VERSION "dbc-export 1 2026.26.6.5"

NS_ :

BS_:

BU_: BB GTW IDB TCU TCU2 UI UIS VCSEAT2L VCSEAT2R

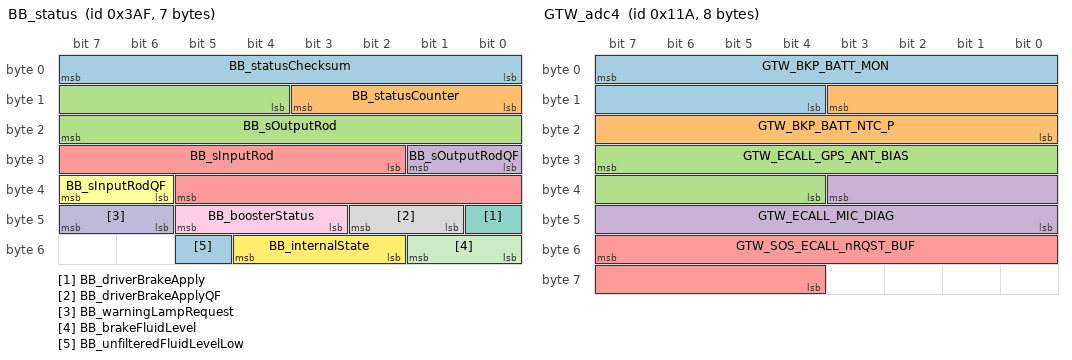
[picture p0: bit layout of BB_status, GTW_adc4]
BO_ 943 BB_status: 7 BB
 SG_ BB_statusChecksum : 0|8@1+ (1,0) [0|255] "" Vector__XXX
 SG_ BB_statusCounter : 8|4@1+ (1,0) [0|15] "" Vector__XXX
 SG_ BB_sOutputRod : 12|12@1+ (0.015625,-5) [-5|47] "mm" Vector__XXX
 SG_ BB_sOutputRodQF : 24|2@1+ (1,0) [0|3] "" Vector__XXX
 SG_ BB_sInputRod : 26|12@1+ (0.015625,-5) [-5|47] "mm" Vector__XXX
 SG_ BB_sInputRodQF : 38|2@1+ (1,0) [0|3] "" Vector__XXX
 SG_ BB_driverBrakeApply : 40|1@1+ (1,0) [0|1] "" Vector__XXX
 SG_ BB_driverBrakeApplyQF : 41|2@1+ (1,0) [0|3] "" Vector__XXX
 SG_ BB_boosterStatus : 43|3@1+ (1,0) [0|7] "" Vector__XXX
 SG_ BB_warningLampRequest : 46|2@1+ (1,0) [0|3] "" Vector__XXX
 SG_ BB_brakeFluidLevel : 48|2@1+ (1,0) [0|3] "" Vector__XXX
 SG_ BB_internalState : 50|3@1+ (1,0) [0|7] "" Vector__XXX
 SG_ BB_unfilteredFluidLevelLow : 53|1@1+ (1,0) [0|1] "" Vector__XXX

BO_ 888 GTW_ECall: 1 GTW
 SG_ GTW_GTW_SOS_ECALL_RQST : 0|1@1+ (1,0) [0|1] "" Vector__XXX
 SG_ GTW_LTE_ECALL_LOCK : 1|1@1+ (1,0) [0|1] "" Vector__XXX

BO_ 282 GTW_adc4: 8 GTW
 SG_ GTW_BKP_BATT_MON : 7|12@0+ (1,0) [0|4094] "mV" Vector__XXX
 SG_ GTW_BKP_BATT_NTC_P : 11|12@0+ (1,0) [0|4094] "mV" Vector__XXX
 SG_ GTW_ECALL_GPS_ANT_BIAS : 31|12@0+ (1,0) [0|4094] "mV" Vector__XXX
 SG_ GTW_ECALL_MIC_DIAG : 35|12@0+ (1,0) [0|4094] "mV" Vector__XXX
 SG_ GTW_SOS_ECALL_nRQST_BUF : 55|12@0+ (1,0) [0|4094] "mV" Vector__XXX

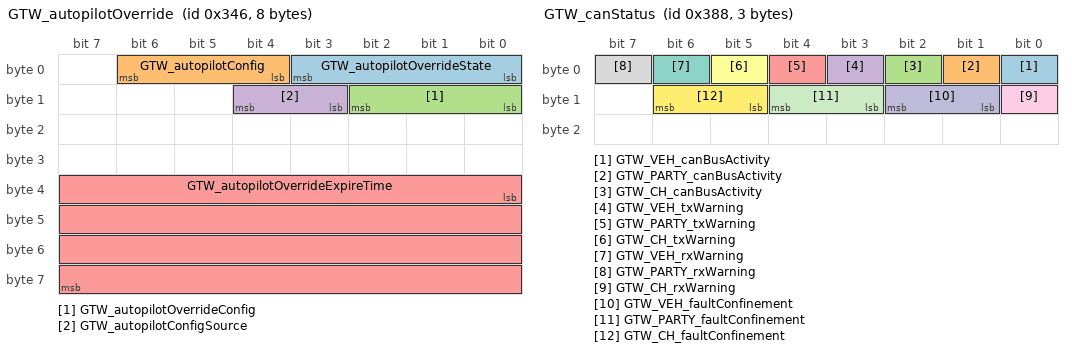
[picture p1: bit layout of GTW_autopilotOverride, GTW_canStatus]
BO_ 838 GTW_autopilotOverride: 8 GTW
 SG_ GTW_autopilotOverrideState : 0|4@1+ (1,0) [0|15] "" Vector__XXX
 SG_ GTW_autopilotConfig : 4|3@1+ (1,0) [0|7] "" Vector__XXX
 SG_ GTW_autopilotOverrideConfig : 8|3@1+ (1,0) [0|7] "" Vector__XXX
 SG_ GTW_autopilotConfigSource : 11|2@1+ (1,0) [0|3] "" Vector__XXX
 SG_ GTW_autopilotOverrideExpireTime : 32|32@1+ (1,0) [0|4294967295] "" Vector__XXX

BO_ 904 GTW_canStatus: 3 GTW
 SG_ GTW_VEH_canBusActivity : 0|1@1+ (1,0) [0|1] "" Vector__XXX
 SG_ GTW_PARTY_canBusActivity : 1|1@1+ (1,0) [0|1] "" Vector__XXX
 SG_ GTW_CH_canBusActivity : 2|1@1+ (1,0) [0|1] "" Vector__XXX
 SG_ GTW_VEH_txWarning : 3|1@1+ (1,0) [0|1] "" Vector__XXX
 SG_ GTW_PARTY_txWarning : 4|1@1+ (1,0) [0|1] "" Vector__XXX
 SG_ GTW_CH_txWarning : 5|1@1+ (1,0) [0|1] "" Vector__XXX
 SG_ GTW_VEH_rxWarning : 6|1@1+ (1,0) [0|1] "" Vector__XXX
 SG_ GTW_PARTY_rxWarning : 7|1@1+ (1,0) [0|1] "" Vector__XXX
 SG_ GTW_CH_rxWarning : 8|1@1+ (1,0) [0|1] "" Vector__XXX
 SG_ GTW_VEH_faultConfinement : 9|2@1+ (1,0) [0|3] "" Vector__XXX
 SG_ GTW_PARTY_faultConfinement : 11|2@1+ (1,0) [0|3] "" Vector__XXX
 SG_ GTW_CH_faultConfinement : 13|2@1+ (1,0) [0|3] "" Vector__XXX

BO_ 2047 GTW_carConfig: 8 GTW
 SG_ GTW_carConfigMultiplexer M : 0|8@1+ (1,0) [0|255] "" Vector__XXX
 SG_ GTW_deliveryStatus m1 : 8|1@1+ (1,0) [0|1] "" Vector__XXX
 SG_ GTW_cabinPTCHeaterType m1 : 10|1@1+ (1,0) [0|1] "" Vector__XXX
 SG_ GTW_rightHandDrive m1 : 11|1@1+ (1,0) [0|1] "" Vector__XXX
 SG_ GTW_rearLightType m1 : 12|2@1+ (1,0) [0|3] "" Vector__XXX
 SG_ GTW_headlamps m1 : 14|2@1+ (1,0) [0|3] "" Vector__XXX
 SG_ GTW_country m1 : 16|16@1+ (1,0) [0|65535] "" Vector__XXX
 SG_ GTW_tireType m1 : 32|6@1+ (1,0) [0|63] "" Vector__XXX
 SG_ GTW_dasHw m1 : 40|3@1+ (1,0) [3|5] "" Vector__XXX
 SG_ GTW_brakeHWType m1 : 43|5@1+ (1,0) [0|31] "" Vector__XXX
 SG_ GTW_restraintsHardwareType m1 : 48|8@1+ (1,0) [0|255] "" Vector__XXX
 SG_ GTW_drivetrainType m1 : 56|4@1+ (1,0) [0|4] "" Vector__XXX
 SG_ GTW_radarHeaterType m1 : 60|3@1+ (1,0) [0|5] "" Vector__XXX
 SG_ GTW_exteriorTrimType m2 : 8|1@1+ (1,0) [0|1] "" Vector__XXX
 SG_ GTW_frontSeatHeaters m2 : 9|1@1+ (1,0) [0|1] "" Vector__XXX
 SG_ GTW_rearSeatHeaters m2 : 10|1@1+ (1,0) [0|1] "" Vector__XXX
 SG_ GTW_eCallAntennaHW m2 : 12|1@1+ (1,0) [0|1] "" Vector__XXX
 SG_ GTW_homelinkType m2 : 13|1@1+ (1,0) [0|1] "" Vector__XXX
 SG_ GTW_vdcType m2 : 14|1@1+ (1,0) [0|1] "" Vector__XXX
 SG_ GTW_memoryMirrors m2 : 17|1@1+ (1,0) [0|1] "" Vector__XXX
 SG_ GTW_powerLiftgateType m2 : 18|2@1+ (1,0) [0|2] "" Vector__XXX
 SG_ GTW_lumbarECUType m2 : 20|4@1+ (1,0) [0|15] "" Vector__XXX
 SG_ GTW_rearSeatHeaterType m2 : 24|2@1+ (1,0) [0|3] "" Vector__XXX
 SG_ GTW_auxParkLamps m2 : 26|2@1+ (1,0) [0|3] "" Vector__XXX
 SG_ GTW_interiorCabinRadarType m2 : 28|1@1+ (1,0) [0|1] "" Vector__XXX
 SG_ GTW_hvacPanelVaneType m2 : 29|1@1+ (1,0) [0|1] "" Vector__XXX
 SG_ GTW_intakeAirFilterType m2 : 30|2@1+ (1,0) [0|2] "" Vector__XXX
 SG_ GTW_eBuckConfig m2 : 32|1@1+ (1,0) [0|1] "" Vector__XXX
 SG_ GTW_steeringHeaterEnabled m2 : 33|1@1+ (1,0) [0|1] "" Vector__XXX
 SG_ GTW_activeHighBeam m2 : 34|1@1+ (1,0) [0|1] "" Vector__XXX
 SG_ GTW_airbagCutoffSwitch m2 : 35|1@1+ (1,0) [0|1] "" Vector__XXX
 SG_ GTW_intrusionSensorType m2 : 36|1@1+ (1,0) [0|1] "" Vector__XXX
 SG_ GTW_spoilerType m2 : 37|1@1+ (1,0) [0|1] "" Vector__XXX
 SG_ GTW_backupCameraType m2 : 38|1@1+ (1,0) [0|1] "" Vector__XXX
 SG_ GTW_rearFogLamps m2 : 39|1@1+ (1,0) [0|1] "" Vector__XXX
 SG_ GTW_roofType m2 : 40|1@1+ (1,0) [0|1] "" Vector__XXX
 SG_ GTW_thirdRowSeatType m2 : 41|1@1+ (1,0) [0|1] "" Vector__XXX
 SG_ GTW_autopilot m2 : 42|3@1+ (1,0) [0|7] "" Vector__XXX
 SG_ GTW_superchargingAccess m2 : 45|2@1+ (1,0) [0|3] "" Vector__XXX
 SG_ GTW_exteriorColor m2 : 48|5@1+ (1,0) [0|31] "" Vector__XXX
 SG_ GTW_pedestrianWarningSound m2 : 53|2@1+ (1,0) [0|3] "" Vector__XXX
 SG_ GTW_steeringColumnUJointType m2 : 55|1@1+ (1,0) [0|1] "" Vector__XXX
 SG_ GTW_bPillarNFCParam m2 : 56|1@1+ (1,0) [0|1] "" Vector__XXX
 SG_ GTW_interiorLighting m2 : 57|3@1+ (1,0) [0|7] "" Vector__XXX
 SG_ GTW_headlightLevelerType m2 : 60|2@1+ (1,0) [0|3] "" Vector__XXX
 SG_ GTW_numberHVILNodes m2 : 62|2@1+ (1,0) [0|3] "" Vector__XXX
 SG_ GTW_mapRegion m3 : 8|4@1+ (1,0) [0|15] "" Vector__XXX
 SG_ GTW_performancePackage m3 : 12|3@1+ (1,0) [0|7] "" Vector__XXX
 SG_ GTW_chassisType m3 : 18|4@1+ (1,0) [0|15] "" Vector__XXX
 SG_ GTW_airSuspension m3 : 22|2@1+ (1,0) [0|3] "" Vector__XXX
 SG_ GTW_centerConsoleControllerType m3 : 24|2@1+ (1,0) [0|3] "" Vector__XXX
 SG_ GTW_autopilotCameraType m3 : 26|1@1+ (1,0) [0|1] "" Vector__XXX
 SG_ GTW_connectivityPackage m3 : 27|1@1+ (1,0) [0|1] "" Vector__XXX
 SG_ GTW_plcSupportType m3 : 28|2@1+ (1,0) [0|3] "" Vector__XXX
 SG_ GTW_badgingVersion m3 : 30|2@1+ (1,0) [0|3] "" Vector__XXX
 SG_ GTW_packEnergy m3 : 32|5@1+ (1,0) [0|31] "" Vector__XXX
 SG_ GTW_frontSeatReclinerHardware m3 : 37|2@1+ (1,0) [0|3] "" Vector__XXX
 SG_ GTW_brakeLineSwitchType m3 : 39|1@1+ (1,0) [0|1] "" Vector__XXX
 SG_ GTW_softRange m3 : 42|3@1+ (1,0) [0|7] "" Vector__XXX
 SG_ GTW_refrigerantType m3 : 45|2@1+ (1,0) [0|3] "" Vector__XXX
 SG_ GTW_wheelType m3 : 48|7@1+ (1,0) [0|127] "" Vector__XXX
 SG_ GTW_brakeActuationType m3 : 57|3@1+ (1,0) [0|4] "" Vector__XXX
 SG_ GTW_secondRowSeatType m3 : 60|3@1+ (1,0) [0|7] "" Vector__XXX
 SG_ GTW_secondRowSeatMotorType m3 : 63|1@1+ (1,0) [0|1] "" Vector__XXX
 SG_ GTW_birthday m4 : 8|32@1+ (1,0) [0|4294967295] "" Vector__XXX
 SG_ GTW_eCallEnabled m4 : 40|2@1+ (1,0) [0|3] "" Vector__XXX
 SG_ GTW_parkAssistECUType m4 : 42|2@1+ (1,0) [0|3] "" Vector__XXX
 SG_ GTW_passengerAirbagType m4 : 44|2@1+ (1,0) [0|3] "" Vector__XXX
 SG_ GTW_forwardRadarHw m4 : 46|2@1+ (1,0) [0|2] "" Vector__XXX
 SG_ GTW_frontSeatType m4 : 48|4@1+ (1,0) [0|15] "" Vector__XXX
 SG_ GTW_secondRowDisplayType m4 : 52|1@1+ (1,0) [0|1] "" Vector__XXX
 SG_ GTW_wirelessPhoneChargerType m4 : 53|2@1+ (1,0) [0|3] "" Vector__XXX
 SG_ GTW_ethernetTunerType m4 : 55|2@1+ (1,0) [0|3] "" Vector__XXX
 SG_ GTW_interiorTrimType m4 : 60|4@1+ (1,0) [0|15] "" Vector__XXX
 SG_ GTW_gloveboxUSBType m5 : 8|2@1+ (1,0) [0|3] "" Vector__XXX
 SG_ GTW_coolantPumpType m5 : 10|3@1+ (1,0) [0|7] "" Vector__XXX
 SG_ GTW_epblHwType m5 : 13|4@1+ (1,0) [0|15] "" Vector__XXX
 SG_ GTW_epbrHwType m5 : 17|4@1+ (1,0) [0|15] "" Vector__XXX
 SG_ GTW_blowerMotorType m5 : 21|2@1+ (1,0) [0|3] "" Vector__XXX
 SG_ GTW_powerMirrorFoldType m5 : 24|1@1+ (1,0) [0|1] "" Vector__XXX
 SG_ GTW_frontUsbHubType m5 : 27|3@1+ (1,0) [0|5] "" Vector__XXX
 SG_ GTW_superManifoldType m5 : 30|2@1+ (1,0) [0|3] "" Vector__XXX
 SG_ GTW_rcmLocation m5 : 32|1@1+ (1,0) [0|1] "" Vector__XXX
 SG_ GTW_autopilotExteriorCameraType m5 : 33|1@1+ (1,0) [0|1] "" Vector__XXX
 SG_ GTW_sirenType m5 : 37|1@1+ (1,0) [0|1] "" Vector__XXX
 SG_ GTW_hornType m5 : 38|1@1+ (1,0) [0|1] "" Vector__XXX
 SG_ GTW_passengerTrackMotorType m5 : 40|1@1+ (1,0) [0|1] "" Vector__XXX
 SG_ GTW_steeringColumnMotorType m5 : 42|2@1+ (1,0) [0|3] "" Vector__XXX
 SG_ GTW_refrigACLineType m5 : 48|2@1+ (1,0) [0|3] "" Vector__XXX
 SG_ GTW_refrigFilterType m5 : 50|2@1+ (1,0) [0|3] "" Vector__XXX
 SG_ GTW_diBurnInType m5 : 52|1@1+ (1,0) [0|1] "" Vector__XXX
 SG_ GTW_specialBadgingType m5 : 53|2@1+ (1,0) [0|3] "" Vector__XXX
 SG_ GTW_chassisSubType m5 : 55|3@1+ (1,0) [0|7] "" Vector__XXX
 SG_ GTW_towPackage m5 : 58|2@1+ (1,0) [0|3] "" Vector__XXX
 SG_ GTW_refrigLccType m5 : 60|1@1+ (1,0) [0|1] "" Vector__XXX
 SG_ GTW_restraintControlsType m5 : 61|1@1+ (1,0) [0|1] "" Vector__XXX
 SG_ GTW_caliperColorType m5 : 62|2@1+ (1,0) [0|3] "" Vector__XXX
 SG_ GTW_wiperMotorType m6 : 9|1@1+ (1,0) [0|1] "" Vector__XXX
 SG_ GTW_frontOverheadConsoleType m6 : 10|2@1+ (1,0) [0|3] "" Vector__XXX
 SG_ GTW_shifterType m6 : 12|1@1+ (1,0) [0|1] "" Vector__XXX
 SG_ GTW_compressorType m6 : 13|4@1+ (1,0) [0|15] "" Vector__XXX
 SG_ GTW_twelveVBatteryType m6 : 17|3@1+ (1,0) [0|7] "" Vector__XXX
 SG_ GTW_efuseSWConfig m6 : 20|3@1+ (1,0) [0|7] "" Vector__XXX
 SG_ GTW_tollCollectionModuleType m6 : 23|1@1+ (1,0) [0|1] "" Vector__XXX
 SG_ GTW_bleEndpointUpdateMethod m6 : 24|1@1+ (1,0) [0|1] "" Vector__XXX
 SG_ GTW_steeringWheelControllerType m6 : 25|3@1+ (1,0) [0|7] "" Vector__XXX
 SG_ GTW_frontSeatVentilationEnabled m6 : 28|1@1+ (1,0) [0|1] "" Vector__XXX
 SG_ GTW_gloveboxActuatorType m6 : 29|2@1+ (1,0) [0|3] "" Vector__XXX
 SG_ GTW_epasType m6 : 32|4@1+ (1,0) [0|11] "" Vector__XXX
 SG_ GTW_homologationRegionOverride m6 : 36|2@1+ (1,0) [0|3] "" Vector__XXX
 SG_ GTW_windowCommandsPermissionType m6 : 38|2@1+ (1,0) [0|3] "" Vector__XXX
 SG_ GTW_rgbInteriorLightingEnabled m6 : 43|2@1+ (1,0) [0|3] "" Vector__XXX
 SG_ GTW_windshieldWiperHeaterType m6 : 45|1@1+ (1,0) [0|1] "" Vector__XXX
 SG_ GTW_thirdRowSeatReclinerType m6 : 46|1@1+ (1,0) [0|1] "" Vector__XXX
 SG_ GTW_driveInterfaceType m6 : 47|1@1+ (1,0) [0|1] "" Vector__XXX
 SG_ GTW_efficiencyPackage m6 : 49|6@1+ (1,0) [0|63] "" Vector__XXX
 SG_ GTW_visorLightType m6 : 55|1@1+ (1,0) [0|1] "" Vector__XXX
 SG_ GTW_gnssAntennaType m6 : 58|2@1+ (1,0) [0|3] "" Vector__XXX
 SG_ GTW_airDistributionBoxType m6 : 60|1@1+ (1,0) [0|1] "" Vector__XXX
 SG_ GTW_frontSeatHeatersEnabled m6 : 62|1@1+ (1,0) [0|1] "" Vector__XXX
 SG_ GTW_windshieldWiperHeaterEnabled m6 : 63|1@1+ (1,0) [0|1] "" Vector__XXX
 SG_ GTW_alcoholInterlockType m7 : 8|1@1+ (1,0) [0|1] "" Vector__XXX
 SG_ GTW_fasciaType m7 : 9|4@1+ (1,0) [0|15] "" Vector__XXX
 SG_ GTW_powerSteeringColumn m7 : 13|1@1+ (1,0) [0|1] "" Vector__XXX
 SG_ GTW_frontSeatHeaterType m7 : 14|1@1+ (1,0) [0|1] "" Vector__XXX
 SG_ GTW_softPerformanceLimit m7 : 15|4@1+ (1,0) [0|15] "" Vector__XXX
 SG_ GTW_gsrFeatureType m7 : 21|2@1+ (1,0) [0|2] "" Vector__XXX
 SG_ GTW_immersiveAudio m7 : 23|2@1+ (1,0) [0|3] "" Vector__XXX
 SG_ GTW_frontSeatVentilationType m7 : 25|1@1+ (1,0) [0|1] "" Vector__XXX
 SG_ GTW_passengerOccupancySensorType m7 : 26|3@1+ (1,0) [0|7] "" Vector__XXX
 SG_ GTW_packPerformanceDeviation m7 : 30|3@1+ (1,0) [0|7] "" Vector__XXX
 SG_ GTW_frontFogLamps m7 : 35|1@1+ (1,0) [0|1] "" Vector__XXX
 SG_ GTW_driverOccupancySensorType m7 : 36|1@1+ (1,0) [0|1] "" Vector__XXX
 SG_ GTW_audioType m7 : 37|3@1+ (1,0) [0|7] "" Vector__XXX
 SG_ GTW_thighExtenderType m7 : 41|1@1+ (1,0) [0|1] "" Vector__XXX
 SG_ GTW_occupancyClassificationFeatu m7 : 42|1@1+ (1,0) [0|1] "" Vector__XXX
 SG_ GTW_frontControllerArchitectureT m7 : 46|1@1+ (1,0) [0|1] "" Vector__XXX
 SG_ GTW_domeLightType m7 : 47|2@1+ (1,0) [0|3] "" Vector__XXX
 SG_ GTW_tpmsType m7 : 49|2@1+ (1,0) [0|3] "" Vector__XXX
 SG_ GTW_authenticationEndpointLayout m7 : 52|3@1+ (1,0) [0|6] "" Vector__XXX
 SG_ GTW_socSleepOverride m7 : 57|2@1+ (1,0) [0|3] "" Vector__XXX
 SG_ GTW_r79BehaviorOverride m7 : 59|1@1+ (1,0) [0|1] "" Vector__XXX
 SG_ GTW_steeringHeaterType m7 : 60|3@1+ (1,0) [0|7] "" Vector__XXX
 SG_ GTW_narrowWipingSupported m7 : 63|1@1+ (1,0) [0|1] "" Vector__XXX
 SG_ GTW_frontSeatHeaterGridType m8 : 8|1@1+ (1,0) [0|1] "" Vector__XXX
 SG_ GTW_frontSeatSideSwitchType m8 : 9|1@1+ (1,0) [0|1] "" Vector__XXX
 SG_ GTW_sohRegulatoryStatus m8 : 10|1@1+ (1,0) [0|1] "" Vector__XXX
 SG_ GTW_passengerTiltMotorType m8 : 11|2@1+ (1,0) [0|3] "" Vector__XXX
 SG_ GTW_frunkInteriorReleaseType m8 : 15|1@1+ (1,0) [0|1] "" Vector__XXX
 SG_ GTW_m3yBusArchitecture m8 : 17|2@1+ (1,0) [0|3] "" Vector__XXX
 SG_ GTW_passengerLiftMotorType m8 : 19|2@1+ (1,0) [0|3] "" Vector__XXX
 SG_ GTW_interiorUpperTrimType m8 : 21|1@1+ (1,0) [0|1] "" Vector__XXX
 SG_ GTW_blindSpotIndicatorLightType m8 : 22|2@1+ (1,0) [0|3] "" Vector__XXX
 SG_ GTW_wiperMotorAsicType m8 : 24|2@1+ (1,0) [0|3] "" Vector__XXX
 SG_ GTW_hvacCaseDoorType m8 : 28|1@1+ (1,0) [0|1] "" Vector__XXX
 SG_ GTW_rduCableType m8 : 31|1@1+ (1,0) [0|1] "" Vector__XXX
 SG_ GTW_parkTelltaleBehaviorType m8 : 32|1@1+ (1,0) [0|1] "" Vector__XXX
 SG_ GTW_numberKeyCardsPairedInFactor m8 : 35|2@1+ (1,0) [0|2] "" Vector__XXX
 SG_ GTW_secondRowSeatVentilationType m8 : 37|1@1+ (1,0) [0|1] "" Vector__XXX
 SG_ GTW_thirdRowSeatHeaterType m8 : 38|1@1+ (1,0) [0|1] "" Vector__XXX
 SG_ GTW_interiorCameraType m8 : 39|2@1+ (1,0) [0|2] "" Vector__XXX
 SG_ GTW_frontFasciaCameraType m8 : 41|2@1+ (1,0) [0|3] "" Vector__XXX
 SG_ GTW_interiorCamFanType m8 : 45|3@1+ (1,0) [0|7] "" Vector__XXX
 SG_ GTW_puddleLampType m8 : 50|2@1+ (1,0) [0|2] "" Vector__XXX
 SG_ GTW_solarLensType m8 : 52|2@1+ (1,0) [0|2] "" Vector__XXX
 SG_ GTW_liftgateGeometryType m8 : 56|2@1+ (1,0) [0|3] "" Vector__XXX
 SG_ GTW_repeaterAeroRibType m8 : 60|3@1+ (1,0) [0|7] "" Vector__XXX
 SG_ GTW_highTipForceWiperArmsType m8 : 63|1@1+ (1,0) [0|1] "" Vector__XXX
 SG_ GTW_rcmUndersideAbuseZThreshold m9 : 8|3@1+ (1,0) [0|7] "" Vector__XXX
 SG_ GTW_rcmUndersideAbuseYThreshold m9 : 11|3@1+ (1,0) [0|7] "" Vector__XXX
 SG_ GTW_rcmUndersideAbuseWindow m9 : 14|2@1+ (1,0) [0|3] "" Vector__XXX
 SG_ GTW_automaticFeatureResetPackage m9 : 18|1@1+ (1,0) [0|1] "" Vector__XXX
 SG_ GTW_autopilotFeaturePackage m9 : 20|2@1+ (1,0) [0|2] "" Vector__XXX
 SG_ GTW_doorLatchType m9 : 23|1@1+ (1,0) [0|1] "" Vector__XXX
 SG_ GTW_headlinerMaterialType m9 : 25|2@1+ (1,0) [0|3] "" Vector__XXX
 SG_ GTW_glareShieldHeaterType m9 : 27|1@1+ (1,0) [0|1] "" Vector__XXX
 SG_ GTW_rearLightHardwareVariant m9 : 29|2@1+ (1,0) [0|3] "" Vector__XXX
 SG_ GTW_fasciaHarnessCleanPointType m9 : 31|2@1+ (1,0) [0|3] "" Vector__XXX
 SG_ GTW_epasSubType m9 : 33|1@1+ (1,0) [0|1] "" Vector__XXX
 SG_ GTW_wiperSupplyChainOrigin m9 : 35|2@1+ (1,0) [1|3] "" Vector__XXX
 SG_ GTW_windowPinchParameterType m9 : 37|2@1+ (1,0) [0|3] "" Vector__XXX
 SG_ GTW_badgingMaterialType m9 : 39|1@1+ (1,0) [0|1] "" Vector__XXX
 SG_ GTW_mRecordVersion m9 : 40|1@1+ (1,0) [0|1] "" Vector__XXX
 SG_ GTW_tcuType m9 : 47|2@1+ (1,0) [0|2] "" Vector__XXX
 SG_ GTW_carbComplianceBehaviorType m9 : 49|1@1+ (1,0) [0|1] "" Vector__XXX
 SG_ GTW_indirectTPMSCalibrationType m9 : 55|3@1+ (1,0) [0|7] "" Vector__XXX
 SG_ GTW_v2xEnabled m9 : 58|1@1+ (1,0) [0|1] "" Vector__XXX
 SG_ GTW_liftgateStrutType m9 : 60|1@1+ (1,0) [0|1] "" Vector__XXX
 SG_ GTW_exteriorMicrophoneType m9 : 63|1@1+ (1,0) [0|1] "" Vector__XXX
 SG_ GTW_roofGlassType m10 : 21|3@1+ (1,0) [0|7] "" Vector__XXX
 SG_ GTW_pedalMapNameOverride m10 : 25|1@1+ (1,0) [0|1] "" Vector__XXX

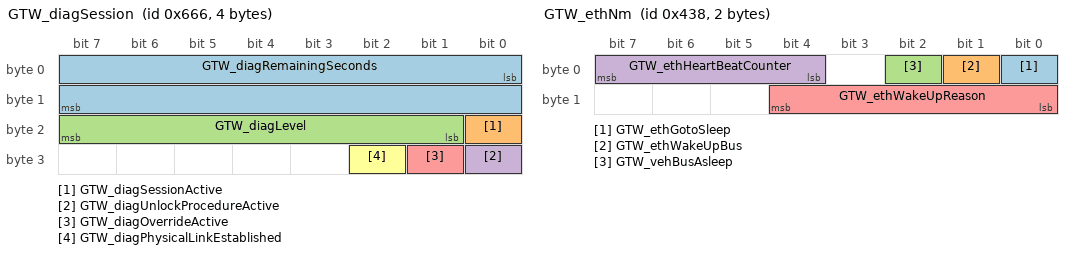
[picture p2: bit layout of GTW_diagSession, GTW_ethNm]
BO_ 1638 GTW_diagSession: 4 GTW
 SG_ GTW_diagRemainingSeconds : 0|16@1+ (1,0) [0|65535] "seconds" Vector__XXX
 SG_ GTW_diagSessionActive : 16|1@1+ (1,0) [0|1] "" Vector__XXX
 SG_ GTW_diagLevel : 17|7@1+ (1,0) [0|127] "" Vector__XXX
 SG_ GTW_diagUnlockProcedureActive : 24|1@1+ (1,0) [0|1] "" Vector__XXX
 SG_ GTW_diagOverrideActive : 25|1@1+ (1,0) [0|1] "" Vector__XXX
 SG_ GTW_diagPhysicalLinkEstablished : 26|1@1+ (1,0) [0|1] "" Vector__XXX

BO_ 1080 GTW_ethNm: 2 GTW
 SG_ GTW_ethGotoSleep : 0|1@1+ (1,0) [0|1] "" Vector__XXX
 SG_ GTW_ethWakeUpBus : 1|1@1+ (1,0) [0|1] "" Vector__XXX
 SG_ GTW_vehBusAsleep : 2|1@1+ (1,0) [0|1] "" Vector__XXX
 SG_ GTW_ethHeartBeatCounter : 4|4@1+ (1,0) [0|15] "" Vector__XXX
 SG_ GTW_ethWakeUpReason : 8|5@1+ (1,0) [0|31] "" Vector__XXX

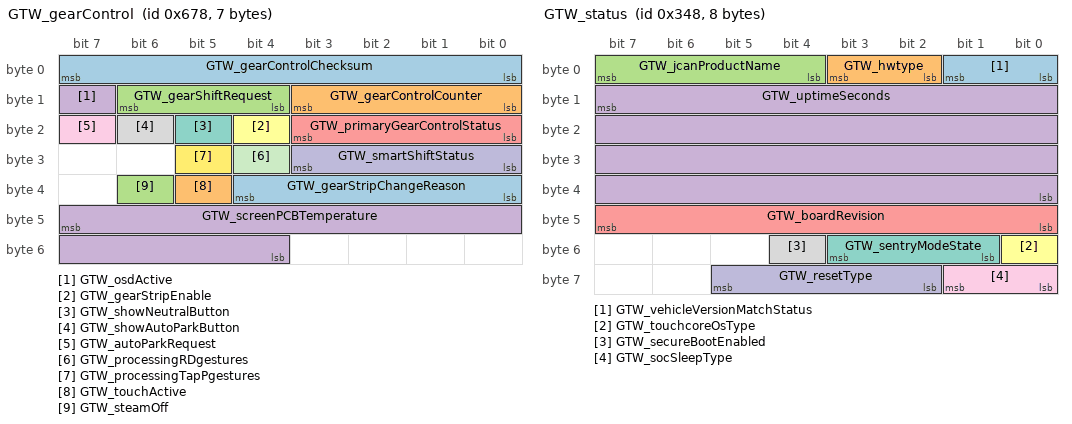
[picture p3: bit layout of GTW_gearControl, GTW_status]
BO_ 1656 GTW_gearControl: 7 GTW
 SG_ GTW_gearControlChecksum : 0|8@1+ (1,0) [0|255] "" Vector__XXX
 SG_ GTW_gearControlCounter : 8|4@1+ (1,0) [0|15] "" Vector__XXX
 SG_ GTW_gearShiftRequest : 12|3@1+ (1,0) [1|7] "" Vector__XXX
 SG_ GTW_osdActive : 15|1@1+ (1,0) [0|1] "" Vector__XXX
 SG_ GTW_primaryGearControlStatus : 16|4@1+ (1,0) [0|15] "" Vector__XXX
 SG_ GTW_gearStripEnable : 20|1@1+ (1,0) [0|1] "" Vector__XXX
 SG_ GTW_showNeutralButton : 21|1@1+ (1,0) [0|1] "" Vector__XXX
 SG_ GTW_showAutoParkButton : 22|1@1+ (1,0) [0|1] "" Vector__XXX
 SG_ GTW_autoParkRequest : 23|1@1+ (1,0) [0|1] "" Vector__XXX
 SG_ GTW_smartShiftStatus : 24|4@1+ (1,0) [1|15] "" Vector__XXX
 SG_ GTW_processingRDgestures : 28|1@1+ (1,0) [0|1] "" Vector__XXX
 SG_ GTW_processingTapPgestures : 29|1@1+ (1,0) [0|1] "" Vector__XXX
 SG_ GTW_gearStripChangeReason : 32|5@1+ (1,0) [1|31] "" Vector__XXX
 SG_ GTW_touchActive : 37|1@1+ (1,0) [0|1] "" Vector__XXX
 SG_ GTW_steamOff : 38|1@1+ (1,0) [0|1] "" Vector__XXX
 SG_ GTW_screenPCBTemperature : 47|12@0- (0.0625,0) [-128|127.875] "degC" Vector__XXX

BO_ 2033 GTW_hrl: 7 GTW
 SG_ GTW_hrlIndex M : 0|2@1+ (1,0) [0|3] "" Vector__XXX
 SG_ GTW_hrlPagesCount m1 : 15|32@0+ (1,0) [0|4294967295] "" Vector__XXX
 SG_ GTW_hrlSdCardSizeGB m1 : 40|8@1+ (1,0) [1|255] "" Vector__XXX
 SG_ GTW_hrlState m2 : 2|1@1+ (1,0) [0|1] "" Vector__XXX
 SG_ GTW_hrlTriggerDuration m2 : 15|16@0+ (1,0) [0|65535] "seconds" Vector__XXX
 SG_ GTW_hrlTriggerType m2 : 24|4@1+ (1,0) [0|15] "" Vector__XXX
 SG_ GTW_hrlTriggerId m2 : 39|16@0+ (1,0) [0|65535] "" Vector__XXX
 SG_ GTW_hrlTriggerBus m2 : 53|3@1+ (1,0) [0|7] "" Vector__XXX

BO_ 2026 GTW_hrlExternalEvent: 8 GTW
 SG_ GTW_hrlEventStartEpoch : 7|32@0+ (1,0) [0|4294967295] "seconds" Vector__XXX
 SG_ GTW_hrlEventEndEpoch : 39|32@0+ (1,0) [0|4294967295] "seconds" Vector__XXX

BO_ 60 GTW_info: 8 GTW
 SG_ GTW_infoIndex M : 0|8@1+ (1,0) [0|255] "" Vector__XXX
 SG_ GTW_buildType m10 : 8|3@1+ (1,0) [0|7] "" Vector__XXX
 SG_ GTW_hardwareId m10 : 32|16@1+ (1,0) [0|65535] "" Vector__XXX
 SG_ GTW_platformType m13 : 8|8@1+ (1,0) [0|255] "" Vector__XXX
 SG_ GTW_appCrc m13 : 32|32@1+ (1,0) [0|4294967295] "" Vector__XXX
 SG_ GTW_applicationGitHash m17 : 8|56@1+ (1,0) [0|7.20575940379e+16] "" Vector__XXX
 SG_ GTW_bootGitHash m18 : 8|56@1+ (1,0) [0|7.20575940379e+16] "" Vector__XXX

BO_ 1370 GTW_mismatchFault: 8 GTW
 SG_ GTW_mismatchFaultIndex M : 0|3@1+ (1,0) [0|7] "" Vector__XXX
 SG_ GTW_mismatchFaultChecksum : 3|8@1+ (1,0) [0|255] "" Vector__XXX
 SG_ GTW_mismatchFaultCounter : 11|4@1+ (1,0) [0|15] "" Vector__XXX
 SG_ GTW_GTWmismatchFault m1 : 15|1@1+ (1,0) [0|1] "" Vector__XXX
 SG_ GTW_BMSmismatchFault m1 : 16|1@1+ (1,0) [0|1] "" Vector__XXX
 SG_ GTW_APSmismatchFault m1 : 17|1@1+ (1,0) [0|1] "" Vector__XXX
 SG_ GTW_BLEEPCENTERmismatchFault m1 : 18|1@1+ (1,0) [0|1] "" Vector__XXX
 SG_ GTW_BLEEPLEFTmismatchFault m1 : 19|1@1+ (1,0) [0|1] "" Vector__XXX
 SG_ GTW_BLEEPREARmismatchFault m1 : 20|1@1+ (1,0) [0|1] "" Vector__XXX
 SG_ GTW_BLEEPRIGHTmismatchFault m1 : 21|1@1+ (1,0) [0|1] "" Vector__XXX
 SG_ GTW_CBCmismatchFault m1 : 22|1@1+ (1,0) [0|1] "" Vector__XXX
 SG_ GTW_CMPmismatchFault m1 : 23|1@1+ (1,0) [0|1] "" Vector__XXX
 SG_ GTW_CPmismatchFault m1 : 24|1@1+ (1,0) [0|1] "" Vector__XXX
 SG_ GTW_DIFmismatchFault m1 : 25|1@1+ (1,0) [0|1] "" Vector__XXX
 SG_ GTW_DIRmismatchFault m1 : 26|1@1+ (1,0) [0|1] "" Vector__XXX
 SG_ GTW_EPAS3PmismatchFault m1 : 27|1@1+ (1,0) [0|1] "" Vector__XXX
 SG_ GTW_EPAS3SmismatchFault m1 : 28|1@1+ (1,0) [0|1] "" Vector__XXX
 SG_ GTW_EPBLmismatchFault m1 : 29|1@1+ (1,0) [0|1] "" Vector__XXX
 SG_ GTW_EPBRmismatchFault m1 : 30|1@1+ (1,0) [0|1] "" Vector__XXX
 SG_ GTW_ESPCALmismatchFault m1 : 31|1@1+ (1,0) [0|1] "" Vector__XXX
 SG_ GTW_ESPmismatchFault m1 : 32|1@1+ (1,0) [0|1] "" Vector__XXX
 SG_ GTW_HCM3LmismatchFault m1 : 33|1@1+ (1,0) [0|1] "" Vector__XXX
 SG_ GTW_HCM3RmismatchFault m1 : 34|1@1+ (1,0) [0|1] "" Vector__XXX
 SG_ GTW_HCMLmismatchFault m1 : 35|1@1+ (1,0) [0|1] "" Vector__XXX
 SG_ GTW_HCMRmismatchFault m1 : 36|1@1+ (1,0) [0|1] "" Vector__XXX
 SG_ GTW_HVPmismatchFault m1 : 37|1@1+ (1,0) [0|1] "" Vector__XXX
 SG_ GTW_IBSTCALmismatchFault m1 : 38|1@1+ (1,0) [0|1] "" Vector__XXX
 SG_ GTW_IBSTmismatchFault m1 : 39|1@1+ (1,0) [0|1] "" Vector__XXX
 SG_ GTW_LVBMSmismatchFault m1 : 40|1@1+ (1,0) [0|1] "" Vector__XXX
 SG_ GTW_OCS1PmismatchFault m1 : 41|1@1+ (1,0) [0|1] "" Vector__XXX
 SG_ GTW_OPCFmismatchFault m1 : 42|1@1+ (1,0) [0|1] "" Vector__XXX
 SG_ GTW_OPCRmismatchFault m1 : 43|1@1+ (1,0) [0|1] "" Vector__XXX
 SG_ GTW_PARKmismatchFault m1 : 44|1@1+ (1,0) [0|1] "" Vector__XXX
 SG_ GTW_PCSCPU2mismatchFault m1 : 45|1@1+ (1,0) [0|1] "" Vector__XXX
 SG_ GTW_PCSmismatchFault m1 : 46|1@1+ (1,0) [0|1] "" Vector__XXX
 SG_ GTW_PMFmismatchFault m1 : 47|1@1+ (1,0) [0|1] "" Vector__XXX
 SG_ GTW_PMRmismatchFault m1 : 48|1@1+ (1,0) [0|1] "" Vector__XXX
 SG_ GTW_PTCmismatchFault m1 : 49|1@1+ (1,0) [0|1] "" Vector__XXX
 SG_ GTW_RCMCALmismatchFault m1 : 50|1@1+ (1,0) [0|1] "" Vector__XXX
 SG_ GTW_RCMmismatchFault m1 : 51|1@1+ (1,0) [0|1] "" Vector__XXX
 SG_ GTW_SCCMmismatchFault m1 : 52|1@1+ (1,0) [0|1] "" Vector__XXX
 SG_ GTW_SDCRmismatchFault m1 : 53|1@1+ (1,0) [0|1] "" Vector__XXX
 SG_ GTW_SWCmismatchFault m1 : 54|1@1+ (1,0) [0|1] "" Vector__XXX
 SG_ GTW_THSmismatchFault m1 : 55|1@1+ (1,0) [0|1] "" Vector__XXX
 SG_ GTW_VCFRONTmismatchFault m1 : 56|1@1+ (1,0) [0|1] "" Vector__XXX
 SG_ GTW_VCLEFTmismatchFault m1 : 57|1@1+ (1,0) [0|1] "" Vector__XXX
 SG_ GTW_VCRIGHTmismatchFault m1 : 58|1@1+ (1,0) [0|1] "" Vector__XXX
 SG_ GTW_VCSECmismatchFault m1 : 59|1@1+ (1,0) [0|1] "" Vector__XXX
 SG_ GTW_PMmismatchFault m1 : 60|1@1+ (1,0) [0|1] "" Vector__XXX

BO_ 840 GTW_status: 8 GTW
 SG_ GTW_vehicleVersionMatchStatus : 0|2@1+ (1,0) [0|3] "" Vector__XXX
 SG_ GTW_hwtype : 2|2@1+ (1,0) [1|3] "" Vector__XXX
 SG_ GTW_jcanProductName : 4|4@1+ (1,0) [1|15] "" Vector__XXX
 SG_ GTW_uptimeSeconds : 15|32@0+ (1,0) [0|4294967295] "s" Vector__XXX
 SG_ GTW_boardRevision : 40|8@1+ (1,0) [0|255] "" Vector__XXX
 SG_ GTW_touchcoreOsType : 48|1@1+ (1,0) [0|1] "" Vector__XXX
 SG_ GTW_sentryModeState : 49|3@1+ (1,0) [0|7] "" Vector__XXX
 SG_ GTW_secureBootEnabled : 52|1@1+ (1,0) [0|1] "" Vector__XXX
 SG_ GTW_socSleepType : 56|2@1+ (1,0) [1|3] "" Vector__XXX
 SG_ GTW_resetType : 58|4@1+ (1,0) [1|15] "" Vector__XXX

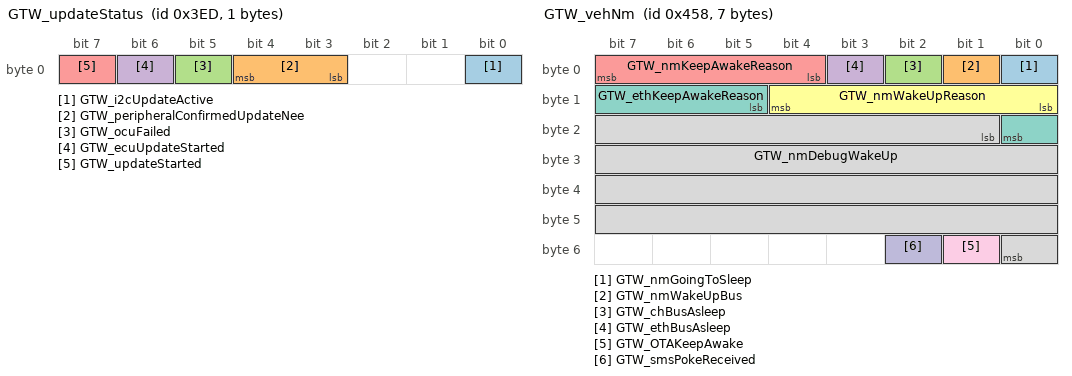
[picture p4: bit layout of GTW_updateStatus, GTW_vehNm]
BO_ 1005 GTW_updateStatus: 1 GTW
 SG_ GTW_i2cUpdateActive : 0|1@1+ (1,0) [0|1] "" Vector__XXX
 SG_ GTW_peripheralConfirmedUpdateNee : 3|2@1+ (1,0) [0|3] "" Vector__XXX
 SG_ GTW_ocuFailed : 5|1@1+ (1,0) [0|1] "" Vector__XXX
 SG_ GTW_ecuUpdateStarted : 6|1@1+ (1,0) [0|1] "" Vector__XXX
 SG_ GTW_updateStarted : 7|1@1+ (1,0) [0|1] "" Vector__XXX

BO_ 1112 GTW_vehNm: 7 GTW
 SG_ GTW_nmGoingToSleep : 0|1@1+ (1,0) [0|1] "" Vector__XXX
 SG_ GTW_nmWakeUpBus : 1|1@1+ (1,0) [0|1] "" Vector__XXX
 SG_ GTW_chBusAsleep : 2|1@1+ (1,0) [0|1] "" Vector__XXX
 SG_ GTW_ethBusAsleep : 3|1@1+ (1,0) [0|1] "" Vector__XXX
 SG_ GTW_nmKeepAwakeReason : 4|4@1+ (1,0) [1|15] "" Vector__XXX
 SG_ GTW_nmWakeUpReason : 8|5@1+ (1,0) [0|31] "" Vector__XXX
 SG_ GTW_ethKeepAwakeReason : 13|4@1+ (1,0) [1|15] "" Vector__XXX
 SG_ GTW_nmDebugWakeUp : 17|32@1+ (1,0) [0|4294967295] "" Vector__XXX
 SG_ GTW_OTAKeepAwake : 49|1@1+ (1,0) [0|1] "" Vector__XXX
 SG_ GTW_smsPokeReceived : 50|1@1+ (1,0) [0|1] "" Vector__XXX

BO_ 828 IDB_info: 8 IDB
 SG_ IDB_infoIndex M : 0|8@1+ (1,0) [0|255] "" Vector__XXX
 SG_ IDB_infoPcbaID m11 : 16|8@1+ (1,0) [0|255] "" Vector__XXX
 SG_ IDB_infoAssemblyID m11 : 24|8@1+ (1,0) [0|255] "" Vector__XXX
 SG_ IDB_infoUsageID m11 : 32|16@1+ (1,0) [0|65535] "" Vector__XXX
 SG_ IDB_infoSubUsageID m11 : 48|16@1+ (1,0) [0|65535] "" Vector__XXX

BO_ 1415 TCU2_SleepConfig: 1 TCU2
 SG_ TCU2_tc10Version : 0|2@1+ (1,0) [1|3] "" Vector__XXX

BO_ 1412 TCU2_log: 8 TCU2
 SG_ TCU2_logMux M : 0|32@1+ (1,0) [0|4294967295] "" Vector__XXX
 SG_ TCU2_cpuTemp m0 : 32|32@1+ (1,0) [0|4294967295] "C" Vector__XXX
 SG_ TCU2_cpuUsage m1 : 32|32@1+ (1,0) [0|4294967295] "%" Vector__XXX
 SG_ TCU2_mdmCoreTemperature m2 : 32|32@1+ (1,0) [0|4294967295] "C" Vector__XXX
 SG_ TCU2_availableMemory m3 : 32|32@1+ (1,0) [0|4294967295] "KB" Vector__XXX
 SG_ TCU2_pwm m4 : 32|32@1+ (1,0) [0|4294967295] "" Vector__XXX
 SG_ TCU2_pwmcap m5 : 32|32@1+ (1,0) [0|4294967295] "" Vector__XXX
 SG_ TCU2_totalResumes m6 : 32|32@1+ (1,0) [0|4294967295] "" Vector__XXX
 SG_ TCU2_mdmUplinkQueueSize m7 : 32|32@1+ (1,0) [0|4294967295] "bytes" Vector__XXX
 SG_ TCU2_mdmRSRP m8 : 32|32@1- (1,0) [-2147483648|2147483647] "dBm" Vector__XXX
 SG_ TCU2_mdmSINR m9 : 32|32@1- (1,0) [-2147483648|2147483647] "dBm" Vector__XXX
 SG_ TCU2_mdmUplinkAllowedRate m10 : 32|32@1+ (1,0) [0|4294967295] "Kbps" Vector__XXX
 SG_ TCU2_mdmUplinkAvgRate m11 : 32|32@1+ (1,0) [0|4294967295] "Kbps" Vector__XXX
 SG_ TCU2_mdmServiceState m12 : 32|32@1+ (1,0) [0|4294967295] "" Vector__XXX
 SG_ TCU2_mdmIMSStatus m13 : 32|32@1+ (1,0) [0|4294967295] "" Vector__XXX
 SG_ TCU2_mdmSIMStatus m14 : 32|32@1+ (1,0) [0|4294967295] "" Vector__XXX
 SG_ TCU2_mdmBusyActive m15 : 32|32@1+ (1,0) [0|4294967294] "" Vector__XXX
 SG_ TCU2_modemUptime m16 : 32|32@1+ (1,0) [0|4294967295] "" Vector__XXX
 SG_ TCU2_mdmDataRat m17 : 32|3@1+ (1,0) [0|7] "" Vector__XXX
 SG_ TCU2_mdmDataCallStatus m18 : 32|3@1+ (1,0) [0|7] "" Vector__XXX
 SG_ TCU2_mdmNSAAvailable m19 : 32|2@1+ (1,0) [0|3] "" Vector__XXX
 SG_ TCU2_mdmPCIID m20 : 32|32@1+ (1,0) [0|4294967295] "" Vector__XXX
 SG_ TCU2_mdmMnc m21 : 32|32@1+ (1,0) [0|4294967295] "" Vector__XXX
 SG_ TCU2_mdmMcc m22 : 32|32@1+ (1,0) [0|4294967295] "" Vector__XXX
 SG_ TCU2_mdmTxKiloBytes m23 : 32|32@1+ (1,0) [0|4294967295] "KB" Vector__XXX
 SG_ TCU2_mdmDataCallTermReason m24 : 32|32@1+ (1,0) [0|4294967295] "" Vector__XXX
 SG_ TCU2_mdmDataCallTermCode m25 : 32|32@1+ (1,0) [0|4294967295] "" Vector__XXX
 SG_ TCU2_cellularSMState m26 : 32|32@1+ (1,0) [0|4294967295] "" Vector__XXX
 SG_ TCU2_tcuSMState m27 : 32|32@1+ (1,0) [0|4294967295] "" Vector__XXX
 SG_ TCU2_checkInternetFailCount m28 : 32|32@1+ (1,0) [0|4294967295] "" Vector__XXX
 SG_ TCU2_mdmBand m29 : 32|32@1+ (1,0) [0|4294967295] "" Vector__XXX
 SG_ TCU2_wakeSource m30 : 32|2@1+ (1,0) [0|3] "" Vector__XXX

BO_ 1159 TCU_SleepConfig: 1 TCU
 SG_ TCU_tc10Version : 0|2@1+ (1,0) [1|3] "" Vector__XXX

BO_ 1155 TCU_log: 8 TCU
 SG_ TCU_logMux M : 0|32@1+ (1,0) [0|4294967295] "" Vector__XXX
 SG_ TCU_cpuTemp m0 : 32|32@1+ (1,0) [0|4294967295] "C" Vector__XXX
 SG_ TCU_cpuUsage m1 : 32|32@1+ (1,0) [0|4294967295] "%" Vector__XXX
 SG_ TCU_mdmCoreTemperature m2 : 32|32@1+ (1,0) [0|4294967295] "C" Vector__XXX
 SG_ TCU_availableMemory m3 : 32|32@1+ (1,0) [0|4294967295] "KB" Vector__XXX
 SG_ TCU_pwm m4 : 32|32@1+ (1,0) [0|4294967295] "" Vector__XXX
 SG_ TCU_pwmcap m5 : 32|32@1+ (1,0) [0|4294967295] "" Vector__XXX
 SG_ TCU_totalResumes m6 : 32|32@1+ (1,0) [0|4294967295] "" Vector__XXX
 SG_ TCU_mdmUplinkQueueSize m7 : 32|32@1+ (1,0) [0|4294967295] "bytes" Vector__XXX
 SG_ TCU_mdmRSRP m8 : 32|32@1- (1,0) [-2147483648|2147483647] "dBm" Vector__XXX
 SG_ TCU_mdmSINR m9 : 32|32@1- (1,0) [-2147483648|2147483647] "dBm" Vector__XXX
 SG_ TCU_mdmUplinkAllowedRate m10 : 32|32@1+ (1,0) [0|4294967295] "Kbps" Vector__XXX
 SG_ TCU_mdmUplinkAvgRate m11 : 32|32@1+ (1,0) [0|4294967295] "Kbps" Vector__XXX
 SG_ TCU_mdmServiceState m12 : 32|32@1+ (1,0) [0|4294967295] "" Vector__XXX
 SG_ TCU_mdmIMSStatus m13 : 32|32@1+ (1,0) [0|4294967295] "" Vector__XXX
 SG_ TCU_mdmSIMStatus m14 : 32|32@1+ (1,0) [0|4294967295] "" Vector__XXX
 SG_ TCU_mdmBusyActive m15 : 32|32@1+ (1,0) [0|4294967294] "" Vector__XXX
 SG_ TCU_modemUptime m16 : 32|32@1+ (1,0) [0|4294967295] "" Vector__XXX
 SG_ TCU_mdmDataRat m17 : 32|3@1+ (1,0) [0|7] "" Vector__XXX
 SG_ TCU_mdmDataCallStatus m18 : 32|3@1+ (1,0) [0|7] "" Vector__XXX
 SG_ TCU_mdmNSAAvailable m19 : 32|2@1+ (1,0) [0|3] "" Vector__XXX
 SG_ TCU_mdmPCIID m20 : 32|32@1+ (1,0) [0|4294967295] "" Vector__XXX
 SG_ TCU_mdmMnc m21 : 32|32@1+ (1,0) [0|4294967295] "" Vector__XXX
 SG_ TCU_mdmMcc m22 : 32|32@1+ (1,0) [0|4294967295] "" Vector__XXX
 SG_ TCU_mdmTxKiloBytes m23 : 32|32@1+ (1,0) [0|4294967295] "KB" Vector__XXX
 SG_ TCU_mdmDataCallTermReason m24 : 32|32@1+ (1,0) [0|4294967295] "" Vector__XXX
 SG_ TCU_mdmDataCallTermCode m25 : 32|32@1+ (1,0) [0|4294967295] "" Vector__XXX
 SG_ TCU_cellularSMState m26 : 32|32@1+ (1,0) [0|4294967295] "" Vector__XXX
 SG_ TCU_tcuSMState m27 : 32|32@1+ (1,0) [0|4294967295] "" Vector__XXX
 SG_ TCU_checkInternetFailCount m28 : 32|32@1+ (1,0) [0|4294967295] "" Vector__XXX
 SG_ TCU_mdmBand m29 : 32|32@1+ (1,0) [0|4294967295] "" Vector__XXX
 SG_ TCU_wakeSource m30 : 32|2@1+ (1,0) [0|3] "" Vector__XXX

BO_TX_BU_ 943 : BB;
BO_TX_BU_ 888 : GTW;
BO_TX_BU_ 282 : GTW;
BO_TX_BU_ 838 : GTW;
BO_TX_BU_ 904 : GTW;
BO_TX_BU_ 2047 : GTW;
BO_TX_BU_ 1638 : GTW;
BO_TX_BU_ 1080 : GTW;
BO_TX_BU_ 1656 : GTW;
BO_TX_BU_ 2033 : GTW;
BO_TX_BU_ 2026 : GTW;
BO_TX_BU_ 60 : GTW;
BO_TX_BU_ 1370 : GTW;
BO_TX_BU_ 840 : GTW;
BO_TX_BU_ 1005 : GTW;
BO_TX_BU_ 1112 : GTW;
BO_TX_BU_ 828 : IDB;
BO_TX_BU_ 1415 : TCU2;
BO_TX_BU_ 1412 : TCU2;
BO_TX_BU_ 1159 : TCU;
BO_TX_BU_ 1155 : TCU;

CM_ "Tesla Model 3 CAN bus database; bus ETH (Ethernet-side ids, not CAN ids); firmware 2026.26.6.5. Decoded CAN signal definitions (layout, scaling, units, value tables).";
CM_ BU_ BB "BB ECU";
CM_ BU_ GTW "Gateway";
CM_ BU_ IDB "IDB ECU";
CM_ BU_ TCU "TCU ECU";
CM_ BU_ TCU2 "TCU2 ECU";
CM_ BU_ UI "Touchscreen user interface computer";
CM_ BU_ UIS "UIS ECU";
CM_ BU_ VCSEAT2L "VCSEAT2L ECU";
CM_ BU_ VCSEAT2R "VCSEAT2R ECU";
CM_ BO_ 943 "BB ECU message: status";
CM_ SG_ 943 BB_statusChecksum "BB ECU: status checksum";
CM_ SG_ 943 BB_statusCounter "BB ECU: status counter";
CM_ SG_ 943 BB_sOutputRod "Reports the measured brake booster (BB) plunger piston position";
CM_ SG_ 943 BB_sOutputRodQF "Reports the BB_sOutputRod signal qualifier";
CM_ SG_ 943 BB_sInputRod "Reports the measured brake booster (BB) input rod stroke.";
CM_ SG_ 943 BB_sInputRodQF "Reports the BB_sInputRod signal qualifier.";
CM_ SG_ 943 BB_driverBrakeApply "Indicates whether the driver operates the brake pedal. Only active when the driver brakes, not when an external brake command implemented on brake booster (BB).";
CM_ SG_ 943 BB_driverBrakeApplyQF "Qualifier for BB_driverBrakeApply";
CM_ SG_ 943 BB_boosterStatus "Indication of the brake booster (BB) functional state";
CM_ SG_ 943 BB_warningLampRequest "Request from brake booster (BB) to enable the red brake lamp";
CM_ SG_ 943 BB_brakeFluidLevel "Indication of the brake fluid reservoir fluid level sensor status measured by the brake booster (BB).";
CM_ SG_ 943 BB_internalState "Indication of the brake booster (BB) internal state";
CM_ SG_ 943 BB_unfilteredFluidLevelLow "Indicates whether the unfiltered brake fluid level is detected as low.";
CM_ BO_ 888 "Gateway message: e call";
CM_ SG_ 888 GTW_GTW_SOS_ECALL_RQST "State of the GTW-SOS-ECALL-RQST pin";
CM_ SG_ 888 GTW_LTE_ECALL_LOCK "State of the LTE-ECALL-LOCK pin";
CM_ BO_ 282 "Gateway message: adc4";
CM_ SG_ 282 GTW_BKP_BATT_MON "Gateway: BKP BATT MON; raw 4095 = signal not available (SNA)";
CM_ SG_ 282 GTW_BKP_BATT_NTC_P "BKP_BATT_NTC_P pni voltage; raw 4095 = signal not available (SNA)";
CM_ SG_ 282 GTW_ECALL_GPS_ANT_BIAS "Gateway: ECALL GPS ANT BIAS; raw 4095 = signal not available (SNA)";
CM_ SG_ 282 GTW_ECALL_MIC_DIAG "ECALL_MIC_DIAG voltage; raw 4095 = signal not available (SNA)";
CM_ SG_ 282 GTW_SOS_ECALL_nRQST_BUF "SOS_ECALL_nRQST_BUF voltage; raw 4095 = signal not available (SNA)";
CM_ BO_ 838 "Gateway message: autopilot override";
CM_ SG_ 838 GTW_autopilotOverrideState "Signals whether an autopilot trial or subscription is active";
CM_ SG_ 838 GTW_autopilotConfig "Current level of permanent Autopilot firmware";
CM_ SG_ 838 GTW_autopilotOverrideConfig "Current level of trial or subscription Autopilot firmware";
CM_ SG_ 838 GTW_autopilotConfigSource "Source of Autopilot configuration broadcast by Gateway";
CM_ SG_ 838 GTW_autopilotOverrideExpireTime "Expiration time for the currently active autopilot trial or subscription";
CM_ BO_ 904 "Gateway message: can status";
CM_ SG_ 904 GTW_VEH_canBusActivity "Active if any frame detected on the bus";
CM_ SG_ 904 GTW_PARTY_canBusActivity "Active if any frame detected on the bus";
CM_ SG_ 904 GTW_CH_canBusActivity "Active if any frame detected on the bus";
CM_ SG_ 904 GTW_VEH_txWarning "Gateway: VEH tx warning";
CM_ SG_ 904 GTW_PARTY_txWarning "Gateway: PARTY tx warning";
CM_ SG_ 904 GTW_CH_txWarning "Gateway: CH tx warning";
CM_ SG_ 904 GTW_VEH_rxWarning "Gateway: VEH rx warning";
CM_ SG_ 904 GTW_PARTY_rxWarning "Gateway: PARTY rx warning";
CM_ SG_ 904 GTW_CH_rxWarning "Gateway: CH rx warning";
CM_ SG_ 904 GTW_VEH_faultConfinement "Fault confinement as per CAN spec";
CM_ SG_ 904 GTW_PARTY_faultConfinement "Fault confinement as per CAN spec";
CM_ SG_ 904 GTW_CH_faultConfinement "Fault confinement as per CAN spec";
CM_ BO_ 2047 "Gateway message: car config";
CM_ SG_ 2047 GTW_carConfigMultiplexer "Gateway: car config multiplexer";
CM_ SG_ 2047 GTW_deliveryStatus "Indicates whether the vehicle has been marked delivered to the customer in Tesla backend systems.";
CM_ SG_ 2047 GTW_cabinPTCHeaterType "Gateway: cabin PTC heater type";
CM_ SG_ 2047 GTW_rightHandDrive "Gateway: right hand drive";
CM_ SG_ 2047 GTW_rearLightType "Gateway: rear light type";
CM_ SG_ 2047 GTW_headlamps "Gateway: headlamps";
CM_ SG_ 2047 GTW_country "Gateway: country";
CM_ SG_ 2047 GTW_tireType "Gateway: tire type";
CM_ SG_ 2047 GTW_dasHw "Indicates the Driver Assistance System (DAS) hardware installed.";
CM_ SG_ 2047 GTW_brakeHWType "Gateway: brake HW type";
CM_ SG_ 2047 GTW_restraintsHardwareType "Gateway: restraints hardware type";
CM_ SG_ 2047 GTW_drivetrainType "Gateway: drivetrain type";
CM_ SG_ 2047 GTW_radarHeaterType "Gateway: radar heater type";
CM_ SG_ 2047 GTW_exteriorTrimType "Gateway: exterior trim type";
CM_ SG_ 2047 GTW_frontSeatHeaters "Gateway: front seat heaters";
CM_ SG_ 2047 GTW_rearSeatHeaters "Gateway: rear seat heaters";
CM_ SG_ 2047 GTW_eCallAntennaHW "Gateway: e call antenna HW";
CM_ SG_ 2047 GTW_homelinkType "Gateway: homelink type";
CM_ SG_ 2047 GTW_vdcType "Gateway: vdc type";
CM_ SG_ 2047 GTW_memoryMirrors "Gateway: memory mirrors";
CM_ SG_ 2047 GTW_powerLiftgateType "Gateway: power liftgate type";
CM_ SG_ 2047 GTW_lumbarECUType "Gateway: lumbar ECU type";
CM_ SG_ 2047 GTW_rearSeatHeaterType "Gateway: rear seat heater type";
CM_ SG_ 2047 GTW_auxParkLamps "Gateway: aux park lamps";
CM_ SG_ 2047 GTW_interiorCabinRadarType "Gateway: interior cabin radar type";
CM_ SG_ 2047 GTW_hvacPanelVaneType "Gateway: hvac panel vane type";
CM_ SG_ 2047 GTW_intakeAirFilterType "Gateway: intake air filter type";
CM_ SG_ 2047 GTW_eBuckConfig "Gateway: e buck config";
CM_ SG_ 2047 GTW_steeringHeaterEnabled "Gateway: steering heater enabled";
CM_ SG_ 2047 GTW_activeHighBeam "Gateway: active high beam";
CM_ SG_ 2047 GTW_airbagCutoffSwitch "Gateway: airbag cutoff switch";
CM_ SG_ 2047 GTW_intrusionSensorType "Gateway: intrusion sensor type";
CM_ SG_ 2047 GTW_spoilerType "Gateway: spoiler type";
CM_ SG_ 2047 GTW_backupCameraType "Gateway: backup camera type";
CM_ SG_ 2047 GTW_rearFogLamps "Gateway: rear fog lamps";
CM_ SG_ 2047 GTW_roofType "Gateway: roof type";
CM_ SG_ 2047 GTW_thirdRowSeatType "Gateway: third row seat type";
CM_ SG_ 2047 GTW_autopilot "Gateway: autopilot";
CM_ SG_ 2047 GTW_superchargingAccess "Gateway: supercharging access";
CM_ SG_ 2047 GTW_exteriorColor "Gateway: exterior color";
CM_ SG_ 2047 GTW_pedestrianWarningSound "Gateway: pedestrian warning sound";
CM_ SG_ 2047 GTW_steeringColumnUJointType "Gateway: steering column u joint type";
CM_ SG_ 2047 GTW_bPillarNFCParam "Gateway: b pillar NFC param";
CM_ SG_ 2047 GTW_interiorLighting "Gateway: interior lighting";
CM_ SG_ 2047 GTW_headlightLevelerType "Gateway: headlight leveler type";
CM_ SG_ 2047 GTW_numberHVILNodes "Gateway: number HVIL nodes";
CM_ SG_ 2047 GTW_mapRegion "Gateway: map region";
CM_ SG_ 2047 GTW_performancePackage "Gateway: performance package";
CM_ SG_ 2047 GTW_chassisType "Indicates the chassis type, which determines physical aspects such as suspension geometry, track width, wheel base, baseline tire size, and trailer capability.";
CM_ SG_ 2047 GTW_airSuspension "Gateway: air suspension";
CM_ SG_ 2047 GTW_centerConsoleControllerType "Gateway: center console controller type";
CM_ SG_ 2047 GTW_autopilotCameraType "Gateway: autopilot camera type";
CM_ SG_ 2047 GTW_connectivityPackage "Gateway: connectivity package";
CM_ SG_ 2047 GTW_plcSupportType "Gateway: plc support type";
CM_ SG_ 2047 GTW_badgingVersion "Gateway: badging version";
CM_ SG_ 2047 GTW_packEnergy "Gateway: pack energy";
CM_ SG_ 2047 GTW_frontSeatReclinerHardware "Gateway: front seat recliner hardware";
CM_ SG_ 2047 GTW_brakeLineSwitchType "Gateway: brake line switch type";
CM_ SG_ 2047 GTW_softRange "Gateway: soft range";
CM_ SG_ 2047 GTW_refrigerantType "Gateway: refrigerant type";
CM_ SG_ 2047 GTW_wheelType "Gateway: wheel type";
CM_ SG_ 2047 GTW_brakeActuationType "Gateway: brake actuation type";
CM_ SG_ 2047 GTW_secondRowSeatType "Gateway: second row seat type";
CM_ SG_ 2047 GTW_secondRowSeatMotorType "Gateway: second row seat motor type";
CM_ SG_ 2047 GTW_birthday "Gateway: birthday";
CM_ SG_ 2047 GTW_eCallEnabled "Gateway: e call enabled";
CM_ SG_ 2047 GTW_parkAssistECUType "Gateway: park assist ECU type";
CM_ SG_ 2047 GTW_passengerAirbagType "Gateway: passenger airbag type";
CM_ SG_ 2047 GTW_forwardRadarHw "Gateway: forward radar hw";
CM_ SG_ 2047 GTW_frontSeatType "Gateway: front seat type";
CM_ SG_ 2047 GTW_secondRowDisplayType "Gateway: second row display type";
CM_ SG_ 2047 GTW_wirelessPhoneChargerType "Gateway: wireless phone charger type";
CM_ SG_ 2047 GTW_ethernetTunerType "Gateway: ethernet tuner type";
CM_ SG_ 2047 GTW_interiorTrimType "Gateway: interior trim type";
CM_ SG_ 2047 GTW_gloveboxUSBType "Gateway: glovebox USB type";
CM_ SG_ 2047 GTW_coolantPumpType "Gateway: coolant pump type";
CM_ SG_ 2047 GTW_epblHwType "Gateway: epbl hw type";
CM_ SG_ 2047 GTW_epbrHwType "Gateway: epbr hw type";
CM_ SG_ 2047 GTW_blowerMotorType "Gateway: blower motor type";
CM_ SG_ 2047 GTW_powerMirrorFoldType "Gateway: power mirror fold type";
CM_ SG_ 2047 GTW_frontUsbHubType "Gateway: front usb hub type";
CM_ SG_ 2047 GTW_superManifoldType "Type of HVAC super manifold installed";
CM_ SG_ 2047 GTW_rcmLocation "Gateway: rcm location";
CM_ SG_ 2047 GTW_autopilotExteriorCameraType "Gateway: autopilot exterior camera type";
CM_ SG_ 2047 GTW_sirenType "Gateway: siren type";
CM_ SG_ 2047 GTW_hornType "Gateway: horn type";
CM_ SG_ 2047 GTW_passengerTrackMotorType "Gateway: passenger track motor type";
CM_ SG_ 2047 GTW_steeringColumnMotorType "Gateway: steering column motor type";
CM_ SG_ 2047 GTW_refrigACLineType "Gateway: refrig AC line type";
CM_ SG_ 2047 GTW_refrigFilterType "Gateway: refrig filter type";
CM_ SG_ 2047 GTW_diBurnInType "Gateway: di burn in type";
CM_ SG_ 2047 GTW_specialBadgingType "Gateway: special badging type";
CM_ SG_ 2047 GTW_chassisSubType "Reports chassis sub-variant type.";
CM_ SG_ 2047 GTW_towPackage "Gateway: tow package";
CM_ SG_ 2047 GTW_refrigLccType "Gateway: refrig lcc type";
CM_ SG_ 2047 GTW_restraintControlsType "Gateway: restraint controls type";
CM_ SG_ 2047 GTW_caliperColorType "Gateway: caliper color type";
CM_ SG_ 2047 GTW_wiperMotorType "Gateway: wiper motor type";
CM_ SG_ 2047 GTW_frontOverheadConsoleType "Gateway: front overhead console type";
CM_ SG_ 2047 GTW_shifterType "Gateway: shifter type";
CM_ SG_ 2047 GTW_compressorType "Gateway: compressor type";
CM_ SG_ 2047 GTW_twelveVBatteryType "Gateway: twelve v battery type";
CM_ SG_ 2047 GTW_efuseSWConfig "Gateway: efuse SW config";
CM_ SG_ 2047 GTW_tollCollectionModuleType "Gateway: toll collection module type";
CM_ SG_ 2047 GTW_bleEndpointUpdateMethod "Gateway: ble endpoint update method";
CM_ SG_ 2047 GTW_steeringWheelControllerType "Gateway: steering wheel controller type";
CM_ SG_ 2047 GTW_frontSeatVentilationEnabled "Gateway: front seat ventilation enabled";
CM_ SG_ 2047 GTW_gloveboxActuatorType "Gateway: glovebox actuator type";
CM_ SG_ 2047 GTW_epasType "Gateway: epas type";
CM_ SG_ 2047 GTW_homologationRegionOverride "Gateway: homologation region override";
CM_ SG_ 2047 GTW_windowCommandsPermissionType "Gateway: window commands permission type";
CM_ SG_ 2047 GTW_rgbInteriorLightingEnabled "Gateway: rgb interior lighting enabled";
CM_ SG_ 2047 GTW_windshieldWiperHeaterType "Gateway: windshield wiper heater type";
CM_ SG_ 2047 GTW_thirdRowSeatReclinerType "Gateway: third row seat recliner type";
CM_ SG_ 2047 GTW_driveInterfaceType "Gateway: drive interface type";
CM_ SG_ 2047 GTW_efficiencyPackage "Gateway: efficiency package";
CM_ SG_ 2047 GTW_visorLightType "Gateway: visor light type";
CM_ SG_ 2047 GTW_gnssAntennaType "Gateway: gnss antenna type";
CM_ SG_ 2047 GTW_airDistributionBoxType "Gateway: air distribution box type";
CM_ SG_ 2047 GTW_frontSeatHeatersEnabled "Gateway: front seat heaters enabled";
CM_ SG_ 2047 GTW_windshieldWiperHeaterEnabled "Gateway: windshield wiper heater enabled";
CM_ SG_ 2047 GTW_alcoholInterlockType "Gateway: alcohol interlock type";
CM_ SG_ 2047 GTW_fasciaType "Gateway: fascia type";
CM_ SG_ 2047 GTW_powerSteeringColumn "Gateway: power steering column";
CM_ SG_ 2047 GTW_frontSeatHeaterType "Gateway: front seat heater type";
CM_ SG_ 2047 GTW_softPerformanceLimit "Gateway: soft performance limit";
CM_ SG_ 2047 GTW_gsrFeatureType "Gateway: gsr feature type";
CM_ SG_ 2047 GTW_immersiveAudio "Gateway: immersive audio";
CM_ SG_ 2047 GTW_frontSeatVentilationType "Gateway: front seat ventilation type";
CM_ SG_ 2047 GTW_passengerOccupancySensorType "Gateway: passenger occupancy sensor type";
CM_ SG_ 2047 GTW_packPerformanceDeviation "Measures deviation from standard pack mass or power output capability associated with the vehicle packEnergy configuration.";
CM_ SG_ 2047 GTW_frontFogLamps "Gateway: front fog lamps";
CM_ SG_ 2047 GTW_driverOccupancySensorType "Gateway: driver occupancy sensor type";
CM_ SG_ 2047 GTW_audioType "Gateway: audio type";
CM_ SG_ 2047 GTW_thighExtenderType "Gateway: thigh extender type";
CM_ SG_ 2047 GTW_occupancyClassificationFeatu "Gateway: occupancy classification feature type";
CM_ SG_ 2047 GTW_frontControllerArchitectureT "Reports internal microcontroller architecture of the Front Controller assembly, which contains the Front Vehicle Controller (VCFRONT) and may contain a Vehicle Battery Controller (VCBATT).";
CM_ SG_ 2047 GTW_domeLightType "Gateway: dome light type";
CM_ SG_ 2047 GTW_tpmsType "Gateway: tpms type";
CM_ SG_ 2047 GTW_authenticationEndpointLayout "Gateway: authentication endpoint layout";
CM_ SG_ 2047 GTW_socSleepOverride "Gateway: soc sleep override";
CM_ SG_ 2047 GTW_r79BehaviorOverride "Gateway: r79 behavior override";
CM_ SG_ 2047 GTW_steeringHeaterType "Gateway: steering heater type";
CM_ SG_ 2047 GTW_narrowWipingSupported "Gateway: narrow wiping supported";
CM_ SG_ 2047 GTW_frontSeatHeaterGridType "Gateway: front seat heater grid type";
CM_ SG_ 2047 GTW_frontSeatSideSwitchType "Gateway: front seat side switch type";
CM_ SG_ 2047 GTW_sohRegulatoryStatus "Gateway: soh regulatory status";
CM_ SG_ 2047 GTW_passengerTiltMotorType "Gateway: passenger tilt motor type";
CM_ SG_ 2047 GTW_frunkInteriorReleaseType "Gateway: frunk interior release type";
CM_ SG_ 2047 GTW_m3yBusArchitecture "Reports notable features of vehicle communication bus architecture. Used for firmware artifact selection during update installation process.";
CM_ SG_ 2047 GTW_passengerLiftMotorType "Gateway: passenger lift motor type";
CM_ SG_ 2047 GTW_interiorUpperTrimType "Gateway: interior upper trim type";
CM_ SG_ 2047 GTW_blindSpotIndicatorLightType "Gateway: blind spot indicator light type";
CM_ SG_ 2047 GTW_wiperMotorAsicType "Gateway: wiper motor asic type";
CM_ SG_ 2047 GTW_hvacCaseDoorType "Gateway: hvac case door type";
CM_ SG_ 2047 GTW_rduCableType "Indicates type of rear drive unit cable installed on vehicle.";
CM_ SG_ 2047 GTW_parkTelltaleBehaviorType "Gateway: park telltale behavior type";
CM_ SG_ 2047 GTW_numberKeyCardsPairedInFactor "Gateway: number key cards paired in factory";
CM_ SG_ 2047 GTW_secondRowSeatVentilationType "Gateway: second row seat ventilation type";
CM_ SG_ 2047 GTW_thirdRowSeatHeaterType "Gateway: third row seat heater type";
CM_ SG_ 2047 GTW_interiorCameraType "Gateway: interior camera type";
CM_ SG_ 2047 GTW_frontFasciaCameraType "Reports type of forward facing fascia camera installed.";
CM_ SG_ 2047 GTW_interiorCamFanType "Gateway: interior cam fan type";
CM_ SG_ 2047 GTW_puddleLampType "Gateway: puddle lamp type";
CM_ SG_ 2047 GTW_solarLensType "Gateway: solar lens type";
CM_ SG_ 2047 GTW_liftgateGeometryType "Gateway: liftgate geometry type";
CM_ SG_ 2047 GTW_repeaterAeroRibType "Gateway: repeater aero rib type";
CM_ SG_ 2047 GTW_highTipForceWiperArmsType "Gateway: high tip force wiper arms type";
CM_ SG_ 2047 GTW_rcmUndersideAbuseZThreshold "Gateway: rcm underside abuse z threshold";
CM_ SG_ 2047 GTW_rcmUndersideAbuseYThreshold "Gateway: rcm underside abuse y threshold";
CM_ SG_ 2047 GTW_rcmUndersideAbuseWindow "Gateway: rcm underside abuse window";
CM_ SG_ 2047 GTW_automaticFeatureResetPackage "Gateway: automatic feature reset package";
CM_ SG_ 2047 GTW_autopilotFeaturePackage "Gateway: autopilot feature package";
CM_ SG_ 2047 GTW_doorLatchType "Gateway: door latch type";
CM_ SG_ 2047 GTW_headlinerMaterialType "Gateway: headliner material type";
CM_ SG_ 2047 GTW_glareShieldHeaterType "Gateway: glare shield heater type";
CM_ SG_ 2047 GTW_rearLightHardwareVariant "Gateway: rear light hardware variant";
CM_ SG_ 2047 GTW_fasciaHarnessCleanPointType "Gateway: fascia harness clean point type";
CM_ SG_ 2047 GTW_epasSubType "Gateway: epas sub type";
CM_ SG_ 2047 GTW_wiperSupplyChainOrigin "Gateway: wiper supply chain origin; raw 0 = signal not available (SNA)";
CM_ SG_ 2047 GTW_windowPinchParameterType "Gateway: window pinch parameter type";
CM_ SG_ 2047 GTW_badgingMaterialType "Gateway: badging material type";
CM_ SG_ 2047 GTW_mRecordVersion "Gateway: m record version";
CM_ SG_ 2047 GTW_tcuType "Gateway: tcu type";
CM_ SG_ 2047 GTW_carbComplianceBehaviorType "Gateway: carb compliance behavior type";
CM_ SG_ 2047 GTW_indirectTPMSCalibrationType "Indirect TPMS calibration type.";
CM_ SG_ 2047 GTW_v2xEnabled "Gateway: v2x enabled";
CM_ SG_ 2047 GTW_liftgateStrutType "Gateway: liftgate strut type";
CM_ SG_ 2047 GTW_exteriorMicrophoneType "Gateway: exterior microphone type";
CM_ SG_ 2047 GTW_roofGlassType "Gateway: roof glass type";
CM_ SG_ 2047 GTW_pedalMapNameOverride "Gateway: pedal map name override";
CM_ BO_ 1638 "Gateway message: diag session";
CM_ SG_ 1638 GTW_diagRemainingSeconds "Seconds remaining for the diagnostics session";
CM_ SG_ 1638 GTW_diagSessionActive "UDS Session Active";
CM_ SG_ 1638 GTW_diagLevel "Current diagnostics level";
CM_ SG_ 1638 GTW_diagUnlockProcedureActive "GTW diag unlock procedure active";
CM_ SG_ 1638 GTW_diagOverrideActive "GTW diag level override active";
CM_ SG_ 1638 GTW_diagPhysicalLinkEstablished "Physical diag cable connected to the switch and link established";
CM_ BO_ 1080 "Gateway message: eth nm";
CM_ SG_ 1080 GTW_ethGotoSleep "ETH bus sleep commanded";
CM_ SG_ 1080 GTW_ethWakeUpBus "Gateway: eth wake up bus";
CM_ SG_ 1080 GTW_vehBusAsleep "VEH bus sleep state";
CM_ SG_ 1080 GTW_ethHeartBeatCounter "Gateway: eth heart beat counter";
CM_ SG_ 1080 GTW_ethWakeUpReason "Tracks the cause of why the gateway wakes up the ethernet bus";
CM_ BO_ 1656 "Gateway message: gear control";
CM_ SG_ 1656 GTW_gearControlChecksum "Gateway: gear control checksum";
CM_ SG_ 1656 GTW_gearControlCounter "Gateway: gear control counter";
CM_ SG_ 1656 GTW_gearShiftRequest "Request to change gear state from center display UI control; raw 0 = signal not available (SNA)";
CM_ SG_ 1656 GTW_osdActive "Whether OSD is active";
CM_ SG_ 1656 GTW_primaryGearControlStatus "Status of the center display UI control";
CM_ SG_ 1656 GTW_gearStripEnable "UI control for showing and or activating the primary gear strip interface";
CM_ SG_ 1656 GTW_showNeutralButton "Tell UI that it is time to animate the N button to be shown";
CM_ SG_ 1656 GTW_showAutoParkButton "Tell UI that it is time to animate the autopark button to be shown";
CM_ SG_ 1656 GTW_autoParkRequest "Request to auto park from center display UI control";
CM_ SG_ 1656 GTW_smartShiftStatus "Based on the status of the infotainment system smart shift feature should be disabled; raw 0 = signal not available (SNA)";
CM_ SG_ 1656 GTW_processingRDgestures "Is GTW processing R and D swipe gestures";
CM_ SG_ 1656 GTW_processingTapPgestures "Is GTW processing contextual tap-to-park gestures";
CM_ SG_ 1656 GTW_gearStripChangeReason "Gateway: gear strip change reason; raw 0 = signal not available (SNA)";
CM_ SG_ 1656 GTW_touchActive "User present as touch on display is active";
CM_ SG_ 1656 GTW_steamOff "Let UI know to turn Steam off";
CM_ SG_ 1656 GTW_screenPCBTemperature "Reading from display i2c temperature sensor; raw 2047 = signal not available (SNA)";
CM_ BO_ 2033 "Gateway message: hrl";
CM_ SG_ 2033 GTW_hrlIndex "Gateway: hrl index";
CM_ SG_ 2033 GTW_hrlPagesCount "Gateway: hrl pages count";
CM_ SG_ 2033 GTW_hrlSdCardSizeGB "Gateway: hrl sd card size GB; raw 0 = signal not available (SNA)";
CM_ SG_ 2033 GTW_hrlState "GTW hrl state";
CM_ SG_ 2033 GTW_hrlTriggerDuration "HRL duration";
CM_ SG_ 2033 GTW_hrlTriggerType "HRL trigger type";
CM_ SG_ 2033 GTW_hrlTriggerId "HRL trigger ID. A unique ID representing the signal conditions causing the HRL event to occur.";
CM_ SG_ 2033 GTW_hrlTriggerBus "Gateway: hrl trigger bus";
CM_ BO_ 2026 "Gateway message: hrl external event";
CM_ SG_ 2026 GTW_hrlEventStartEpoch "Gateway: hrl event start epoch";
CM_ SG_ 2026 GTW_hrlEventEndEpoch "Gateway: hrl event end epoch";
CM_ BO_ 60 "Gateway message: info";
CM_ SG_ 60 GTW_infoIndex "Gateway: info index";
CM_ SG_ 60 GTW_buildType "Gateway: build type";
CM_ SG_ 60 GTW_hardwareId "GTW hardware ID";
CM_ SG_ 60 GTW_platformType "Gateway: platform type";
CM_ SG_ 60 GTW_appCrc "Gateway: app crc";
CM_ SG_ 60 GTW_applicationGitHash "Gateway: application git hash";
CM_ SG_ 60 GTW_bootGitHash "Gateway: boot git hash";
CM_ BO_ 1370 "Gateway message: mismatch fault";
CM_ SG_ 1370 GTW_mismatchFaultIndex "Gateway: mismatch fault index";
CM_ SG_ 1370 GTW_mismatchFaultChecksum "Gateway: mismatch fault checksum";
CM_ SG_ 1370 GTW_mismatchFaultCounter "Gateway: mismatch fault counter";
CM_ SG_ 1370 GTW_GTWmismatchFault "Reports the Gateway (GTW) running a firmware version that does not match the rest of the vehicle";
CM_ SG_ 1370 GTW_BMSmismatchFault "Reports the high voltage Battery Management System (BMS) electronic control unit (ECU) running a firmware version that does not match the rest of the vehicle";
CM_ SG_ 1370 GTW_APSmismatchFault "Reports the Autopilot Processor Secondary (APS) electronic control unit (ECU) running a firmware version that does not match the rest of the vehicle";
CM_ SG_ 1370 GTW_BLEEPCENTERmismatchFault "Reports the Bluetooth Low Energy End Point Center (BLEEPCENTER) electronic control unit (ECU) running a firmware version that does not match the rest of the vehicle";
CM_ SG_ 1370 GTW_BLEEPLEFTmismatchFault "Reports the Bluetooth Low Energy End Point Left (BLEEPLEFT) electronic control unit (ECU) running a firmware version that does not match the rest of the vehicle";
CM_ SG_ 1370 GTW_BLEEPREARmismatchFault "Reports the Bluetooth Low Energy End Point Rear (BLEEPREAR) electronic control unit (ECU) running a firmware version that does not match the rest of the vehicle";
CM_ SG_ 1370 GTW_BLEEPRIGHTmismatchFault "Reports the Bluetooth Low Energy End Point Right (BLEEPRIGHT) electronic control unit (ECU) running a firmware version that does not match the rest of the vehicle";
CM_ SG_ 1370 GTW_CBCmismatchFault "Reports the Cabin Blower Controller (CBC) electronic control unit (ECU) running a firmware version that does not match the rest of the vehicle";
CM_ SG_ 1370 GTW_CMPmismatchFault "Reports the air conditioning compressor (CMP) electronic control unit (ECU) running a firmware version that does not match the rest of the vehicle";
CM_ SG_ 1370 GTW_CPmismatchFault "Reports the Charge Port (CP) electronic control unit (ECU) running a firmware version that does not match the rest of the vehicle";
CM_ SG_ 1370 GTW_DIFmismatchFault "Reports the front drive inverter (DIF) electronic control unit (ECU) running a firmware version that does not match the rest of the vehicle";
CM_ SG_ 1370 GTW_DIRmismatchFault "Reports the rear drive inverter (DIR) electronic control unit (ECU) running a firmware version that does not match the rest of the vehicle";
CM_ SG_ 1370 GTW_EPAS3PmismatchFault "Reports the primary Electronic Power Assisted Steering (EPAS3P) electronic control unit (ECU) running a firmware version that does not match the rest of the vehicle";
CM_ SG_ 1370 GTW_EPAS3SmismatchFault "Reports the secondary Electronic Power Assisted Steering (EPAS3S) electronic control unit (ECU) running a firmware version that does not match the rest of the vehicle";
CM_ SG_ 1370 GTW_EPBLmismatchFault "Reports the left Electronic Park Brake (EPBL) electronic control unit (ECU) running a firmware version that does not match the rest of the vehicle";
CM_ SG_ 1370 GTW_EPBRmismatchFault "Reports the right Electronic Park Brake (EPBR) electronic control unit (ECU) running a firmware version that does not match the rest of the vehicle";
CM_ SG_ 1370 GTW_ESPCALmismatchFault "Reports the Electronic Stability Program Calibration (ESPCAL) electronic control unit (ECU) running a firmware version that does not match the rest of the vehicle";
CM_ SG_ 1370 GTW_ESPmismatchFault "Reports the Electronic Stability Program (ESP) electronic control unit (ECU) running a firmware version that does not match the rest of the vehicle";
CM_ SG_ 1370 GTW_HCM3LmismatchFault "Reports the left LED matrix Headlamp Control Module (HCM3L) electronic control unit (ECU) running a firmware version that does not match the rest of the vehicle";
CM_ SG_ 1370 GTW_HCM3RmismatchFault "Reports the right LED matrix Headlamp Control Module (HCM3R) electronic control unit (ECU) running a firmware version that does not match the rest of the vehicle";
CM_ SG_ 1370 GTW_HCMLmismatchFault "Reports the left Headlamp Control Module (HCML) electronic control unit (ECU) running a firmware version that does not match the rest of the vehicle";
CM_ SG_ 1370 GTW_HCMRmismatchFault "Reports the right Headlamp Control Module (HCMR) electronic control unit (ECU) running a firmware version that does not match the rest of the vehicle";
CM_ SG_ 1370 GTW_HVPmismatchFault "Reports the High Voltage Processor (HVP) electronic control unit (ECU) running a firmware version that does not match the rest of the vehicle";
CM_ SG_ 1370 GTW_IBSTCALmismatchFault "Reports the electromechanical brake booster calibration, or iBooster Calibration (IBSTCAL), electronic control unit (ECU) running a firmware version that does not match the rest of the vehicle";
CM_ SG_ 1370 GTW_IBSTmismatchFault "Reports the electromechanical brake booster, or iBooster (IBST), electronic control unit (ECU) running a firmware version that does not match the rest of the vehicle";
CM_ SG_ 1370 GTW_LVBMSmismatchFault "Reports the Low Voltage Battery Management System (LVBMS) electronic control unit (ECU) running a firmware version that does not match the rest of the vehicle";
CM_ SG_ 1370 GTW_OCS1PmismatchFault "Reports the Occupancy Classification System - 1st Row Passenger (OCS1P) electronic control unit (ECU) running a firmware version that does not match the rest of the vehicle";
CM_ SG_ 1370 GTW_OPCFmismatchFault "Reports the front Oil Pump Controller (OPCF) electronic control unit (ECU) running a firmware version that does not match the rest of the vehicle";
CM_ SG_ 1370 GTW_OPCRmismatchFault "Reports the rear Oil Pump Controller (OPCR) electronic control unit (ECU) running a firmware version that does not match the rest of the vehicle";
CM_ SG_ 1370 GTW_PARKmismatchFault "Reports the Park Assist (PARK) electronic control unit (ECU) running a firmware version that does not match the rest of the vehicle";
CM_ SG_ 1370 GTW_PCSCPU2mismatchFault "Reports the Power Conversion System AC charging core (PCSCPU2) electronic control unit (ECU) running a firmware version that does not match the rest of the vehicle";
CM_ SG_ 1370 GTW_PCSmismatchFault "Reports the Power Conversion System (PCS) electronic control unit (ECU) running a firmware version that does not match the rest of the vehicle";
CM_ SG_ 1370 GTW_PMFmismatchFault "Reports the front Pedal Monitor (PMF) electronic control unit (ECU) running a firmware version that does not match the rest of the vehicle";
CM_ SG_ 1370 GTW_PMRmismatchFault "Reports the rear Pedal Monitor (PMR) electronic control unit (ECU) running a firmware version that does not match the rest of the vehicle";
CM_ SG_ 1370 GTW_PTCmismatchFault "Reports the Positive Temperature Coefficient (PTC) heater electronic control unit (ECU) running a firmware version that does not match the rest of the vehicle";
CM_ SG_ 1370 GTW_RCMCALmismatchFault "Reports the Restraint Control Module Calibration (RCMCAL) electronic control unit (ECU) running a firmware version that does not match the rest of the vehicle";
CM_ SG_ 1370 GTW_RCMmismatchFault "Reports the Restraint Control Module (RCM) electronic control unit (ECU) running a firmware version that does not match the rest of the vehicle";
CM_ SG_ 1370 GTW_SCCMmismatchFault "Reports the Steering Column Control Module (SCCM) electronic control unit (ECU) running a firmware version that does not match the rest of the vehicle";
CM_ SG_ 1370 GTW_SDCRmismatchFault "Reports the Secondary Disconnect Controller (SDCR) electronic control unit (ECU) running a firmware version that does not match the rest of the vehicle";
CM_ SG_ 1370 GTW_SWCmismatchFault "Reports the Steering Wheel Controller (SWC) electronic control unit (ECU) running a firmware version that does not match the rest of the vehicle";
CM_ SG_ 1370 GTW_THSmismatchFault "Reports the Temperature Humidity Sensor (THS) electronic control unit (ECU) running a firmware version that does not match the rest of the vehicle";
CM_ SG_ 1370 GTW_VCFRONTmismatchFault "Reports the front vehicle controller (VCFRONT) electronic control unit (ECU) running a firmware version that does not match the rest of the vehicle";
CM_ SG_ 1370 GTW_VCLEFTmismatchFault "Reports the left vehicle controller (VCLEFT) electronic control unit (ECU) running a firmware version that does not match the rest of the vehicle";
CM_ SG_ 1370 GTW_VCRIGHTmismatchFault "Reports the right vehicle controller (VCRIGHT) electronic control unit (ECU) running a firmware version that does not match the rest of the vehicle";
CM_ SG_ 1370 GTW_VCSECmismatchFault "Reports the vehicle security controller (VCSEC) electronic control unit (ECU) running a firmware version that does not match the rest of the vehicle";
CM_ SG_ 1370 GTW_PMmismatchFault "Reports the Pedal Monitor (PM) electronic control unit (ECU) running a firmware version that does not match the rest of the vehicle";
CM_ BO_ 840 "Gateway message: status";
CM_ SG_ 840 GTW_vehicleVersionMatchStatus "Signal to indicate if the vehicle ECUs are all on a matched production version";
CM_ SG_ 840 GTW_hwtype "Describes the chip GTW is running on; raw 0 = signal not available (SNA)";
CM_ SG_ 840 GTW_jcanProductName "Describes the JCAN reference (product) name; raw 0 = signal not available (SNA)";
CM_ SG_ 840 GTW_uptimeSeconds "GTW uptime in seconds";
CM_ SG_ 840 GTW_boardRevision "Board revision ID of the MCU PCBA";
CM_ SG_ 840 GTW_touchcoreOsType "Gateway: touchcore os type";
CM_ SG_ 840 GTW_sentryModeState "Sentry Mode state; raw 6 = signal not available (SNA)";
CM_ SG_ 840 GTW_secureBootEnabled "Gateway: secure boot enabled";
CM_ SG_ 840 GTW_socSleepType "Describes the sleep type GTW is expecting from the SoC; raw 0 = signal not available (SNA)";
CM_ SG_ 840 GTW_resetType "Describes the type of reset GTW experienced; raw 0 = signal not available (SNA)";
CM_ BO_ 1005 "Gateway message: update status";
CM_ SG_ 1005 GTW_i2cUpdateActive "Gateway: i2c update active";
CM_ SG_ 1005 GTW_peripheralConfirmedUpdateNee "Detects if peripheral has confirmed update is needed";
CM_ SG_ 1005 GTW_ocuFailed "Reports the offboard charger update was unsuccessful.";
CM_ SG_ 1005 GTW_ecuUpdateStarted "Reports whether Electronic Control Unit (ECU) update phase is active.";
CM_ SG_ 1005 GTW_updateStarted "Main update in progress bit";
CM_ BO_ 1112 "Gateway message: veh nm";
CM_ SG_ 1112 GTW_nmGoingToSleep "Network management - Going to sleep state";
CM_ SG_ 1112 GTW_nmWakeUpBus "Gateway: nm wake up bus";
CM_ SG_ 1112 GTW_chBusAsleep "Chassis bus sleep state";
CM_ SG_ 1112 GTW_ethBusAsleep "ETH bus sleep state";
CM_ SG_ 1112 GTW_nmKeepAwakeReason "Network management - Keep awake reason; raw 0 = signal not available (SNA)";
CM_ SG_ 1112 GTW_nmWakeUpReason "Network management - Wakeup reason";
CM_ SG_ 1112 GTW_ethKeepAwakeReason "Reason GTW is keeping ETH bus awake; raw 0 = signal not available (SNA)";
CM_ SG_ 1112 GTW_nmDebugWakeUp "Gateway: nm debug wake up";
CM_ SG_ 1112 GTW_OTAKeepAwake "Signals that the vehicle buses should remain awake for an ongoing OTA update";
CM_ SG_ 1112 GTW_smsPokeReceived "The modem indicated it received an SMS poke";
CM_ BO_ 828 "IDB ECU message: info";
CM_ SG_ 828 IDB_infoIndex "IDB ECU: info index";
CM_ SG_ 828 IDB_infoPcbaID "IDB ECU: info pcba ID";
CM_ SG_ 828 IDB_infoAssemblyID "IDB ECU: info assembly ID";
CM_ SG_ 828 IDB_infoUsageID "IDB ECU: info usage ID";
CM_ SG_ 828 IDB_infoSubUsageID "IDB ECU: info sub usage ID";
CM_ BO_ 1415 "TCU2 ECU message: sleep config";
CM_ SG_ 1415 TCU2_tc10Version "Indicates which version of Open Alliance's TC10 protocol is supported by the modem; raw 0 = signal not available (SNA)";
CM_ BO_ 1412 "TCU2 ECU message: log";
CM_ SG_ 1412 TCU2_logMux "TCU2 ECU: log mux";
CM_ SG_ 1412 TCU2_cpuTemp "Indicates the current temperature reported by the Central Processing Unit (CPU) in the modem application processor";
CM_ SG_ 1412 TCU2_cpuUsage "Indicates the current CPU usage in percentage reported by the modem application processor";
CM_ SG_ 1412 TCU2_mdmCoreTemperature "Indicates the current Communication Processor (CP) temperature reported by the modem CP.";
CM_ SG_ 1412 TCU2_availableMemory "Indicates the currently available Random Access Memory in the modem application processor";
CM_ SG_ 1412 TCU2_pwm "Indicates the active Pulse Width Modulation (PWM) duty cycle applied to the modem fan.";
CM_ SG_ 1412 TCU2_pwmcap "Indicates the active Pulse Width Modulation (PWM) duty cycle restriciton applied to the modem fan.";
CM_ SG_ 1412 TCU2_totalResumes "Indicates the total amount of times the modem has been resumed";
CM_ SG_ 1412 TCU2_mdmUplinkQueueSize "TCU2 ECU: mdm uplink queue size";
CM_ SG_ 1412 TCU2_mdmRSRP "TCU2 ECU: mdm RSRP";
CM_ SG_ 1412 TCU2_mdmSINR "TCU2 ECU: mdm SINR";
CM_ SG_ 1412 TCU2_mdmUplinkAllowedRate "TCU2 ECU: mdm uplink allowed rate";
CM_ SG_ 1412 TCU2_mdmUplinkAvgRate "TCU2 ECU: mdm uplink avg rate";
CM_ SG_ 1412 TCU2_mdmServiceState "TCU2 ECU: mdm service state";
CM_ SG_ 1412 TCU2_mdmIMSStatus "Indicates the current IP Multimedia System (IMS) registration state.";
CM_ SG_ 1412 TCU2_mdmSIMStatus "TCU2 ECU: mdm SIM status";
CM_ SG_ 1412 TCU2_mdmBusyActive "Reports whether the modem busy service is active on the modem application processor; raw 4294967295 = signal not available (SNA)";
CM_ SG_ 1412 TCU2_modemUptime "Indicates the current modem Application Processor uptime.";
CM_ SG_ 1412 TCU2_mdmDataRat "Reports which Radio Access Technology (RAT) is active for the current data bearer.";
CM_ SG_ 1412 TCU2_mdmDataCallStatus "Indicates the current state of the Packet Data Protocol (PDP) context.";
CM_ SG_ 1412 TCU2_mdmNSAAvailable "TCU2 ECU: mdm NSA available";
CM_ SG_ 1412 TCU2_mdmPCIID "TCU2 ECU: mdm PCIID";
CM_ SG_ 1412 TCU2_mdmMnc "TCU2 ECU: mdm mnc";
CM_ SG_ 1412 TCU2_mdmMcc "TCU2 ECU: mdm mcc";
CM_ SG_ 1412 TCU2_mdmTxKiloBytes "TCU2 ECU: mdm tx kilo bytes";
CM_ SG_ 1412 TCU2_mdmDataCallTermReason "Indicates the internal reason which the Data Call was terminated.";
CM_ SG_ 1412 TCU2_mdmDataCallTermCode "Indicates the termination code informed by the network that caused the Data Call termination.";
CM_ SG_ 1412 TCU2_cellularSMState "Indicates the current state of cellular state machine.";
CM_ SG_ 1412 TCU2_tcuSMState "Reports the state of the Telematics Control Unit (TCU) state machine.";
CM_ SG_ 1412 TCU2_checkInternetFailCount "Reports the count of unsuccessful cellular connectivity checks.";
CM_ SG_ 1412 TCU2_mdmBand "Indicates the band which the baseband processor is currently attached to the cellular network.";
CM_ SG_ 1412 TCU2_wakeSource "Indicates the source of wake event in the modem.";
CM_ BO_ 1159 "TCU ECU message: sleep config";
CM_ SG_ 1159 TCU_tc10Version "Indicates which version of Open Alliance's TC10 protocol is supported by the modem; raw 0 = signal not available (SNA)";
CM_ BO_ 1155 "TCU ECU message: log";
CM_ SG_ 1155 TCU_logMux "TCU ECU: log mux";
CM_ SG_ 1155 TCU_cpuTemp "Indicates the current temperature reported by the Central Processing Unit (CPU) in the modem application processor";
CM_ SG_ 1155 TCU_cpuUsage "Indicates the current CPU usage in percentage reported by the modem application processor";
CM_ SG_ 1155 TCU_mdmCoreTemperature "Indicates the current Communication Processor (CP) temperature reported by the modem CP.";
CM_ SG_ 1155 TCU_availableMemory "Indicates the currently available Random Access Memory in the modem application processor";
CM_ SG_ 1155 TCU_pwm "Indicates the active Pulse Width Modulation (PWM) duty cycle applied to the modem fan.";
CM_ SG_ 1155 TCU_pwmcap "Indicates the active Pulse Width Modulation (PWM) duty cycle restriciton applied to the modem fan.";
CM_ SG_ 1155 TCU_totalResumes "Indicates the total amount of times the modem has been resumed";
CM_ SG_ 1155 TCU_mdmUplinkQueueSize "TCU ECU: mdm uplink queue size";
CM_ SG_ 1155 TCU_mdmRSRP "TCU ECU: mdm RSRP";
CM_ SG_ 1155 TCU_mdmSINR "TCU ECU: mdm SINR";
CM_ SG_ 1155 TCU_mdmUplinkAllowedRate "TCU ECU: mdm uplink allowed rate";
CM_ SG_ 1155 TCU_mdmUplinkAvgRate "TCU ECU: mdm uplink avg rate";
CM_ SG_ 1155 TCU_mdmServiceState "TCU ECU: mdm service state";
CM_ SG_ 1155 TCU_mdmIMSStatus "Indicates the current IP Multimedia System (IMS) registration state.";
CM_ SG_ 1155 TCU_mdmSIMStatus "TCU ECU: mdm SIM status";
CM_ SG_ 1155 TCU_mdmBusyActive "Reports whether the modem busy service is active on the modem application processor; raw 4294967295 = signal not available (SNA)";
CM_ SG_ 1155 TCU_modemUptime "Indicates the current modem Application Processor uptime.";
CM_ SG_ 1155 TCU_mdmDataRat "Reports which Radio Access Technology (RAT) is active for the current data bearer.";
CM_ SG_ 1155 TCU_mdmDataCallStatus "Indicates the current state of the Packet Data Protocol (PDP) context.";
CM_ SG_ 1155 TCU_mdmNSAAvailable "TCU ECU: mdm NSA available";
CM_ SG_ 1155 TCU_mdmPCIID "TCU ECU: mdm PCIID";
CM_ SG_ 1155 TCU_mdmMnc "TCU ECU: mdm mnc";
CM_ SG_ 1155 TCU_mdmMcc "TCU ECU: mdm mcc";
CM_ SG_ 1155 TCU_mdmTxKiloBytes "TCU ECU: mdm tx kilo bytes";
CM_ SG_ 1155 TCU_mdmDataCallTermReason "Indicates the internal reason which the Data Call was terminated.";
CM_ SG_ 1155 TCU_mdmDataCallTermCode "Indicates the termination code informed by the network that caused the Data Call termination.";
CM_ SG_ 1155 TCU_cellularSMState "Indicates the current state of cellular state machine.";
CM_ SG_ 1155 TCU_tcuSMState "Reports the state of the Telematics Control Unit (TCU) state machine.";
CM_ SG_ 1155 TCU_checkInternetFailCount "Reports the count of unsuccessful cellular connectivity checks.";
CM_ SG_ 1155 TCU_mdmBand "Indicates the band which the baseband processor is currently attached to the cellular network.";
CM_ SG_ 1155 TCU_wakeSource "Indicates the source of wake event in the modem.";
BA_DEF_ "BusType" STRING;
BA_DEF_ "DBName" STRING;
BA_DEF_ "Baudrate" INT 0 1000000;
BA_DEF_ "BaudrateCANFD" INT 0 16000000;
BA_DEF_ "Manufacturer" STRING;
BA_DEF_ "FirmwareVersion" STRING;
BA_DEF_ "VehicleModel" STRING;
BA_DEF_ BU_ "ECU" STRING;
BA_DEF_ BO_ "GenMsgCycleTime" INT 0 3600000;
BA_DEF_ BO_ "GenMsgSendType" ENUM "Cyclic","NotUsed","NotUsed","NotUsed","NotUsed","NotUsed","NotUsed","IfActive","NoMsgSendType","NotUsed";
BA_DEF_ BO_ "VFrameFormat" ENUM "StandardCAN","ExtendedCAN","reserved","J1939PG","reserved","reserved","reserved","reserved","reserved","reserved","reserved","reserved","reserved","reserved","StandardCAN_FD","ExtendedCAN_FD";
BA_DEF_ BO_ "CANFD_BRS" ENUM "0","1";
BA_DEF_ SG_ "GenSigSNA" STRING;
BA_DEF_ SG_ "SystemSignalLongSymbol" STRING;
BA_DEF_ SG_ "Confidence" ENUM "validated","plausible","layout-only","contradicted";
BA_DEF_DEF_ "BusType" "CAN";
BA_DEF_DEF_ "DBName" "";
BA_DEF_DEF_ "Baudrate" 500000;
BA_DEF_DEF_ "BaudrateCANFD" 2000000;
BA_DEF_DEF_ "Manufacturer" "";
BA_DEF_DEF_ "FirmwareVersion" "";
BA_DEF_DEF_ "VehicleModel" "";
BA_DEF_DEF_ "ECU" "";
BA_DEF_DEF_ "GenMsgCycleTime" 0;
BA_DEF_DEF_ "GenMsgSendType" "NoMsgSendType";
BA_DEF_DEF_ "VFrameFormat" "StandardCAN";
BA_DEF_DEF_ "CANFD_BRS" "1";
BA_DEF_DEF_ "GenSigSNA" "";
BA_DEF_DEF_ "SystemSignalLongSymbol" "";
BA_DEF_DEF_ "Confidence" "layout-only";
BA_ "DBName" "Model3_ETH";
BA_ "Manufacturer" "Tesla";
BA_ "FirmwareVersion" "2026.26.6.5";
BA_ "VehicleModel" "Model 3";
BA_ "ECU" BU_ BB "BB";
BA_ "ECU" BU_ GTW "GTW";
BA_ "ECU" BU_ IDB "IDB";
BA_ "ECU" BU_ TCU "TCU";
BA_ "ECU" BU_ TCU2 "TCU2";
BA_ "ECU" BU_ UI "UI";
BA_ "ECU" BU_ UIS "UIS";
BA_ "ECU" BU_ VCSEAT2L "VCSEAT2L";
BA_ "ECU" BU_ VCSEAT2R "VCSEAT2R";
BA_ "GenMsgCycleTime" BO_ 943 10;
BA_ "GenMsgSendType" BO_ 943 0;
BA_ "GenMsgCycleTime" BO_ 888 1000;
BA_ "GenMsgSendType" BO_ 888 0;
BA_ "GenMsgCycleTime" BO_ 282 1000;
BA_ "GenMsgSendType" BO_ 282 0;
BA_ "GenMsgCycleTime" BO_ 838 1000;
BA_ "GenMsgSendType" BO_ 838 0;
BA_ "GenMsgCycleTime" BO_ 904 1000;
BA_ "GenMsgSendType" BO_ 904 0;
BA_ "GenMsgCycleTime" BO_ 2047 100;
BA_ "GenMsgSendType" BO_ 2047 0;
BA_ "GenMsgCycleTime" BO_ 1638 250;
BA_ "GenMsgSendType" BO_ 1638 0;
BA_ "GenMsgCycleTime" BO_ 1080 100;
BA_ "GenMsgSendType" BO_ 1080 0;
BA_ "GenMsgCycleTime" BO_ 1656 100;
BA_ "GenMsgSendType" BO_ 1656 0;
BA_ "GenMsgCycleTime" BO_ 2033 2000;
BA_ "GenMsgSendType" BO_ 2033 0;
BA_ "GenMsgCycleTime" BO_ 2026 1000;
BA_ "GenMsgSendType" BO_ 2026 0;
BA_ "GenMsgCycleTime" BO_ 60 2000;
BA_ "GenMsgSendType" BO_ 60 0;
BA_ "GenMsgCycleTime" BO_ 1370 250;
BA_ "GenMsgSendType" BO_ 1370 0;
BA_ "GenMsgCycleTime" BO_ 840 1000;
BA_ "GenMsgSendType" BO_ 840 0;
BA_ "GenMsgCycleTime" BO_ 1005 1000;
BA_ "GenMsgSendType" BO_ 1005 0;
BA_ "GenMsgCycleTime" BO_ 1112 100;
BA_ "GenMsgSendType" BO_ 1112 0;
BA_ "GenMsgCycleTime" BO_ 828 10000;
BA_ "GenMsgSendType" BO_ 828 0;
BA_ "GenMsgCycleTime" BO_ 1415 1000;
BA_ "GenMsgSendType" BO_ 1415 0;
BA_ "GenMsgCycleTime" BO_ 1412 1000;
BA_ "GenMsgSendType" BO_ 1412 0;
BA_ "GenMsgCycleTime" BO_ 1159 1000;
BA_ "GenMsgSendType" BO_ 1159 0;
BA_ "GenMsgCycleTime" BO_ 1155 1000;
BA_ "GenMsgSendType" BO_ 1155 0;
BA_ "Confidence" SG_ 943 BB_statusChecksum 0;
BA_ "Confidence" SG_ 943 BB_statusCounter 0;
BA_ "Confidence" SG_ 943 BB_sOutputRod 0;
BA_ "Confidence" SG_ 943 BB_sOutputRodQF 0;
BA_ "Confidence" SG_ 943 BB_sInputRod 0;
BA_ "Confidence" SG_ 943 BB_sInputRodQF 0;
BA_ "Confidence" SG_ 943 BB_driverBrakeApply 0;
BA_ "Confidence" SG_ 943 BB_driverBrakeApplyQF 0;
BA_ "Confidence" SG_ 943 BB_boosterStatus 0;
BA_ "Confidence" SG_ 943 BB_warningLampRequest 0;
BA_ "Confidence" SG_ 943 BB_brakeFluidLevel 0;
BA_ "Confidence" SG_ 943 BB_internalState 0;
BA_ "Confidence" SG_ 943 BB_unfilteredFluidLevelLow 0;
BA_ "Confidence" SG_ 888 GTW_GTW_SOS_ECALL_RQST 0;
BA_ "Confidence" SG_ 888 GTW_LTE_ECALL_LOCK 0;
BA_ "Confidence" SG_ 282 GTW_BKP_BATT_MON 1;
BA_ "GenSigSNA" SG_ 282 GTW_BKP_BATT_MON "4095";
BA_ "Confidence" SG_ 282 GTW_BKP_BATT_NTC_P 1;
BA_ "GenSigSNA" SG_ 282 GTW_BKP_BATT_NTC_P "4095";
BA_ "Confidence" SG_ 282 GTW_ECALL_GPS_ANT_BIAS 1;
BA_ "GenSigSNA" SG_ 282 GTW_ECALL_GPS_ANT_BIAS "4095";
BA_ "Confidence" SG_ 282 GTW_ECALL_MIC_DIAG 1;
BA_ "GenSigSNA" SG_ 282 GTW_ECALL_MIC_DIAG "4095";
BA_ "Confidence" SG_ 282 GTW_SOS_ECALL_nRQST_BUF 1;
BA_ "GenSigSNA" SG_ 282 GTW_SOS_ECALL_nRQST_BUF "4095";
BA_ "Confidence" SG_ 838 GTW_autopilotOverrideState 0;
BA_ "Confidence" SG_ 838 GTW_autopilotConfig 0;
BA_ "Confidence" SG_ 838 GTW_autopilotOverrideConfig 0;
BA_ "Confidence" SG_ 838 GTW_autopilotConfigSource 0;
BA_ "Confidence" SG_ 838 GTW_autopilotOverrideExpireTime 0;
BA_ "Confidence" SG_ 904 GTW_VEH_canBusActivity 0;
BA_ "Confidence" SG_ 904 GTW_PARTY_canBusActivity 0;
BA_ "Confidence" SG_ 904 GTW_CH_canBusActivity 0;
BA_ "Confidence" SG_ 904 GTW_VEH_txWarning 0;
BA_ "Confidence" SG_ 904 GTW_PARTY_txWarning 0;
BA_ "Confidence" SG_ 904 GTW_CH_txWarning 0;
BA_ "Confidence" SG_ 904 GTW_VEH_rxWarning 0;
BA_ "Confidence" SG_ 904 GTW_PARTY_rxWarning 0;
BA_ "Confidence" SG_ 904 GTW_CH_rxWarning 0;
BA_ "Confidence" SG_ 904 GTW_VEH_faultConfinement 0;
BA_ "Confidence" SG_ 904 GTW_PARTY_faultConfinement 0;
BA_ "Confidence" SG_ 904 GTW_CH_faultConfinement 0;
BA_ "Confidence" SG_ 2047 GTW_deliveryStatus 0;
BA_ "Confidence" SG_ 2047 GTW_cabinPTCHeaterType 0;
BA_ "Confidence" SG_ 2047 GTW_rightHandDrive 0;
BA_ "Confidence" SG_ 2047 GTW_rearLightType 0;
BA_ "Confidence" SG_ 2047 GTW_headlamps 0;
BA_ "Confidence" SG_ 2047 GTW_country 0;
BA_ "Confidence" SG_ 2047 GTW_tireType 0;
BA_ "Confidence" SG_ 2047 GTW_dasHw 0;
BA_ "Confidence" SG_ 2047 GTW_brakeHWType 0;
BA_ "Confidence" SG_ 2047 GTW_restraintsHardwareType 0;
BA_ "Confidence" SG_ 2047 GTW_drivetrainType 0;
BA_ "Confidence" SG_ 2047 GTW_radarHeaterType 0;
BA_ "Confidence" SG_ 2047 GTW_exteriorTrimType 0;
BA_ "Confidence" SG_ 2047 GTW_frontSeatHeaters 0;
BA_ "Confidence" SG_ 2047 GTW_rearSeatHeaters 0;
BA_ "Confidence" SG_ 2047 GTW_eCallAntennaHW 0;
BA_ "Confidence" SG_ 2047 GTW_homelinkType 0;
BA_ "Confidence" SG_ 2047 GTW_vdcType 0;
BA_ "Confidence" SG_ 2047 GTW_memoryMirrors 0;
BA_ "Confidence" SG_ 2047 GTW_powerLiftgateType 0;
BA_ "Confidence" SG_ 2047 GTW_lumbarECUType 0;
BA_ "Confidence" SG_ 2047 GTW_rearSeatHeaterType 0;
BA_ "Confidence" SG_ 2047 GTW_auxParkLamps 0;
BA_ "Confidence" SG_ 2047 GTW_interiorCabinRadarType 0;
BA_ "Confidence" SG_ 2047 GTW_hvacPanelVaneType 0;
BA_ "Confidence" SG_ 2047 GTW_intakeAirFilterType 0;
BA_ "Confidence" SG_ 2047 GTW_eBuckConfig 0;
BA_ "Confidence" SG_ 2047 GTW_steeringHeaterEnabled 0;
BA_ "Confidence" SG_ 2047 GTW_activeHighBeam 0;
BA_ "Confidence" SG_ 2047 GTW_airbagCutoffSwitch 0;
BA_ "Confidence" SG_ 2047 GTW_intrusionSensorType 0;
BA_ "Confidence" SG_ 2047 GTW_spoilerType 0;
BA_ "Confidence" SG_ 2047 GTW_backupCameraType 0;
BA_ "Confidence" SG_ 2047 GTW_rearFogLamps 0;
BA_ "Confidence" SG_ 2047 GTW_roofType 0;
BA_ "Confidence" SG_ 2047 GTW_thirdRowSeatType 0;
BA_ "Confidence" SG_ 2047 GTW_autopilot 0;
BA_ "Confidence" SG_ 2047 GTW_superchargingAccess 0;
BA_ "Confidence" SG_ 2047 GTW_exteriorColor 0;
BA_ "Confidence" SG_ 2047 GTW_pedestrianWarningSound 0;
BA_ "Confidence" SG_ 2047 GTW_steeringColumnUJointType 0;
BA_ "Confidence" SG_ 2047 GTW_bPillarNFCParam 0;
BA_ "Confidence" SG_ 2047 GTW_interiorLighting 0;
BA_ "Confidence" SG_ 2047 GTW_headlightLevelerType 0;
BA_ "Confidence" SG_ 2047 GTW_numberHVILNodes 0;
BA_ "Confidence" SG_ 2047 GTW_mapRegion 0;
BA_ "Confidence" SG_ 2047 GTW_performancePackage 0;
BA_ "Confidence" SG_ 2047 GTW_chassisType 0;
BA_ "Confidence" SG_ 2047 GTW_airSuspension 0;
BA_ "Confidence" SG_ 2047 GTW_centerConsoleControllerType 0;
BA_ "Confidence" SG_ 2047 GTW_autopilotCameraType 0;
BA_ "Confidence" SG_ 2047 GTW_connectivityPackage 0;
BA_ "Confidence" SG_ 2047 GTW_plcSupportType 0;
BA_ "Confidence" SG_ 2047 GTW_badgingVersion 0;
BA_ "Confidence" SG_ 2047 GTW_packEnergy 0;
BA_ "Confidence" SG_ 2047 GTW_frontSeatReclinerHardware 0;
BA_ "Confidence" SG_ 2047 GTW_brakeLineSwitchType 0;
BA_ "Confidence" SG_ 2047 GTW_softRange 0;
BA_ "Confidence" SG_ 2047 GTW_refrigerantType 0;
BA_ "Confidence" SG_ 2047 GTW_wheelType 0;
BA_ "Confidence" SG_ 2047 GTW_brakeActuationType 0;
BA_ "Confidence" SG_ 2047 GTW_secondRowSeatType 0;
BA_ "Confidence" SG_ 2047 GTW_secondRowSeatMotorType 0;
BA_ "Confidence" SG_ 2047 GTW_birthday 0;
BA_ "Confidence" SG_ 2047 GTW_eCallEnabled 0;
BA_ "Confidence" SG_ 2047 GTW_parkAssistECUType 0;
BA_ "Confidence" SG_ 2047 GTW_passengerAirbagType 0;
BA_ "Confidence" SG_ 2047 GTW_forwardRadarHw 0;
BA_ "Confidence" SG_ 2047 GTW_frontSeatType 0;
BA_ "Confidence" SG_ 2047 GTW_secondRowDisplayType 0;
BA_ "Confidence" SG_ 2047 GTW_wirelessPhoneChargerType 0;
BA_ "Confidence" SG_ 2047 GTW_ethernetTunerType 0;
BA_ "Confidence" SG_ 2047 GTW_interiorTrimType 0;
BA_ "Confidence" SG_ 2047 GTW_gloveboxUSBType 0;
BA_ "Confidence" SG_ 2047 GTW_coolantPumpType 0;
BA_ "Confidence" SG_ 2047 GTW_epblHwType 0;
BA_ "Confidence" SG_ 2047 GTW_epbrHwType 0;
BA_ "Confidence" SG_ 2047 GTW_blowerMotorType 0;
BA_ "Confidence" SG_ 2047 GTW_powerMirrorFoldType 0;
BA_ "Confidence" SG_ 2047 GTW_frontUsbHubType 0;
BA_ "Confidence" SG_ 2047 GTW_superManifoldType 0;
BA_ "Confidence" SG_ 2047 GTW_rcmLocation 0;
BA_ "Confidence" SG_ 2047 GTW_autopilotExteriorCameraType 0;
BA_ "Confidence" SG_ 2047 GTW_sirenType 0;
BA_ "Confidence" SG_ 2047 GTW_hornType 0;
BA_ "Confidence" SG_ 2047 GTW_passengerTrackMotorType 0;
BA_ "Confidence" SG_ 2047 GTW_steeringColumnMotorType 0;
BA_ "Confidence" SG_ 2047 GTW_refrigACLineType 0;
BA_ "Confidence" SG_ 2047 GTW_refrigFilterType 0;
BA_ "Confidence" SG_ 2047 GTW_diBurnInType 0;
BA_ "Confidence" SG_ 2047 GTW_specialBadgingType 0;
BA_ "Confidence" SG_ 2047 GTW_chassisSubType 0;
BA_ "Confidence" SG_ 2047 GTW_towPackage 0;
BA_ "Confidence" SG_ 2047 GTW_refrigLccType 0;
BA_ "Confidence" SG_ 2047 GTW_restraintControlsType 0;
BA_ "Confidence" SG_ 2047 GTW_caliperColorType 0;
BA_ "Confidence" SG_ 2047 GTW_wiperMotorType 0;
BA_ "Confidence" SG_ 2047 GTW_frontOverheadConsoleType 0;
BA_ "Confidence" SG_ 2047 GTW_shifterType 0;
BA_ "Confidence" SG_ 2047 GTW_compressorType 0;
BA_ "Confidence" SG_ 2047 GTW_twelveVBatteryType 0;
BA_ "Confidence" SG_ 2047 GTW_efuseSWConfig 0;
BA_ "Confidence" SG_ 2047 GTW_tollCollectionModuleType 0;
BA_ "Confidence" SG_ 2047 GTW_bleEndpointUpdateMethod 0;
BA_ "Confidence" SG_ 2047 GTW_steeringWheelControllerType 0;
BA_ "Confidence" SG_ 2047 GTW_frontSeatVentilationEnabled 0;
BA_ "Confidence" SG_ 2047 GTW_gloveboxActuatorType 0;
BA_ "Confidence" SG_ 2047 GTW_epasType 0;
BA_ "Confidence" SG_ 2047 GTW_homologationRegionOverride 0;
BA_ "Confidence" SG_ 2047 GTW_windowCommandsPermissionType 0;
BA_ "Confidence" SG_ 2047 GTW_rgbInteriorLightingEnabled 0;
BA_ "Confidence" SG_ 2047 GTW_windshieldWiperHeaterType 0;
BA_ "Confidence" SG_ 2047 GTW_thirdRowSeatReclinerType 0;
BA_ "Confidence" SG_ 2047 GTW_driveInterfaceType 0;
BA_ "Confidence" SG_ 2047 GTW_efficiencyPackage 0;
BA_ "Confidence" SG_ 2047 GTW_visorLightType 0;
BA_ "Confidence" SG_ 2047 GTW_gnssAntennaType 0;
BA_ "Confidence" SG_ 2047 GTW_airDistributionBoxType 0;
BA_ "Confidence" SG_ 2047 GTW_frontSeatHeatersEnabled 0;
BA_ "Confidence" SG_ 2047 GTW_windshieldWiperHeaterEnabled 0;
BA_ "Confidence" SG_ 2047 GTW_alcoholInterlockType 0;
BA_ "Confidence" SG_ 2047 GTW_fasciaType 0;
BA_ "Confidence" SG_ 2047 GTW_powerSteeringColumn 0;
BA_ "Confidence" SG_ 2047 GTW_frontSeatHeaterType 0;
BA_ "Confidence" SG_ 2047 GTW_softPerformanceLimit 0;
BA_ "Confidence" SG_ 2047 GTW_gsrFeatureType 0;
BA_ "Confidence" SG_ 2047 GTW_immersiveAudio 0;
BA_ "Confidence" SG_ 2047 GTW_frontSeatVentilationType 0;
BA_ "Confidence" SG_ 2047 GTW_passengerOccupancySensorType 0;
BA_ "Confidence" SG_ 2047 GTW_packPerformanceDeviation 0;
BA_ "Confidence" SG_ 2047 GTW_frontFogLamps 0;
BA_ "Confidence" SG_ 2047 GTW_driverOccupancySensorType 0;
BA_ "Confidence" SG_ 2047 GTW_audioType 0;
BA_ "Confidence" SG_ 2047 GTW_thighExtenderType 0;
BA_ "Confidence" SG_ 2047 GTW_occupancyClassificationFeatu 0;
BA_ "SystemSignalLongSymbol" SG_ 2047 GTW_occupancyClassificationFeatu "GTW_occupancyClassificationFeatureType";
BA_ "Confidence" SG_ 2047 GTW_frontControllerArchitectureT 0;
BA_ "SystemSignalLongSymbol" SG_ 2047 GTW_frontControllerArchitectureT "GTW_frontControllerArchitectureType";
BA_ "Confidence" SG_ 2047 GTW_domeLightType 0;
BA_ "Confidence" SG_ 2047 GTW_tpmsType 0;
BA_ "Confidence" SG_ 2047 GTW_authenticationEndpointLayout 0;
BA_ "Confidence" SG_ 2047 GTW_socSleepOverride 0;
BA_ "Confidence" SG_ 2047 GTW_r79BehaviorOverride 0;
BA_ "Confidence" SG_ 2047 GTW_steeringHeaterType 0;
BA_ "Confidence" SG_ 2047 GTW_narrowWipingSupported 0;
BA_ "Confidence" SG_ 2047 GTW_frontSeatHeaterGridType 0;
BA_ "Confidence" SG_ 2047 GTW_frontSeatSideSwitchType 0;
BA_ "Confidence" SG_ 2047 GTW_sohRegulatoryStatus 0;
BA_ "Confidence" SG_ 2047 GTW_passengerTiltMotorType 0;
BA_ "Confidence" SG_ 2047 GTW_frunkInteriorReleaseType 0;
BA_ "Confidence" SG_ 2047 GTW_m3yBusArchitecture 0;
BA_ "Confidence" SG_ 2047 GTW_passengerLiftMotorType 0;
BA_ "Confidence" SG_ 2047 GTW_interiorUpperTrimType 0;
BA_ "Confidence" SG_ 2047 GTW_blindSpotIndicatorLightType 0;
BA_ "Confidence" SG_ 2047 GTW_wiperMotorAsicType 0;
BA_ "Confidence" SG_ 2047 GTW_hvacCaseDoorType 0;
BA_ "Confidence" SG_ 2047 GTW_rduCableType 0;
BA_ "Confidence" SG_ 2047 GTW_parkTelltaleBehaviorType 0;
BA_ "Confidence" SG_ 2047 GTW_numberKeyCardsPairedInFactor 0;
BA_ "SystemSignalLongSymbol" SG_ 2047 GTW_numberKeyCardsPairedInFactor "GTW_numberKeyCardsPairedInFactory";
BA_ "Confidence" SG_ 2047 GTW_secondRowSeatVentilationType 0;
BA_ "Confidence" SG_ 2047 GTW_thirdRowSeatHeaterType 0;
BA_ "Confidence" SG_ 2047 GTW_interiorCameraType 0;
BA_ "Confidence" SG_ 2047 GTW_frontFasciaCameraType 0;
BA_ "Confidence" SG_ 2047 GTW_interiorCamFanType 0;
BA_ "Confidence" SG_ 2047 GTW_puddleLampType 0;
BA_ "Confidence" SG_ 2047 GTW_solarLensType 0;
BA_ "Confidence" SG_ 2047 GTW_liftgateGeometryType 0;
BA_ "Confidence" SG_ 2047 GTW_repeaterAeroRibType 0;
BA_ "Confidence" SG_ 2047 GTW_highTipForceWiperArmsType 0;
BA_ "Confidence" SG_ 2047 GTW_rcmUndersideAbuseZThreshold 0;
BA_ "Confidence" SG_ 2047 GTW_rcmUndersideAbuseYThreshold 0;
BA_ "Confidence" SG_ 2047 GTW_rcmUndersideAbuseWindow 0;
BA_ "Confidence" SG_ 2047 GTW_automaticFeatureResetPackage 0;
BA_ "Confidence" SG_ 2047 GTW_autopilotFeaturePackage 0;
BA_ "Confidence" SG_ 2047 GTW_doorLatchType 0;
BA_ "Confidence" SG_ 2047 GTW_headlinerMaterialType 0;
BA_ "Confidence" SG_ 2047 GTW_glareShieldHeaterType 0;
BA_ "Confidence" SG_ 2047 GTW_rearLightHardwareVariant 0;
BA_ "Confidence" SG_ 2047 GTW_fasciaHarnessCleanPointType 0;
BA_ "Confidence" SG_ 2047 GTW_epasSubType 0;
BA_ "Confidence" SG_ 2047 GTW_wiperSupplyChainOrigin 0;
BA_ "GenSigSNA" SG_ 2047 GTW_wiperSupplyChainOrigin "0";
BA_ "Confidence" SG_ 2047 GTW_windowPinchParameterType 0;
BA_ "Confidence" SG_ 2047 GTW_badgingMaterialType 0;
BA_ "Confidence" SG_ 2047 GTW_mRecordVersion 0;
BA_ "Confidence" SG_ 2047 GTW_tcuType 0;
BA_ "Confidence" SG_ 2047 GTW_carbComplianceBehaviorType 0;
BA_ "Confidence" SG_ 2047 GTW_indirectTPMSCalibrationType 0;
BA_ "Confidence" SG_ 2047 GTW_v2xEnabled 0;
BA_ "Confidence" SG_ 2047 GTW_liftgateStrutType 0;
BA_ "Confidence" SG_ 2047 GTW_exteriorMicrophoneType 0;
BA_ "Confidence" SG_ 2047 GTW_roofGlassType 0;
BA_ "Confidence" SG_ 2047 GTW_pedalMapNameOverride 0;
BA_ "Confidence" SG_ 1638 GTW_diagRemainingSeconds 0;
BA_ "Confidence" SG_ 1638 GTW_diagSessionActive 0;
BA_ "Confidence" SG_ 1638 GTW_diagLevel 0;
BA_ "Confidence" SG_ 1638 GTW_diagUnlockProcedureActive 0;
BA_ "Confidence" SG_ 1638 GTW_diagOverrideActive 0;
BA_ "Confidence" SG_ 1638 GTW_diagPhysicalLinkEstablished 0;
BA_ "Confidence" SG_ 1080 GTW_ethGotoSleep 0;
BA_ "Confidence" SG_ 1080 GTW_ethWakeUpBus 0;
BA_ "Confidence" SG_ 1080 GTW_vehBusAsleep 0;
BA_ "Confidence" SG_ 1080 GTW_ethHeartBeatCounter 0;
BA_ "Confidence" SG_ 1080 GTW_ethWakeUpReason 0;
BA_ "Confidence" SG_ 1656 GTW_gearControlChecksum 0;
BA_ "Confidence" SG_ 1656 GTW_gearControlCounter 0;
BA_ "Confidence" SG_ 1656 GTW_gearShiftRequest 0;
BA_ "GenSigSNA" SG_ 1656 GTW_gearShiftRequest "0";
BA_ "Confidence" SG_ 1656 GTW_osdActive 0;
BA_ "Confidence" SG_ 1656 GTW_primaryGearControlStatus 0;
BA_ "Confidence" SG_ 1656 GTW_gearStripEnable 0;
BA_ "Confidence" SG_ 1656 GTW_showNeutralButton 0;
BA_ "Confidence" SG_ 1656 GTW_showAutoParkButton 0;
BA_ "Confidence" SG_ 1656 GTW_autoParkRequest 0;
BA_ "Confidence" SG_ 1656 GTW_smartShiftStatus 0;
BA_ "GenSigSNA" SG_ 1656 GTW_smartShiftStatus "0";
BA_ "Confidence" SG_ 1656 GTW_processingRDgestures 0;
BA_ "Confidence" SG_ 1656 GTW_processingTapPgestures 0;
BA_ "Confidence" SG_ 1656 GTW_gearStripChangeReason 0;
BA_ "GenSigSNA" SG_ 1656 GTW_gearStripChangeReason "0";
BA_ "Confidence" SG_ 1656 GTW_touchActive 0;
BA_ "Confidence" SG_ 1656 GTW_steamOff 0;
BA_ "Confidence" SG_ 1656 GTW_screenPCBTemperature 1;
BA_ "GenSigSNA" SG_ 1656 GTW_screenPCBTemperature "2047";
BA_ "Confidence" SG_ 2033 GTW_hrlIndex 1;
BA_ "Confidence" SG_ 2033 GTW_hrlSdCardSizeGB 0;
BA_ "GenSigSNA" SG_ 2033 GTW_hrlSdCardSizeGB "0";
BA_ "Confidence" SG_ 2033 GTW_hrlState 0;
BA_ "Confidence" SG_ 2033 GTW_hrlTriggerDuration 1;
BA_ "Confidence" SG_ 2033 GTW_hrlTriggerType 0;
BA_ "Confidence" SG_ 2033 GTW_hrlTriggerId 1;
BA_ "Confidence" SG_ 2026 GTW_hrlEventStartEpoch 1;
BA_ "Confidence" SG_ 2026 GTW_hrlEventEndEpoch 1;
BA_ "Confidence" SG_ 60 GTW_infoIndex 1;
BA_ "Confidence" SG_ 60 GTW_buildType 0;
BA_ "Confidence" SG_ 60 GTW_hardwareId 0;
BA_ "Confidence" SG_ 60 GTW_platformType 0;
BA_ "Confidence" SG_ 60 GTW_appCrc 0;
BA_ "Confidence" SG_ 60 GTW_applicationGitHash 0;
BA_ "Confidence" SG_ 60 GTW_bootGitHash 0;
BA_ "Confidence" SG_ 1370 GTW_mismatchFaultIndex 1;
BA_ "Confidence" SG_ 1370 GTW_mismatchFaultChecksum 0;
BA_ "Confidence" SG_ 1370 GTW_mismatchFaultCounter 0;
BA_ "Confidence" SG_ 1370 GTW_GTWmismatchFault 0;
BA_ "Confidence" SG_ 1370 GTW_BMSmismatchFault 0;
BA_ "Confidence" SG_ 1370 GTW_APSmismatchFault 0;
BA_ "Confidence" SG_ 1370 GTW_BLEEPCENTERmismatchFault 0;
BA_ "Confidence" SG_ 1370 GTW_BLEEPLEFTmismatchFault 0;
BA_ "Confidence" SG_ 1370 GTW_BLEEPREARmismatchFault 0;
BA_ "Confidence" SG_ 1370 GTW_BLEEPRIGHTmismatchFault 0;
BA_ "Confidence" SG_ 1370 GTW_CBCmismatchFault 0;
BA_ "Confidence" SG_ 1370 GTW_CMPmismatchFault 0;
BA_ "Confidence" SG_ 1370 GTW_CPmismatchFault 0;
BA_ "Confidence" SG_ 1370 GTW_DIFmismatchFault 0;
BA_ "Confidence" SG_ 1370 GTW_DIRmismatchFault 0;
BA_ "Confidence" SG_ 1370 GTW_EPAS3PmismatchFault 0;
BA_ "Confidence" SG_ 1370 GTW_EPAS3SmismatchFault 0;
BA_ "Confidence" SG_ 1370 GTW_EPBLmismatchFault 0;
BA_ "Confidence" SG_ 1370 GTW_EPBRmismatchFault 0;
BA_ "Confidence" SG_ 1370 GTW_ESPCALmismatchFault 0;
BA_ "Confidence" SG_ 1370 GTW_ESPmismatchFault 0;
BA_ "Confidence" SG_ 1370 GTW_HCM3LmismatchFault 0;
BA_ "Confidence" SG_ 1370 GTW_HCM3RmismatchFault 0;
BA_ "Confidence" SG_ 1370 GTW_HCMLmismatchFault 0;
BA_ "Confidence" SG_ 1370 GTW_HCMRmismatchFault 0;
BA_ "Confidence" SG_ 1370 GTW_HVPmismatchFault 0;
BA_ "Confidence" SG_ 1370 GTW_IBSTCALmismatchFault 0;
BA_ "Confidence" SG_ 1370 GTW_IBSTmismatchFault 0;
BA_ "Confidence" SG_ 1370 GTW_LVBMSmismatchFault 0;
BA_ "Confidence" SG_ 1370 GTW_OCS1PmismatchFault 0;
BA_ "Confidence" SG_ 1370 GTW_OPCFmismatchFault 0;
BA_ "Confidence" SG_ 1370 GTW_OPCRmismatchFault 0;
BA_ "Confidence" SG_ 1370 GTW_PARKmismatchFault 0;
BA_ "Confidence" SG_ 1370 GTW_PCSCPU2mismatchFault 0;
BA_ "Confidence" SG_ 1370 GTW_PCSmismatchFault 0;
BA_ "Confidence" SG_ 1370 GTW_PMFmismatchFault 0;
BA_ "Confidence" SG_ 1370 GTW_PMRmismatchFault 0;
BA_ "Confidence" SG_ 1370 GTW_PTCmismatchFault 0;
BA_ "Confidence" SG_ 1370 GTW_RCMCALmismatchFault 0;
BA_ "Confidence" SG_ 1370 GTW_RCMmismatchFault 0;
BA_ "Confidence" SG_ 1370 GTW_SCCMmismatchFault 0;
BA_ "Confidence" SG_ 1370 GTW_SDCRmismatchFault 0;
BA_ "Confidence" SG_ 1370 GTW_SWCmismatchFault 0;
BA_ "Confidence" SG_ 1370 GTW_THSmismatchFault 0;
BA_ "Confidence" SG_ 1370 GTW_VCFRONTmismatchFault 0;
BA_ "Confidence" SG_ 1370 GTW_VCLEFTmismatchFault 0;
BA_ "Confidence" SG_ 1370 GTW_VCRIGHTmismatchFault 0;
BA_ "Confidence" SG_ 1370 GTW_VCSECmismatchFault 0;
BA_ "Confidence" SG_ 1370 GTW_PMmismatchFault 0;
BA_ "Confidence" SG_ 840 GTW_vehicleVersionMatchStatus 0;
BA_ "Confidence" SG_ 840 GTW_hwtype 0;
BA_ "GenSigSNA" SG_ 840 GTW_hwtype "0";
BA_ "Confidence" SG_ 840 GTW_jcanProductName 0;
BA_ "GenSigSNA" SG_ 840 GTW_jcanProductName "0";
BA_ "Confidence" SG_ 840 GTW_uptimeSeconds 1;
BA_ "Confidence" SG_ 840 GTW_boardRevision 0;
BA_ "Confidence" SG_ 840 GTW_touchcoreOsType 0;
BA_ "Confidence" SG_ 840 GTW_sentryModeState 0;
BA_ "GenSigSNA" SG_ 840 GTW_sentryModeState "6";
BA_ "Confidence" SG_ 840 GTW_secureBootEnabled 0;
BA_ "Confidence" SG_ 840 GTW_socSleepType 0;
BA_ "GenSigSNA" SG_ 840 GTW_socSleepType "0";
BA_ "Confidence" SG_ 840 GTW_resetType 0;
BA_ "GenSigSNA" SG_ 840 GTW_resetType "0";
BA_ "Confidence" SG_ 1005 GTW_peripheralConfirmedUpdateNee 1;
BA_ "SystemSignalLongSymbol" SG_ 1005 GTW_peripheralConfirmedUpdateNee "GTW_peripheralConfirmedUpdateNeeded";
BA_ "Confidence" SG_ 1005 GTW_ocuFailed 0;
BA_ "Confidence" SG_ 1005 GTW_ecuUpdateStarted 0;
BA_ "Confidence" SG_ 1005 GTW_updateStarted 1;
BA_ "Confidence" SG_ 1112 GTW_nmGoingToSleep 0;
BA_ "Confidence" SG_ 1112 GTW_nmWakeUpBus 0;
BA_ "Confidence" SG_ 1112 GTW_chBusAsleep 0;
BA_ "Confidence" SG_ 1112 GTW_ethBusAsleep 0;
BA_ "Confidence" SG_ 1112 GTW_nmKeepAwakeReason 0;
BA_ "GenSigSNA" SG_ 1112 GTW_nmKeepAwakeReason "0";
BA_ "Confidence" SG_ 1112 GTW_nmWakeUpReason 0;
BA_ "Confidence" SG_ 1112 GTW_ethKeepAwakeReason 0;
BA_ "GenSigSNA" SG_ 1112 GTW_ethKeepAwakeReason "0";
BA_ "Confidence" SG_ 1112 GTW_nmDebugWakeUp 0;
BA_ "Confidence" SG_ 1112 GTW_OTAKeepAwake 0;
BA_ "Confidence" SG_ 1112 GTW_smsPokeReceived 0;
BA_ "Confidence" SG_ 828 IDB_infoIndex 1;
BA_ "Confidence" SG_ 828 IDB_infoPcbaID 0;
BA_ "Confidence" SG_ 828 IDB_infoAssemblyID 0;
BA_ "Confidence" SG_ 828 IDB_infoUsageID 0;
BA_ "Confidence" SG_ 828 IDB_infoSubUsageID 0;
BA_ "Confidence" SG_ 1415 TCU2_tc10Version 0;
BA_ "GenSigSNA" SG_ 1415 TCU2_tc10Version "0";
BA_ "Confidence" SG_ 1412 TCU2_logMux 1;
BA_ "Confidence" SG_ 1412 TCU2_cpuTemp 0;
BA_ "Confidence" SG_ 1412 TCU2_cpuUsage 0;
BA_ "Confidence" SG_ 1412 TCU2_mdmCoreTemperature 0;
BA_ "Confidence" SG_ 1412 TCU2_availableMemory 0;
BA_ "Confidence" SG_ 1412 TCU2_pwm 0;
BA_ "Confidence" SG_ 1412 TCU2_pwmcap 0;
BA_ "Confidence" SG_ 1412 TCU2_totalResumes 0;
BA_ "Confidence" SG_ 1412 TCU2_mdmUplinkQueueSize 0;
BA_ "Confidence" SG_ 1412 TCU2_mdmRSRP 0;
BA_ "Confidence" SG_ 1412 TCU2_mdmSINR 0;
BA_ "Confidence" SG_ 1412 TCU2_mdmUplinkAllowedRate 0;
BA_ "Confidence" SG_ 1412 TCU2_mdmUplinkAvgRate 0;
BA_ "Confidence" SG_ 1412 TCU2_mdmServiceState 0;
BA_ "Confidence" SG_ 1412 TCU2_mdmIMSStatus 0;
BA_ "Confidence" SG_ 1412 TCU2_mdmSIMStatus 0;
BA_ "Confidence" SG_ 1412 TCU2_mdmBusyActive 0;
BA_ "GenSigSNA" SG_ 1412 TCU2_mdmBusyActive "4294967295";
BA_ "Confidence" SG_ 1412 TCU2_modemUptime 0;
BA_ "Confidence" SG_ 1412 TCU2_mdmDataRat 0;
BA_ "Confidence" SG_ 1412 TCU2_mdmDataCallStatus 0;
BA_ "Confidence" SG_ 1412 TCU2_mdmNSAAvailable 0;
BA_ "Confidence" SG_ 1412 TCU2_mdmPCIID 0;
BA_ "Confidence" SG_ 1412 TCU2_mdmMnc 0;
BA_ "Confidence" SG_ 1412 TCU2_mdmMcc 0;
BA_ "Confidence" SG_ 1412 TCU2_mdmTxKiloBytes 0;
BA_ "Confidence" SG_ 1412 TCU2_mdmDataCallTermReason 0;
BA_ "Confidence" SG_ 1412 TCU2_mdmDataCallTermCode 0;
BA_ "Confidence" SG_ 1412 TCU2_cellularSMState 0;
BA_ "Confidence" SG_ 1412 TCU2_tcuSMState 0;
BA_ "Confidence" SG_ 1412 TCU2_checkInternetFailCount 0;
BA_ "Confidence" SG_ 1412 TCU2_mdmBand 0;
BA_ "Confidence" SG_ 1412 TCU2_wakeSource 0;
BA_ "Confidence" SG_ 1159 TCU_tc10Version 0;
BA_ "GenSigSNA" SG_ 1159 TCU_tc10Version "0";
BA_ "Confidence" SG_ 1155 TCU_logMux 1;
BA_ "Confidence" SG_ 1155 TCU_cpuTemp 0;
BA_ "Confidence" SG_ 1155 TCU_cpuUsage 0;
BA_ "Confidence" SG_ 1155 TCU_mdmCoreTemperature 0;
BA_ "Confidence" SG_ 1155 TCU_availableMemory 0;
BA_ "Confidence" SG_ 1155 TCU_pwm 0;
BA_ "Confidence" SG_ 1155 TCU_pwmcap 0;
BA_ "Confidence" SG_ 1155 TCU_totalResumes 0;
BA_ "Confidence" SG_ 1155 TCU_mdmUplinkQueueSize 0;
BA_ "Confidence" SG_ 1155 TCU_mdmRSRP 0;
BA_ "Confidence" SG_ 1155 TCU_mdmSINR 0;
BA_ "Confidence" SG_ 1155 TCU_mdmUplinkAllowedRate 0;
BA_ "Confidence" SG_ 1155 TCU_mdmUplinkAvgRate 0;
BA_ "Confidence" SG_ 1155 TCU_mdmServiceState 0;
BA_ "Confidence" SG_ 1155 TCU_mdmIMSStatus 0;
BA_ "Confidence" SG_ 1155 TCU_mdmSIMStatus 0;
BA_ "Confidence" SG_ 1155 TCU_mdmBusyActive 0;
BA_ "GenSigSNA" SG_ 1155 TCU_mdmBusyActive "4294967295";
BA_ "Confidence" SG_ 1155 TCU_modemUptime 0;
BA_ "Confidence" SG_ 1155 TCU_mdmDataRat 0;
BA_ "Confidence" SG_ 1155 TCU_mdmDataCallStatus 0;
BA_ "Confidence" SG_ 1155 TCU_mdmNSAAvailable 0;
BA_ "Confidence" SG_ 1155 TCU_mdmPCIID 0;
BA_ "Confidence" SG_ 1155 TCU_mdmMnc 0;
BA_ "Confidence" SG_ 1155 TCU_mdmMcc 0;
BA_ "Confidence" SG_ 1155 TCU_mdmTxKiloBytes 0;
BA_ "Confidence" SG_ 1155 TCU_mdmDataCallTermReason 0;
BA_ "Confidence" SG_ 1155 TCU_mdmDataCallTermCode 0;
BA_ "Confidence" SG_ 1155 TCU_cellularSMState 0;
BA_ "Confidence" SG_ 1155 TCU_tcuSMState 0;
BA_ "Confidence" SG_ 1155 TCU_checkInternetFailCount 0;
BA_ "Confidence" SG_ 1155 TCU_mdmBand 0;
BA_ "Confidence" SG_ 1155 TCU_wakeSource 0;
VAL_ 943 BB_sOutputRodQF 2 "Faulty" 1 "Normal" 0 "NotInit_orOff" ;
VAL_ 943 BB_sInputRodQF 2 "Faulty" 1 "Normal" 0 "NotInit_orOff" ;
VAL_ 943 BB_driverBrakeApply 1 "DRIVER_APPLYING_BRAKES" 0 "BRAKES_NOT_APPLIED" ;
VAL_ 943 BB_driverBrakeApplyQF 2 "Faulty" 1 "Normal" 0 "NotInit_orOff" ;
VAL_ 943 BB_boosterStatus 6 "ACTUATION" 5 "READY" 4 "ACTIVE_GOOD_CHECK" 3 "DIAGNOSTIC" 2 "FAILURE" 1 "INIT" 0 "OFF" ;
VAL_ 943 BB_warningLampRequest 2 "RED_BRAKE_LAMP_REQUEST" 1 "YELLOW_BRAKE_LAMP_REQUEST" 0 "NO_LAMP_REQUEST" ;
VAL_ 943 BB_brakeFluidLevel 3 "BRAKE_FLUID_LEVEL_INVALID" 2 "BRAKE_FLUID_LEVEL_NORMAL" 1 "BRAKE_FLUID_LEVEL_LOW" 0 "BRAKE_FLUID_LEVEL_UNKNOWN" ;
VAL_ 943 BB_internalState 7 "READY_TO_SHUTDOWN" 6 "POST_DRIVE_CHECK" 5 "TRANSITION_TO_IDLE" 4 "DIAGNOSTIC" 3 "EXTERNAL_BRAKE_REQUEST" 2 "LOCAL_BRAKE_REQUEST" 1 "PRE_DRIVE_CHECK" 0 "NO_MODE_ACTIVE" ;
VAL_ 943 BB_unfilteredFluidLevelLow 1 "LEVEL_LOW" 0 "LEVEL_NORMAL_OR_UNKNOWN_OR_INVALID" ;
VAL_ 282 GTW_BKP_BATT_MON 4095 "SNA" ;
VAL_ 282 GTW_BKP_BATT_NTC_P 4095 "SNA" ;
VAL_ 282 GTW_ECALL_GPS_ANT_BIAS 4095 "SNA" ;
VAL_ 282 GTW_ECALL_MIC_DIAG 4095 "SNA" ;
VAL_ 282 GTW_SOS_ECALL_nRQST_BUF 4095 "SNA" ;
VAL_ 838 GTW_autopilotOverrideState 8 "UNKNOWN" 7 "VEHICLE_MANAGED" 6 "OPTION_OVERRIDE" 5 "OPTION_CODE" 4 "TIMEBOUND_TRIAL" 3 "TIMEBOUND_SUBSCRIPTION" 2 "TRIAL" 1 "SUBSCRIPTION" 0 "BASE" ;
VAL_ 838 GTW_autopilotConfig 4 "BASIC" 3 "SELF_DRIVING" 2 "ENHANCED" 1 "HIGHWAY" 0 "NONE" ;
VAL_ 838 GTW_autopilotOverrideConfig 4 "BASIC" 3 "SELF_DRIVING" 2 "ENHANCED" 1 "HIGHWAY" 0 "NONE" ;
VAL_ 838 GTW_autopilotConfigSource 2 "AUTOPILOT_NOT_UPDATED" 1 "AUTOPILOT" 0 "GATEWAY" ;
VAL_ 904 GTW_VEH_faultConfinement 2 "BUS_OFF" 1 "ERROR_PASSIVE" 0 "ERROR_ACTIVE" ;
VAL_ 904 GTW_PARTY_faultConfinement 2 "BUS_OFF" 1 "ERROR_PASSIVE" 0 "ERROR_ACTIVE" ;
VAL_ 904 GTW_CH_faultConfinement 2 "BUS_OFF" 1 "ERROR_PASSIVE" 0 "ERROR_ACTIVE" ;
VAL_ 2047 GTW_deliveryStatus 1 "DELIVERED" 0 "NOT_DELIVERED" ;
VAL_ 2047 GTW_cabinPTCHeaterType 1 "NONE" 0 "BORGWARNER" ;
VAL_ 2047 GTW_rightHandDrive 1 "RIGHT" 0 "LEFT" ;
VAL_ 2047 GTW_rearLightType 2 "GLOBAL" 1 "EU_CN" 0 "NA" ;
VAL_ 2047 GTW_headlamps 2 "GLOBAL" 1 "PREMIUM" 0 "BASE" ;
VAL_ 2047 GTW_tireType 38 "HANKOOK_SUMMER_18" 37 "GITI_SUMMER_18" 36 "KUMHO_ALL_SEASON_18" 35 "GOODYEAR_ALL_SEASON_18" 34 "CONTI_SUMMER_19" 33 "BRIDGESTONE_ALL_SEASON_20" 32 "HANKOOK_ALL_SEASON_20" 31 "GOODYEAR_SUMMER_19" 30 "KUMHO_ALL_SEASON_19" 29 "HANKOOK_ALL_SEASON_21" 28 "PIRELLI_ALL_SEASON_19" 27 "GOODYEAR_ALL_SEASON_21" 26 "HANKOOK_ALL_SEASON_18" 25 "PIRELLI_ALL_SEASON_22" 24 "CONTI_SUMMER_22" 23 "CONTI_ALL_SEASON_20" 22 "MICHELIN_SUMMER_21" 21 "PIRELLI_SUMMER_20" 20 "PIRELLI_SUMMER_19" 19 "MICHELIN_ALL_SEASON_21" 18 "PIRELLI_SUMMER_21" 17 "GOODYEAR_ALL_SEASON_20" 16 "BRIDGESTONE_SUMMER_18" 7 "GOODYEAR_ALL_TERRAIN_20" 6 "PIRELLI_ALL_SEASON_20" 5 "MICHELIN_SUMMER_20" 4 "CONTI_ALL_SEASON_19" 3 "HANKOOK_SUMMER_19" 2 "MICHELIN_SUMMER_18" 1 "MICHELIN_ALL_SEASON_18" 0 "UNKNOWN" ;
VAL_ 2047 GTW_dasHw 5 "TESLA_AP4" 4 "TESLA_AP3" 3 "PARKER_PASCAL_2_5" ;
VAL_ 2047 GTW_brakeHWType 21 "HITACHI_P42_V2_MANDO_43MOC_LOW_DRAG" 20 "BREMBO_LARGE_P42_V2_MANDO_43MOC_LOW_DRAG" 18 "BREMBO_LARGE_P42_V2_BREMBO_44MOC_GA" 17 "HITACHI_P42_V2_MANDO_43MOC" 16 "BREMBO_P42LD_V2_MANDO_43MOC" 15 "BREMBO_P42LD_ZF_43MOC" 13 "BREMBO_P42_ZF_43MOC" 9 "BREMBO_P42_V2_MANDO_43MOC" 8 "BREMBO_LARGE_P42_V2_MANDO_43MOC" 7 "BREMBO_LARGE_P42_V2_BREMBO_LARGE_44MOC" 6 "BREMBO_LARGE_P42_V2_BREMBO_44MOC" 3 "BREMBO_LARGE_P42_BREMBO_LARGE_44MOC" 2 "BREMBO_LARGE_P42_MANDO_43MOC" 1 "BREMBO_LARGE_P42_BREMBO_44MOC" 0 "BREMBO_P42_MANDO_43MOC" ;
VAL_ 2047 GTW_restraintsHardwareType 239 "NA_NO_KAB_MYB" 238 "ROW_ECALL_E41_MYB" 237 "EU_ECALL_E41_MYB" 236 "NA_E41_MYB" 233 "NA_MYL" 232 "ECE_ECALL_PEDPRO_MYL" 89 "ROW_ECALL_PEDPRO_MYL" 88 "ROW_PEDPRO_MYB" 87 "ROW_PERF_ECALL_PEDPRO_MYB" 86 "EU_PERF_ECALL_PEDPRO_MYB" 85 "EU_ECALL_PEDPRO_MYB" 84 "ROW_ECALL_PEDPRO_MYB" 83 "ROW_MYB" 82 "ROW_ECALL_MYB" 81 "NA_MYB" ;
VAL_ 2047 GTW_drivetrainType 1 "AWD" 0 "RWD" ;
VAL_ 2047 GTW_radarHeaterType 1 "MODELY_BACKER_THIN_3M" 0 "NONE" ;
VAL_ 2047 GTW_exteriorTrimType 1 "SATIN_BLACK" 0 "STANDARD_CHROME" ;
VAL_ 2047 GTW_frontSeatHeaters 1 "KONGSBERG_LOW_POWER" 0 "NONE" ;
VAL_ 2047 GTW_rearSeatHeaters 1 "KONGSBERG_LOW_POWER" 0 "NONE" ;
VAL_ 2047 GTW_eCallAntennaHW 1 "MAIN_ANT_ONLY" 0 "BACKUP_OR_MAIN_ANT" ;
VAL_ 2047 GTW_homelinkType 1 "HOMELINK_V_OPT_2" 0 "NONE" ;
VAL_ 2047 GTW_vdcType 1 "TESLA_VDC" 0 "BOSCH_VDC" ;
VAL_ 2047 GTW_memoryMirrors 1 "SMR" 0 "NOT_INSTALLED" ;
VAL_ 2047 GTW_powerLiftgateType 2 "HUADE_REV1" 1 "TESLA_REV1" 0 "NOT_INSTALLED" ;
VAL_ 2047 GTW_lumbarECUType 10 "AEW_SINGLE_AXIS_DRIVER_ONLY_RHD" 9 "AEW_SINGLE_AXIS_DRIVER_ONLY_LHD" 8 "ND_DRIVER_ONLY_RHD" 7 "ND_DRIVER_ONLY_LHD" 6 "AEW_DRIVER_ONLY_RHD" 5 "AEW_DRIVER_ONLY_LHD" 4 "AEW" 3 "ALFMEIER_DRIVER_ONLY_RHD" 2 "ALFMEIER_DRIVER_ONLY_LHD" 1 "ALFMEIER" 0 "NONE" ;
VAL_ 2047 GTW_rearSeatHeaterType 3 "LEFT_RIGHT_ONLY_GENTHERM" 2 "NONE" 1 "LEFT_RIGHT_ONLY_KONGSBERG" ;
VAL_ 2047 GTW_auxParkLamps 3 "NONE" 2 "EU" 1 "NA_PREMIUM" 0 "NA_BASE" ;
VAL_ 2047 GTW_interiorCabinRadarType 1 "TESLA" 0 "NONE" ;
VAL_ 2047 GTW_hvacPanelVaneType 1 "CONVERGENT_V1" 0 "PARALLEL_V1" ;
VAL_ 2047 GTW_intakeAirFilterType 1 "HEPA" 0 "STANDARD" ;
VAL_ 2047 GTW_eBuckConfig 1 "DEV_BUCK" 0 "NONE" ;
VAL_ 2047 GTW_steeringHeaterEnabled 1 "ENABLED" 0 "DISABLED" ;
VAL_ 2047 GTW_activeHighBeam 1 "ACTIVE" 0 "NOT_ACTIVE" ;
VAL_ 2047 GTW_airbagCutoffSwitch 1 "CUTOFF_SWITCH_ENABLED" 0 "CUTOFF_SWITCH_DISABLED" ;
VAL_ 2047 GTW_intrusionSensorType 1 "VODAFONE" 0 "NOT_INSTALLED" ;
VAL_ 2047 GTW_spoilerType 1 "PASSIVE" 0 "NOT_INSTALLED" ;
VAL_ 2047 GTW_backupCameraType 1 "INTEGRATED_HEATER_V1" 0 "NO_HEATER" ;
VAL_ 2047 GTW_rearFogLamps 1 "INSTALLED" 0 "NOT_INSTALLED" ;
VAL_ 2047 GTW_roofType 1 "FIXED_GLASS" ;
VAL_ 2047 GTW_thirdRowSeatType 1 "FLAT_FOLD" 0 "NONE" ;
VAL_ 2047 GTW_autopilot 4 "BASIC" 3 "SELF_DRIVING" 2 "ENHANCED" 1 "HIGHWAY" 0 "NONE" ;
VAL_ 2047 GTW_superchargingAccess 2 "PAY_AS_YOU_GO" 1 "ALLOWED" 0 "NOT_ALLOWED" ;
VAL_ 2047 GTW_exteriorColor 20 "COASTAL_BLUE" 17 "MARINE_BLUE" 16 "SILKROAD_SILVER" 15 "DIAMOND_BLACK" 14 "GLACIER_BLUE" 13 "FROST_BLUE" 11 "STEALTH_GREY" 10 "ULTRA_RED" 9 "QUICKSILVER" 8 "ABYSS_BLUE" 7 "MIDNIGHT_CHERRY_RED" 6 "PEARL_WHITE" 5 "DEEP_BLUE" 3 "MIDNIGHT_SILVER" 2 "SILVER_METALLIC" 1 "SOLID_BLACK" 0 "RED_MULTICOAT" ;
VAL_ 2047 GTW_pedestrianWarningSound 2 "EXT_SPEAKER_V2" 1 "SPEAKER" 0 "NONE" ;
VAL_ 2047 GTW_steeringColumnUJointType 1 "C_SAMPLE_PHASING" ;
VAL_ 2047 GTW_bPillarNFCParam 1 "MODEL_Y" 0 "MODEL_3" ;
VAL_ 2047 GTW_interiorLighting 6 "FOOTWELL" 5 "FOOTWELL_RGB_IP" 4 "PREMIUM_WITH_RGB_IP_ONLY" 3 "PREMIUM_WITH_RGB" 2 "PREMIUM_NO_POCKET_LIGHT" 1 "PREMIUM" 0 "BASE" ;
VAL_ 2047 GTW_headlightLevelerType 2 "VIRTUAL_PITCH_SENSOR" 1 "GEN1" 0 "NONE" ;
VAL_ 2047 GTW_numberHVILNodes 3 "HVIL_NODES_3" 2 "HVIL_NODES_2" 0 "HVIL_NODES_0" ;
VAL_ 2047 GTW_mapRegion 13 "LA" 12 "IN" 11 "SE" 10 "MO" 9 "HK" 8 "ME" 7 "KR" 6 "TW" 5 "JP" 4 "AU" 3 "CN" 2 "NONE" 1 "EU" 0 "US" ;
VAL_ 2047 GTW_performancePackage 4 "BASE_2022" 3 "BASE_PLUS" 2 "BASE_2024" 1 "PERFORMANCE" 0 "BASE" ;
VAL_ 2047 GTW_chassisType 7 "MODEL_Y_LONG_WHEELBASE_CHASSIS_PATRONUS" 3 "MODEL_Y_CHASSIS" 2 "MODEL_3_CHASSIS" ;
VAL_ 2047 GTW_airSuspension 3 "COIL_ADAPTIVE_DAMPING" 0 "NONE" ;
VAL_ 2047 GTW_centerConsoleControllerType 2 "INSTALLED_NO_AIRWAVE" 1 "INSTALLED_V1" 0 "NONE" ;
VAL_ 2047 GTW_autopilotCameraType 1 "RGGB_CAMERAS" 0 "RCCB_CAMERAS" ;
VAL_ 2047 GTW_connectivityPackage 1 "PREMIUM" 0 "BASE" ;
VAL_ 2047 GTW_plcSupportType 2 "NATIVE_CHARGE_PORT" 1 "ONBOARD_ADAPTER" 0 "NONE" ;
VAL_ 2047 GTW_badgingVersion 2 "VERSION_2" 1 "VERSION_1" 0 "VERSION_0" ;
VAL_ 2047 GTW_packEnergy 2 "MR" 1 "LR" 0 "SR" ;
VAL_ 2047 GTW_frontSeatReclinerHardware 3 "LEFT_RIGHT_SEAT_REDUCED_RANGE" 2 "LEFT_SEAT_REDUCED_RANGE" 1 "RIGHT_SEAT_REDUCED_RANGE" 0 "STANDARD_RANGE" ;
VAL_ 2047 GTW_brakeLineSwitchType 1 "VC_ONLY" 0 "DI_VC_SHARED" ;
VAL_ 2047 GTW_softRange 4 "RANGE_260_MILES" 3 "RANGE_343_MILES" 2 "RANGE_93_MILES" 1 "RANGE_220_MILES" 0 "STANDARD" ;
VAL_ 2047 GTW_refrigerantType 2 "R1234YF" 1 "R134A" 0 "Default" ;
VAL_ 2047 GTW_wheelType 52 "UBERHELIX_20" 51 "GEMINI_19_DARK_STAGGERED" 50 "HELIX_V2_20_DARK" 48 "MACHINA_V2_19_STAGGERED" 47 "GLIDER_18_CAP_KIT" 46 "APERTURE_18" 41 "ARACHNID_V2_21" 40 "HELIX_V2_20" 39 "CROSSFLOW_19" 33 "WISHBONE_20_STAGGERED" 31 "HELIX_19" 30 "GLIDER_18" 27 "ZEROG_19_GUNPOWDER" 24 "PINWHEEL_REFRESH_18_CAP_KIT" 23 "UBERTURBINE_20_GUNPOWDER" 22 "PINWHEEL_REFRESH_18" 21 "STILETTO_REFRESH_19" 19 "ZEROG_20_GUNPOWDER" 18 "PINWHEEL_18_CAP_KIT" 14 "STILETTO_20_DARK_SQUARE" 5 "GEMINI_19_STAGGERED" 4 "GEMINI_19_SQUARE" 3 "STILETTO_20_DARK_STAGGERED" 2 "STILETTO_20" 1 "STILETTO_19" 0 "PINWHEEL_18" ;
VAL_ 2047 GTW_brakeActuationType 2 "ESP_DPB" 1 "IDB_RCU" 0 "ESP_IBST" ;
VAL_ 2047 GTW_secondRowSeatType 6 "TWO_SEATS_POWERED_RECLINE" 5 "FLAT_FOLD_V2" 4 "EASY_ENTRY_POWERED_RECLINE" 3 "POWERED_RECLINE" ;
VAL_ 2047 GTW_secondRowSeatMotorType 1 "KEIPER" 0 "SHB" ;
VAL_ 2047 GTW_eCallEnabled 2 "ENABLED_UI_SOS" 1 "ENABLED_OHC_SOS" 0 "DISABLED" ;
VAL_ 2047 GTW_parkAssistECUType 2 "NONE" 1 "TESLA" 0 "VALEO" ;
VAL_ 2047 GTW_passengerAirbagType 2 "EUROW" 1 "SAFETY_VENT" 0 "FULL_SUPPRESSION" ;
VAL_ 2047 GTW_forwardRadarHw 2 "NONE" 0 "CONTI_ARS410" ;
VAL_ 2047 GTW_frontSeatType 13 "PREMIUM_L_YANFENG_MINITILT_R_TESLA_MINITILT" 12 "PREMIUM_L_YANFENG_MINITILT_R_YANFENG_MINITILT" 11 "PREMIUM_L_YANFENG_MINITILT_R_YANFENG" 10 "PREMIUM_L_YANFENG_R_YANFENG_MINITILT" 9 "PREMIUM_L_TESLA_MINITILT_R_YANFENG_MINITILT" 8 "PREMIUM_L_TESLA_MINITILT_R_TESLA_MINITILT" 7 "PREMIUM_L_TESLA_MINITILT_R_TESLA" 6 "PREMIUM_L_TESLA_R_TESLA_MINITILT" 5 "PREMIUM_BROSE" 4 "PREMIUM_YANFENG" 3 "PREMIUM_L_TESLA_R_YANFENG" 2 "PREMIUM_L_YANFENG_R_TESLA" 1 "PREMIUM_TESLA" 0 "BASE_TESLA" ;
VAL_ 2047 GTW_secondRowDisplayType 1 "TYPE_1" 0 "NONE" ;
VAL_ 2047 GTW_wirelessPhoneChargerType 3 "FRONT_HIGH_POWER_UART" 1 "FRONT_LIN" 0 "NONE_OR_USB" ;
VAL_ 2047 GTW_ethernetTunerType 3 "HARMAN_GEN3" 2 "HIRSCHMANN" 1 "NONE" 0 "HARMAN" ;
VAL_ 2047 GTW_interiorTrimType 3 "WHITE_CONSOLE_2" 2 "BLACK_CONSOLE_2" 1 "WHITE" 0 "BLACK" ;
VAL_ 2047 GTW_gloveboxUSBType 2 "TSC_USB3_A_PLUS_BT" 1 "TSC_USB3_A" 0 "NOT_INSTALLED" ;
VAL_ 2047 GTW_coolantPumpType 5 "DUAL_MIX" 4 "DUAL_SAN_P4_LUB" 2 "DUAL_SAN_P4" 1 "SINGLE_PUMP_BATT" 0 "DUAL" ;
VAL_ 2047 GTW_epblHwType 8 "ZF" 5 "BREMBO_V2" 4 "BREMBO_V1" 2 "MANDO_V2" 1 "MANDO_V1" 0 "NOT_SET" ;
VAL_ 2047 GTW_epbrHwType 8 "ZF" 5 "BREMBO_V2" 4 "BREMBO_V1" 2 "MANDO_V2" 1 "MANDO_V1" 0 "NOT_SET" ;
VAL_ 2047 GTW_blowerMotorType 1 "DELTA" 0 "SHINANO" ;
VAL_ 2047 GTW_powerMirrorFoldType 1 "TYPE_1" 0 "NOT_INSTALLED" ;
VAL_ 2047 GTW_frontUsbHubType 4 "NO_DATA" 0 "2" ;
VAL_ 2047 GTW_superManifoldType 2 "TYPE2" 1 "TYPE1" 0 "TYPE0" ;
VAL_ 2047 GTW_rcmLocation 0 "CENTER_CONSOLE" ;
VAL_ 2047 GTW_autopilotExteriorCameraType 1 "IMX00N" 0 "DEFAULT_FOR_APHW" ;
VAL_ 2047 GTW_sirenType 1 "VODAPHONE_IF_INTRUSION" 0 "NONE" ;
VAL_ 2047 GTW_hornType 1 "EXT_SPEAKER_V2" 0 "TRUMPET" ;
VAL_ 2047 GTW_passengerTrackMotorType 1 "L_AND_V" 0 "INSTALLED_DEFAULT" ;
VAL_ 2047 GTW_steeringColumnMotorType 3 "NEXTEER" 2 "BOSCH_COMMON_TO_JE" 1 "JE" 0 "BOSCH" ;
VAL_ 2047 GTW_refrigACLineType 2 "CONTI_LIMITED" 1 "SAAA_LIMITED" 0 "UNLIMITED" ;
VAL_ 2047 GTW_refrigFilterType 2 "BLOCKED_V2" 1 "BLOCKED_V1" 0 "UNBLOCKED" ;
VAL_ 2047 GTW_diBurnInType 1 "ENABLED_V1" 0 "NONE" ;
VAL_ 2047 GTW_specialBadgingType 2 "LAUNCH_SERIES" 0 "NONE" ;
VAL_ 2047 GTW_chassisSubType 4 "MARKET_VARIANT_2" 3 "TRIM_DEVIATION_1" 2 "PERFORMANCE" 1 "BASE" 0 "UNKNOWN" ;
VAL_ 2047 GTW_towPackage 2 "TESLA_REV2" 1 "TESLA_REV1" 0 "NONE" ;
VAL_ 2047 GTW_refrigLccType 1 "LCCR" 0 "LCC" ;
VAL_ 2047 GTW_restraintControlsType 1 "TESLA" 0 "BOSCH" ;
VAL_ 2047 GTW_caliperColorType 2 "RED" 1 "GREY" 0 "UNKNOWN" ;
VAL_ 2047 GTW_wiperMotorType 1 "SHB" 0 "NOT_UPDATEABLE" ;
VAL_ 2047 GTW_frontOverheadConsoleType 3 "KOSTAL" 2 "PREH" 1 "BITRON" 0 "VALEO" ;
VAL_ 2047 GTW_shifterType 1 "DISPLAY" 0 "STALK" ;
VAL_ 2047 GTW_compressorType 10 "SANDEN_V4_1" 8 "SANDEN_V4" 7 "SANDEN_V3" 6 "SANDEN_V1_1" 5 "SANDEN_V2" 4 "DENSO_11K_COP1_ENABLED" 3 "SANDEN" 2 "DENSO_41CC_11K" 1 "DENSO_41CC_8K" 0 "HANON_33CC" ;
VAL_ 2047 GTW_twelveVBatteryType 3 "TESLA_16V_LI_ION" 2 "CATL_LI_ION" 1 "CLARIOS_B24_FLOODED" 0 "ATLASBX_B24_FLOODED" ;
VAL_ 2047 GTW_efuseSWConfig 3 "ALL_ENABLED" 2 "SQUARE_ENABLED" 1 "ROUND_ENABLED" 0 "DISABLED" ;
VAL_ 2047 GTW_tollCollectionModuleType 1 "WANJI_V1" 0 "NONE" ;
VAL_ 2047 GTW_bleEndpointUpdateMethod 1 "BOOTLOADER_UPDATE" ;
VAL_ 2047 GTW_steeringWheelControllerType 5 "DUAL_TESLA_GEN5" 2 "DUAL_KOSTAL" 1 "DUAL_PREH" ;
VAL_ 2047 GTW_frontSeatVentilationEnabled 1 "ENABLED" 0 "DISABLED" ;
VAL_ 2047 GTW_gloveboxActuatorType 2 "ELECTROMAGNET" 1 "SMA" 0 "SOLENOID" ;
VAL_ 2047 GTW_epasType 8 "THYSSENKRUPP_CGR65" 7 "MANDO_CGR65" 6 "THYSSENKRUPP_VGR69" 5 "MANDO_CGR69_SINGLE_ECU" 4 "MANDO_CGR69" 3 "MANDO_VGR69_GEN3_SINGLE_ECU" 0 "MANDO_VGR69_GEN3" ;
VAL_ 2047 GTW_homologationRegionOverride 2 "MX_UNECE" 1 "KR_UNECE" 0 "DEFAULT_FOR_COUNTRY_CODE" ;
VAL_ 2047 GTW_windowCommandsPermissionType 2 "US_FMVSS_S6" 1 "US_FMVSS_S4" 0 "ROW_OR_US_FMVSS_S5" ;
VAL_ 2047 GTW_rgbInteriorLightingEnabled 2 "ALL_COLORS" 1 "WHITE_ONLY" 0 "DISABLED_OR_NA" ;
VAL_ 2047 GTW_windshieldWiperHeaterType 1 "TYPE_1" 0 "NOT_INSTALLED" ;
VAL_ 2047 GTW_thirdRowSeatReclinerType 1 "POWERED_SHB" 0 "MANUAL_OR_NA" ;
VAL_ 2047 GTW_driveInterfaceType 1 "EXTERNAL" 0 "COMBINED" ;
VAL_ 2047 GTW_efficiencyPackage 42 "MY_2026_US" 39 "MY_2025_CN_PLUS" 38 "MY_2026_M53" 34 "MY_STANDARD_2026" 33 "MY_REFRESH_2025_CN_ALL_US_LR_RWD" 32 "MY_REFRESH_2025_ROW" 24 "MY_2024_GFSH_EXPORT_NA_SR_RWD" 23 "MY_2024C" 20 "MY_2023_SR_RWD" 16 "MY_2024" 15 "MY_2023_GFSH_EXPORT_NA" 12 "MY_RWD_EU_2022" 11 "MY_SR_PLUS_2022_Q1_TX" 9 "MY_SR_PLUS_2021_Q3_GFSH" 7 "MY_2021" 5 "MY_2020" 0 "DEFAULT" ;
VAL_ 2047 GTW_visorLightType 1 "DIMMABLE_TYPE_1" 0 "NON_DIMMABLE" ;
VAL_ 2047 GTW_gnssAntennaType 2 "GEN2_WITH_METAL_INSERT" 1 "GEN2_NO_METAL_INSERT" 0 "NA_OR_GEN1" ;
VAL_ 2047 GTW_airDistributionBoxType 1 "TYPE_1" 0 "NONE" ;
VAL_ 2047 GTW_frontSeatHeatersEnabled 1 "ENABLED" 0 "DISABLED" ;
VAL_ 2047 GTW_windshieldWiperHeaterEnabled 1 "ENABLED_OR_NA" 0 "DISABLED" ;
VAL_ 2047 GTW_alcoholInterlockType 1 "TYPE_1" 0 "NONE" ;
VAL_ 2047 GTW_fasciaType 8 "E41_BAYBERRY" 4 "PERFORMANCE_BAYBERRY" 3 "BASE_BAYBERRY" 0 "ORIGINAL" ;
VAL_ 2047 GTW_powerSteeringColumn 1 "TK" 0 "NOT_INSTALLED" ;
VAL_ 2047 GTW_frontSeatHeaterType 1 "GENTHERM" 0 "KONGSBERG" ;
VAL_ 2047 GTW_softPerformanceLimit 6 "LIMIT_230_KW" 4 "LIMIT_110_MPH" 2 "LIMIT_110_KW" 1 "LIMIT_160_KW" 0 "NONE" ;
VAL_ 2047 GTW_gsrFeatureType 2 "TYPE_2_GSR" 0 "NONE" ;
VAL_ 2047 GTW_immersiveAudio 2 "PREMIUM" 1 "BASE" 0 "DISABLED" ;
VAL_ 2047 GTW_frontSeatVentilationType 1 "TYPE_1" 0 "NONE" ;
VAL_ 2047 GTW_passengerOccupancySensorType 4 "NONE" 1 "RESISTIVE_PAD" 0 "OCS" ;
VAL_ 2047 GTW_packPerformanceDeviation 5 "PACK_POWER_DEVIATION_2" 4 "PACK_MASS_DEVIATION_2" 3 "PACK_STRUCTURAL_DEVIATION_1" 2 "PACK_POWER_DEVIATION_1" 1 "PACK_MASS_DEVIATION_1" 0 "NO_DEVIATION" ;
VAL_ 2047 GTW_frontFogLamps 1 "INSTALLED" 0 "NOT_INSTALLED" ;
VAL_ 2047 GTW_driverOccupancySensorType 1 "NONE" 0 "RESISTIVE_PAD" ;
VAL_ 2047 GTW_audioType 4 "ESSENTIAL_WITH_COMMODITY100" 3 "ESSENTIAL" 1 "PREMIUM" 0 "BASE" ;
VAL_ 2047 GTW_thighExtenderType 1 "YANFENG" 0 "NONE" ;
VAL_ 2047 GTW_occupancyClassificationFeatu 1 "TESLA_CABIN_RADAR" 0 "DISCRETE_SENSOR_OR_NA" ;
VAL_ 2047 GTW_frontControllerArchitectureT 1 "BETA_TYPE" 0 "ALPHA_TYPE" ;
VAL_ 2047 GTW_domeLightType 3 "2R_3R" 2 "2R" ;
VAL_ 2047 GTW_tpmsType 2 "INDIRECT" 1 "TESLA_BLE" 0 "CONTI_2" ;
VAL_ 2047 GTW_authenticationEndpointLayout 6 "M3_LAYOUT_3" 5 "MY_LAYOUT_3" 2 "MY_LAYOUT_2" 1 "M3_LAYOUT_2" 0 "LAYOUT_1" ;
VAL_ 2047 GTW_socSleepOverride 2 "FORCE_SHALLOW" 1 "FORCE_S3" 0 "PN_DERIVED" ;
VAL_ 2047 GTW_r79BehaviorOverride 1 "R79_ENABLED" 0 "NO_OVERRIDE" ;
VAL_ 2047 GTW_steeringHeaterType 7 "YF_V2" 4 "ZF_ROUND" 0 "NONE" ;
VAL_ 2047 GTW_narrowWipingSupported 1 "SUPPORTED" 0 "NOT_SUPPORTED" ;
VAL_ 2047 GTW_frontSeatHeaterGridType 1 "LARGER_SURFACE_AREA" 0 "STANDARD" ;
VAL_ 2047 GTW_frontSeatSideSwitchType 1 "NONE" 0 "STANDARD" ;
VAL_ 2047 GTW_sohRegulatoryStatus 1 "REGULATED_SOH" 0 "NON_REGULATED_SOH" ;
VAL_ 2047 GTW_passengerTiltMotorType 2 "MINITILT" 1 "NONE" 0 "INSTALLED_DEFAULT" ;
VAL_ 2047 GTW_frunkInteriorReleaseType 1 "NOT_INSTALLED" 0 "TYPE_1" ;
VAL_ 2047 GTW_m3yBusArchitecture 2 "PRIVATE_TORQUE_CHASSIS" 1 "PRIVATE_TORQUE" 0 "PUBLIC_TORQUE" ;
VAL_ 2047 GTW_passengerLiftMotorType 2 "BOSCH_KEIPER_COMMON" 1 "NONE" 0 "INSTALLED_DEFAULT" ;
VAL_ 2047 GTW_interiorUpperTrimType 1 "MAMMOTH_BLACK" 0 "POLAR_GREY" ;
VAL_ 2047 GTW_blindSpotIndicatorLightType 2 "INSTALLED_TYPE_2" 1 "INSTALLED_TYPE_1" 0 "NOT_INSTALLED" ;
VAL_ 2047 GTW_wiperMotorAsicType 2 "TYPE_2" 1 "TYPE_1" 0 "UNKNOWN_OR_NA" ;
VAL_ 2047 GTW_hvacCaseDoorType 1 "FLAT_EDGE" 0 "SERRATED_EDGE" ;
VAL_ 2047 GTW_rduCableType 1 "COPPER" 0 "ALUMINUM" ;
VAL_ 2047 GTW_parkTelltaleBehaviorType 1 "TYPE_1_REVISED_BEHAVIOR" 0 "LEGACY_BEHAVIOR" ;
VAL_ 2047 GTW_numberKeyCardsPairedInFactor 2 "2" 1 "1" ;
VAL_ 2047 GTW_secondRowSeatVentilationType 1 "TWO_SEATS_GENTHERM" 0 "NONE" ;
VAL_ 2047 GTW_thirdRowSeatHeaterType 1 "TWO_SEATS_KONGSBERG" 0 "NONE" ;
VAL_ 2047 GTW_interiorCameraType 2 "VD1942" 1 "VD6763" 0 "AR0136" ;
VAL_ 2047 GTW_frontFasciaCameraType 2 "IMX00N" 1 "IMX963" 0 "NONE" ;
VAL_ 2047 GTW_interiorCamFanType 3 "NIDEC" 2 "DELTA_FDB" 0 "NONE" ;
VAL_ 2047 GTW_puddleLampType 2 "INSTALLED_1R_ONLY_TYPE_1" 1 "INSTALLED_TYPE_1" 0 "NOT_INSTALLED" ;
VAL_ 2047 GTW_solarLensType 1 "PEGATRON" 0 "BCS" ;
VAL_ 2047 GTW_liftgateGeometryType 2 "TYPE_2" 1 "TYPE_1" 0 "DEFAULT" ;
VAL_ 2047 GTW_repeaterAeroRibType 4 "RETROFIT_OPTIMIZED" 3 "OPTIMIZED" 0 "UNOPTIMIZED" ;
VAL_ 2047 GTW_highTipForceWiperArmsType 1 "INSTALLED_TYPE_1" 0 "NOT_INSTALLED" ;
VAL_ 2047 GTW_rcmUndersideAbuseZThreshold 7 "threshold7" 6 "threshold6" 5 "threshold5" 4 "threshold4" 3 "threshold3" 2 "threshold2" 1 "threshold1" 0 "threshold0" ;
VAL_ 2047 GTW_rcmUndersideAbuseYThreshold 7 "threshold7" 6 "threshold6" 5 "threshold5" 4 "threshold4" 3 "threshold3" 2 "threshold2" 1 "threshold1" 0 "threshold0" ;
VAL_ 2047 GTW_rcmUndersideAbuseWindow 3 "window3" 2 "window2" 1 "window1" 0 "window0" ;
VAL_ 2047 GTW_automaticFeatureResetPackage 1 "TYPE_1" 0 "NONE" ;
VAL_ 2047 GTW_autopilotFeaturePackage 1 "TACC_AND_FSD_ONLY" 0 "LEGACY_AND_FSD" ;
VAL_ 2047 GTW_doorLatchType 1 "SELF_TESTABLE" 0 "DIGITAL" ;
VAL_ 2047 GTW_headlinerMaterialType 2 "POLYURETHANE_FIBERGLASS_LIGHT" 1 "POLYURETHANE_FIBERGLASS" 0 "POLYCARBONATE_ABS" ;
VAL_ 2047 GTW_glareShieldHeaterType 1 "TYPE_1" 0 "NONE" ;
VAL_ 2047 GTW_rearLightHardwareVariant 2 "V3" 1 "V2" 0 "V1" ;
VAL_ 2047 GTW_fasciaHarnessCleanPointType 2 "POST_CLEANPOINT" 1 "PRE_CLEANPOINT" 0 "UNKOWN" ;
VAL_ 2047 GTW_epasSubType 1 "GEN4" 0 "GEN3_OR_NA" ;
VAL_ 2047 GTW_wiperSupplyChainOrigin 2 "NA_SUPPLY_CHAIN" 1 "CN_SUPPLY_CHAIN" 0 "UNKNOWN_OR_SNA" ;
VAL_ 2047 GTW_windowPinchParameterType 2 "TYPE_2" 1 "TYPE_1" 0 "DEFAULT" ;
VAL_ 2047 GTW_badgingMaterialType 1 "BLACK_MATTE" 0 "CHROME_SILVER" ;
VAL_ 2047 GTW_mRecordVersion 1 "VER_2025" 0 "VER_2016_OR_NA" ;
VAL_ 2047 GTW_tcuType 1 "5G" 0 "4G" ;
VAL_ 2047 GTW_carbComplianceBehaviorType 1 "ACCII_2026_BEHAVIOR" 0 "NONE" ;
VAL_ 2047 GTW_indirectTPMSCalibrationType 4 "EXPERIMENTAL_V2" 3 "EXPERIMENTAL_V1_EU" 2 "EXPERIMENTAL_V1" 1 "STANDARD_EU" 0 "STANDARD" ;
VAL_ 2047 GTW_v2xEnabled 1 "DISABLED" 0 "ENABLED" ;
VAL_ 2047 GTW_liftgateStrutType 1 "TYPE_1" 0 "DEFAULT" ;
VAL_ 2047 GTW_exteriorMicrophoneType 1 "TWO_EXT_MICS" 0 "NONE" ;
VAL_ 2047 GTW_roofGlassType 4 "AG3" 3 "UNCOATED" 2 "NONE" 1 "TSA5_NOPET" 0 "TSA3_PET" ;
VAL_ 2047 GTW_pedalMapNameOverride 1 "CHILL_STANDARD" 0 "NO_OVERRIDE" ;
VAL_ 1638 GTW_diagLevel 100 "LEVEL_NORMAL_OPERATION" 80 "LEVEL_PARK" 70 "LEVEL_PARK_ROBOTAXI" 50 "LEVEL_SERVICE_DRIVE" 25 "LEVEL_SERVICE" 10 "LEVEL_DIAG_LINK_ACTIVE" 0 "LEVEL_FACTORY" ;
VAL_ 1080 GTW_ethWakeUpReason 17 "GTW_WAKEUP_REASON_TCU_TC10_VERSION_CHECK" 16 "GTW_WAKEUP_REASON_EGGLEFT_LINK_DOWN" 15 "GTW_WAKEUP_REASON_RCMPRIVATE_CAN" 14 "GTW_WAKEUP_REASON_VCLEFT" 13 "GTW_WAKEUP_REASON_LOOP" 12 "GTW_WAKEUP_REASON_DISPLAY_TAP" 11 "GTW_WAKEUP_REASON_URGENT_TRANSMIT_ALERT" 10 "GTW_WAKEUP_REASON_BDY_CAN" 9 "GTW_WAKEUP_REASON_PT_CAN" 8 "GTW_WAKEUP_REASON_UI_SCHEDULED" 7 "GTW_WAKEUP_REASON_RTC_ALARM" 6 "GTW_WAKEUP_REASON_VCFRONT" 5 "GTW_WAKEUP_REASON_VEH_CAN" 4 "GTW_WAKEUP_REASON_ETH_CAN" 3 "GTW_WAKEUP_REASON_CH_CAN" 2 "GTW_WAKEUP_REASON_GSM_RI" 1 "GTW_WAKEUP_REASON_RESET" 0 "GTW_WAKEUP_REASON_NONE" ;
VAL_ 1656 GTW_gearShiftRequest 4 "GEAR_REQUEST_DRIVE" 3 "GEAR_REQUEST_NEUTRAL" 2 "GEAR_REQUEST_REVERSE" 1 "GEAR_REQUEST_PARK" 0 "GEAR_REQUEST_IDLE_SNA" ;
VAL_ 1656 GTW_primaryGearControlStatus 14 "NOT_QUALIFIED_RHD_CONFIG_UNAVAILABLE" 13 "NOT_QUALIFIED_DISPLAY_KNOWN_FROZEN_SCREEN" 12 "NOT_QUALIFIED_DISPLAY_ASIL_VIDEO_ERROR" 11 "NOT_QUALIFIED_GEAR_STRIP_MISMATCH" 10 "NOT_QUALIFIED_DISPLAY_UNTRAINED" 9 "NOT_QUALIFIED_UI_NO_RESP_GEAR_STRIP" 8 "NOT_QUALIFIED_CENTER_DISP_UI_UNHEALTHY" 7 "NOT_QUALIFIED_DISPLAY_FROZEN_ON_GESTURE" 6 "NOT_QUALIFIED_LOW_BRIGHTNESS" 5 "NOT_QUALIFIED_FALSE_TOUCH" 4 "NOT_QUALIFIED_MANUAL" 3 "NOT_QUALIFIED_DISPLAY_ERRS" 2 "NOT_QUALIFIED_FULLSCREEN" 1 "QUALIFIED" 0 "NOT_QUALIFIED" ;
VAL_ 1656 GTW_autoParkRequest 1 "ACTIVE" 0 "IDLE" ;
VAL_ 1656 GTW_smartShiftStatus 9 "DISABLED_AUDIO_NOT_READY" 8 "DISABLED_OSD_ACTIVATED" 7 "DISABLED_DISQUALIFIED" 6 "DISABLED_FULLSCREEN" 5 "DISABLED_UI_MIA" 4 "DISABLED_CLUSTER_DISP_ERR" 3 "DISABLED_CENTER_DISP_ERR" 2 "DISABLED_UI_CONFIG" 1 "ENABLED" 0 "DISABLED_SNA" ;
VAL_ 1656 GTW_gearStripChangeReason 27 "EBUCK_DISABLE" 26 "SLEEP_DISABLE" 25 "VC_MIA_GRACE_DISABLE" 24 "VC_MIA_ENABLE" 23 "DRIVERLESS_NO_TAKEOVER_DISABLE" 22 "EMERGENCY_OPERATION_ENABLE" 21 "WOT_ENABLE" 20 "PARK_ENGAGED_ENABLE" 19 "MISSING_SPEED_OR_STEERING_ESTIMATE_IN_D_ENABLE" 18 "UI_MIA_ENABLE" 16 "NOT_DRIVE_STATE_DISABLE" 15 "FULLSCREEN_DISABLE" 14 "DEFAULT_DISABLE" 13 "REVERSE_ENABLE" 12 "NEUTRAL_ENABLE" 11 "P_AND_BRAKE_ENABLE" 10 "CHARGING_DISABLE" 9 "CRUISE_ACTIVE_DISABLE" 8 "DI_MIA_ENABLE" 7 "HIGH_ACCEL_DISABLE" 6 "MEDIUM_SPEED_DISABLE" 5 "TRAFFIC_CONTROL_NO_CHANGE" 4 "VERY_LOW_SPEED_ENABLE" 3 "HIGH_STEERING_ANGLE_ENABLE" 2 "HIGH_JERK_ENABLE" 1 "DRIVER_BRAKE_APPLY_ENABLE" 0 "SNA" ;
VAL_ 1656 GTW_screenPCBTemperature 2047 "GTW_I2C_TEMP_SNA" ;
VAL_ 2033 GTW_hrlIndex 2 "Mux2" 1 "Mux1" ;
VAL_ 2033 GTW_hrlSdCardSizeGB 0 "SNA" ;
VAL_ 2033 GTW_hrlState 1 "ENABLED" 0 "DISABLED" ;
VAL_ 2033 GTW_hrlTriggerType 15 "HRL_TRIGGER_NONE" 5 "HRL_TRIGGER_EVENT_EXTERNAL" 4 "HRL_TRIGGER_PSEUDONYMOUS" 3 "HRL_TRIGGER_CONTINUOUS" 2 "HRL_TRIGGER_GAME_MODE" 1 "HRL_TRIGGER_EVENT" 0 "HRL_TRIGGER_UDPAPI" ;
VAL_ 60 GTW_infoIndex 255 "END" 31 "SUBCOMPONENT_GITHASH" 30 "PACKAGE_SN_8_14" 29 "PACKAGE_SN_1_7" 27 "PACKAGE_PN_15_20" 26 "PACKAGE_PN_8_14" 25 "PACKAGE_PN_1_7" 23 "SUBCOMPONENT2" 22 "VARIANTCRC" 20 "UDS_PROTOCOL_BOOTCRC" 19 "VERSION_DEPRECATED" 18 "BOOTLOADER_GITHASH" 17 "APP_GITHASH" 16 "SUBCOMPONENT" 15 "BOOTLOADER_CRC" 14 "BOOTLOADER_SVN" 13 "APP_CRC" 11 "PCBAID_ASSYID_USAGEID" 10 "BUILD_HWID_COMPONENTID" 9 "DEPRECATED_9" 8 "DEPRECATED_8" 7 "DEPRECATED_7" 6 "DEPRECATED_6" 5 "DEPRECATED_5" 4 "DEPRECATED_4" 3 "DEPRECATED_3" 2 "DEPRECATED_2" 1 "DEPRECATED_1" 0 "DEPRECATED_0" ;
VAL_ 60 GTW_buildType 4 "INFO_MFG_BUILD" 3 "INFO_TRACEABLE_CI_BUILD" 2 "INFO_LOCAL_BUILD" 1 "INFO_PLATFORM_BUILD" 0 "INFO_UNKNOWN_BUILD" ;
VAL_ 60 GTW_platformType 255 "GTW_PLATFORM_END" 3 "GTW_PLATFORM_MODEL3" 0 "GTW_PLATFORM_UNKNOWN" ;
VAL_ 1370 GTW_mismatchFaultIndex 5 "Mux5" 4 "Mux4" 3 "Mux3" 2 "Mux2" 1 "Mux1" ;
VAL_ 840 GTW_vehicleVersionMatchStatus 2 "MATCHED" 1 "MISMATCHED" 0 "NOT_CALCULATED_YET" ;
VAL_ 840 GTW_hwtype 3 "TRAVEO2" 2 "SPC58" 1 "MPC57" 0 "SNA" ;
VAL_ 840 GTW_jcanProductName 11 "SEMITRUCKV2" 10 "GOLDENSNITCH" 8 "BAYBERRY" 7 "CYBERTRUCK" 6 "POPPYSEED" 5 "SEMITRUCK" 4 "TAMARIND" 3 "LYCHEE" 2 "MODELY" 1 "MODEL3" 0 "SNA" ;
VAL_ 840 GTW_touchcoreOsType 1 "GTW_OS_RT" 0 "GTW_OS_FREERTOS" ;
VAL_ 840 GTW_sentryModeState 6 "SNA" 5 "QUIET" 4 "PANIC" 3 "AWARE" 2 "ARMED" 1 "IDLE" 0 "OFF" ;
VAL_ 840 GTW_secureBootEnabled 1 "TRUE" 0 "FALSE" ;
VAL_ 840 GTW_socSleepType 2 "SHALLOW" 1 "S3" 0 "SNA" ;
VAL_ 840 GTW_resetType 8 "OTHER" 7 "TOUCHCORE_WATCHDOG" 6 "CANCORE_WATCHDOG" 5 "MAINCORE_WATCHDOG" 4 "WAKE" 3 "BUTTON" 2 "SOFTWARE" 1 "POR" 0 "SNA" ;
VAL_ 1005 GTW_peripheralConfirmedUpdateNee 3 "UPDATE_CONDITIONS_NOT_CORRECT" 2 "UPDATE_NOT_NEEDED" 1 "UPDATE_NEEDED" 0 "UNKNOWN" ;
VAL_ 1112 GTW_nmKeepAwakeReason 15 "GTW_KEEPAWAKE_REASON_TBD" 7 "GTW_KEEPAWAKE_REASON_TCU_TC10_VERSION_UNSUPPORTED" 6 "GTW_KEEPAWAKE_REASON_TCU_TC10_VERSION_CHECK" 5 "GTW_KEEPAWAKE_REASON_EGGLEFT_LINK_DOWN" 4 "GTW_KEEPAWAKE_REASON_URGENT_TRANSMIT_ALERT" 3 "GTW_KEEPAWAKE_REASON_FCSM_ACTIVE" 2 "GTW_KEEPAWAKE_REASON_GSM_RI" 1 "GTW_KEEPAWAKE_REASON_UI_SCHEDULED" 0 "GTW_KEEPAWAKE_REASON_NONE_SNA" ;
VAL_ 1112 GTW_nmWakeUpReason 17 "GTW_WAKEUP_REASON_TCU_TC10_VERSION_CHECK" 16 "GTW_WAKEUP_REASON_EGGLEFT_LINK_DOWN" 15 "GTW_WAKEUP_REASON_RCMPRIVATE_CAN" 14 "GTW_WAKEUP_REASON_VCLEFT" 13 "GTW_WAKEUP_REASON_LOOP" 12 "GTW_WAKEUP_REASON_DISPLAY_TAP" 11 "GTW_WAKEUP_REASON_URGENT_TRANSMIT_ALERT" 10 "GTW_WAKEUP_REASON_BDY_CAN" 9 "GTW_WAKEUP_REASON_PT_CAN" 8 "GTW_WAKEUP_REASON_UI_SCHEDULED" 7 "GTW_WAKEUP_REASON_RTC_ALARM" 6 "GTW_WAKEUP_REASON_VCFRONT" 5 "GTW_WAKEUP_REASON_VEH_CAN" 4 "GTW_WAKEUP_REASON_ETH_CAN" 3 "GTW_WAKEUP_REASON_CH_CAN" 2 "GTW_WAKEUP_REASON_GSM_RI" 1 "GTW_WAKEUP_REASON_RESET" 0 "GTW_WAKEUP_REASON_NONE" ;
VAL_ 1112 GTW_ethKeepAwakeReason 3 "TCU_TC10_VERSION_UNSUPPORTED" 2 "TCU_TC10_VERSION_CHECK" 1 "URGENT_TRANSMIT_ALERT" 0 "NONE_SNA" ;
VAL_ 1112 GTW_nmDebugWakeUp 2147483648 "WKPU_31" 1073741824 "WKPU_30" 536870912 "WKPU_29" 268435456 "WKPU_28" 134217728 "WKPU_27" 67108864 "WKPU_26" 33554432 "WKPU_25" 16777216 "WKPU_24" 8388608 "WKPU_23" 4194304 "WKPU_22" 2097152 "WKPU_21" 1048576 "WKPU_20" 524288 "WKPU_19" 262144 "WKPU_18" 131072 "WKPU_17" 65536 "WKPU_16" 32768 "WKPU_15" 16384 "WKPU_14" 8192 "WKPU_13" 4096 "WKPU_12" 2048 "WKPU_11" 1024 "WKPU_10" 512 "WKPU_9" 256 "WKPU_8" 128 "WKPU_7" 64 "WKPU_6" 32 "WKPU_5" 16 "WKPU_4" 8 "WKPU_3" 4 "WKPU_2" 2 "WKPU_1" 1 "WKPU_0" 0 "WKPU_NONE" ;
VAL_ 828 IDB_infoIndex 255 "END" 31 "SUBCOMPONENT_GITHASH" 30 "PACKAGE_SN_8_14" 29 "PACKAGE_SN_1_7" 27 "PACKAGE_PN_15_20" 26 "PACKAGE_PN_8_14" 25 "PACKAGE_PN_1_7" 23 "SUBCOMPONENT2" 22 "VARIANTCRC" 20 "UDS_PROTOCOL_BOOTCRC" 19 "VERSION_DEPRECATED" 18 "BOOTLOADER_GITHASH" 17 "APP_GITHASH" 16 "SUBCOMPONENT" 15 "BOOTLOADER_CRC" 14 "BOOTLOADER_SVN" 13 "APP_CRC" 11 "PCBAID_ASSYID_USAGEID" 10 "BUILD_HWID_COMPONENTID" 9 "DEPRECATED_9" 8 "DEPRECATED_8" 7 "DEPRECATED_7" 6 "DEPRECATED_6" 5 "DEPRECATED_5" 4 "DEPRECATED_4" 3 "DEPRECATED_3" 2 "DEPRECATED_2" 1 "DEPRECATED_1" 0 "DEPRECATED_0" ;
VAL_ 1415 TCU2_tc10Version 2 "TCU_tc10Version_FINAL_1_0" 1 "TCU_tc10Version_DRAFT" 0 "SNA" ;
VAL_ 1412 TCU2_logMux 30 "wakeSource" 29 "mdmBand" 28 "checkInternetFailCount" 27 "tcuSMState" 26 "cellularSMState" 25 "mdmDataCallTermCode" 24 "mdmDataCallTermReason" 23 "mdmTxKiloBytes" 22 "mdmMcc" 21 "mdmMnc" 20 "mdmPCIID" 19 "mdmNSAAvailable" 18 "mdmDataCallStatus" 17 "mdmDataRat" 16 "modemUptime" 15 "mdmBusyActive" 14 "mdmSIMStatus" 13 "mdmIMSStatus" 12 "mdmServiceState" 11 "mdmUplinkAvgRate" 10 "mdmUplinkAllowedRate" 9 "mdmSINR" 8 "mdmRSRP" 7 "mdmUplinkQueueSize" 6 "totalResumes" 5 "pwmcap" 4 "pwm" 3 "availableMemory" 2 "mdmCoreTemperature" 1 "cpuUsage" 0 "cpuTemp" ;
VAL_ 1412 TCU2_mdmBusyActive 4294967295 "SNA" ;
VAL_ 1412 TCU2_mdmDataRat 6 "RAT_NR5G_UNKNOWN" 5 "RAT_NR5G_SA" 4 "RAT_NR5G_NSA" 3 "RAT_LTE" 2 "RAT_WCDMA" 1 "RAT_GSM" 0 "RAT_UNKNOWN" ;
VAL_ 1412 TCU2_mdmDataCallStatus 4 "DISCONNECTED" 3 "DISCONNECTING" 2 "CONNECTED" 1 "CONNECTING" 0 "UNKNOWN" ;
VAL_ 1412 TCU2_mdmNSAAvailable 2 "NSA_NOT_AVAILABLE" 1 "NSA_AVAILABLE" 0 "NSA_UNKNOWN" ;
VAL_ 1412 TCU2_cellularSMState 7 "RECOVERING" 6 "LINK_CONNECTED" 5 "CHECKING_INTERNET" 4 "DATA_CONNECTED" 3 "IN_SERVICE" 2 "OUT_OF_SERVICE" 1 "WAITING_COMPONENT" 0 "UNKNOWN" ;
VAL_ 1412 TCU2_tcuSMState 7 "UPDATING" 6 "RESUMING" 5 "SUSPENDED" 4 "PREPARING_SLEEP" 3 "POWER_CYCLING" 2 "IN_OPERATION" 1 "SEARCHING_COMPONENT" 0 "UNKNOWN" ;
VAL_ 1412 TCU2_wakeSource 3 "ETHERNET" 2 "WOIP" 1 "SMS" 0 "NONE" ;
VAL_ 1159 TCU_tc10Version 2 "TCU_tc10Version_FINAL_1_0" 1 "TCU_tc10Version_DRAFT" 0 "SNA" ;
VAL_ 1155 TCU_logMux 30 "wakeSource" 29 "mdmBand" 28 "checkInternetFailCount" 27 "tcuSMState" 26 "cellularSMState" 25 "mdmDataCallTermCode" 24 "mdmDataCallTermReason" 23 "mdmTxKiloBytes" 22 "mdmMcc" 21 "mdmMnc" 20 "mdmPCIID" 19 "mdmNSAAvailable" 18 "mdmDataCallStatus" 17 "mdmDataRat" 16 "modemUptime" 15 "mdmBusyActive" 14 "mdmSIMStatus" 13 "mdmIMSStatus" 12 "mdmServiceState" 11 "mdmUplinkAvgRate" 10 "mdmUplinkAllowedRate" 9 "mdmSINR" 8 "mdmRSRP" 7 "mdmUplinkQueueSize" 6 "totalResumes" 5 "pwmcap" 4 "pwm" 3 "availableMemory" 2 "mdmCoreTemperature" 1 "cpuUsage" 0 "cpuTemp" ;
VAL_ 1155 TCU_mdmBusyActive 4294967295 "SNA" ;
VAL_ 1155 TCU_mdmDataRat 6 "RAT_NR5G_UNKNOWN" 5 "RAT_NR5G_SA" 4 "RAT_NR5G_NSA" 3 "RAT_LTE" 2 "RAT_WCDMA" 1 "RAT_GSM" 0 "RAT_UNKNOWN" ;
VAL_ 1155 TCU_mdmDataCallStatus 4 "DISCONNECTED" 3 "DISCONNECTING" 2 "CONNECTED" 1 "CONNECTING" 0 "UNKNOWN" ;
VAL_ 1155 TCU_mdmNSAAvailable 2 "NSA_NOT_AVAILABLE" 1 "NSA_AVAILABLE" 0 "NSA_UNKNOWN" ;
VAL_ 1155 TCU_cellularSMState 7 "RECOVERING" 6 "LINK_CONNECTED" 5 "CHECKING_INTERNET" 4 "DATA_CONNECTED" 3 "IN_SERVICE" 2 "OUT_OF_SERVICE" 1 "WAITING_COMPONENT" 0 "UNKNOWN" ;
VAL_ 1155 TCU_tcuSMState 7 "UPDATING" 6 "RESUMING" 5 "SUSPENDED" 4 "PREPARING_SLEEP" 3 "POWER_CYCLING" 2 "IN_OPERATION" 1 "SEARCHING_COMPONENT" 0 "UNKNOWN" ;
VAL_ 1155 TCU_wakeSource 3 "ETHERNET" 2 "WOIP" 1 "SMS" 0 "NONE" ;
